VERSION ""

NS_ :

BS_:

BU_: Receiver ChassisBus VehicleBus PartyBus apb ui app aps bms gtwu odin cc cmp cp das dif dir di epas3p epas3s epbl epbr esp fc gtw hvp ibst ocs1p park pcs pmf pmr pm ptc radc rcm2 rcm sccm scm scs tas tpms umc vcfront vcleft vcright vcsec

BO_ 12 ID00CUI_status: 8 VehicleBus
 SG_ UI_audioActive : 1|1@1+ (1,0) [0|1] ""  Receiver
 SG_ UI_autopilotTrial : 12|2@1+ (1,0) [0|3] ""  Receiver
 SG_ UI_bluetoothActive : 2|1@1+ (1,0) [0|1] ""  Receiver
 SG_ UI_cameraActive : 41|1@1+ (1,0) [0|1] ""  Receiver
 SG_ UI_cellActive : 3|1@1+ (1,0) [0|1] ""  Receiver
 SG_ UI_cellConnected : 10|1@1+ (1,0) [0|1] ""  Receiver
 SG_ UI_cellNetworkTechnology : 19|4@1+ (1,0) [0|15] ""  Receiver
 SG_ UI_cellReceiverPower : 24|8@1+ (1,-128) [-128|127] "dB"  Receiver
 SG_ UI_cellSignalBars : 42|3@1+ (1,0) [0|7] ""  Receiver
 SG_ UI_cpuTemperature : 56|8@1- (1,40) [-20|100] "C"  Receiver
 SG_ UI_developmentCar : 40|1@1+ (1,0) [0|1] ""  Receiver
 SG_ UI_displayOn : 5|1@1+ (1,0) [0|1] ""  Receiver
 SG_ UI_displayReady : 4|1@1+ (1,0) [0|1] ""  Receiver
 SG_ UI_factoryReset : 14|2@1+ (1,0) [0|3] ""  Receiver
 SG_ UI_falseTouchCounter : 32|8@1+ (1,0) [0|255] "1"  Receiver
 SG_ UI_gpsActive : 16|1@1+ (1,0) [0|1] ""  Receiver
 SG_ UI_pcbTemperature : 48|8@1- (1,40) [-20|100] "C"  Receiver
 SG_ UI_radioActive : 18|1@1+ (1,0) [0|1] ""  Receiver
 SG_ UI_readyForDrive : 9|1@1+ (1,0) [0|1] ""  Receiver
 SG_ UI_screenshotActive : 17|1@1+ (1,0) [0|1] ""  Receiver
 SG_ UI_systemActive : 8|1@1+ (1,0) [0|1] ""  Receiver
 SG_ UI_touchActive : 0|1@1+ (1,0) [0|1] ""  Receiver
 SG_ UI_vpnActive : 11|1@1+ (1,0) [0|1] ""  Receiver
 SG_ UI_wifiActive : 6|1@1+ (1,0) [0|1] ""  Receiver
 SG_ UI_wifiConnected : 7|1@1+ (1,0) [0|1] ""  Receiver

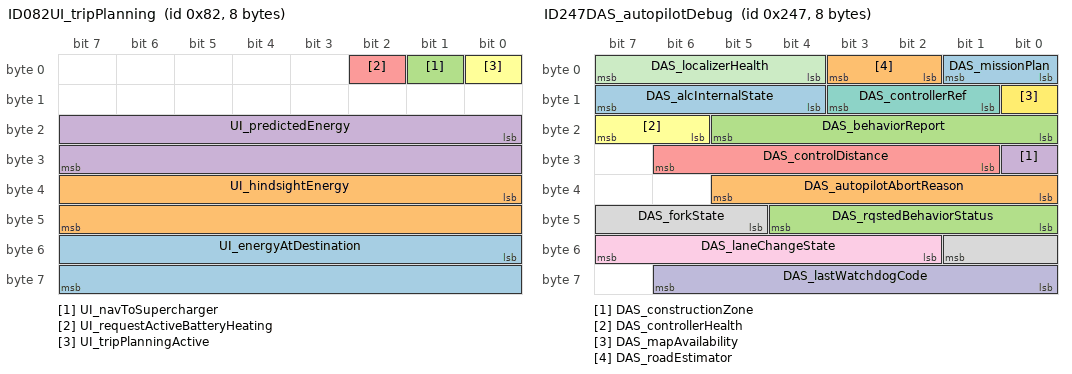
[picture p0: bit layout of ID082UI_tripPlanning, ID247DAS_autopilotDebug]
BO_ 130 ID082UI_tripPlanning: 8 VehicleBus
 SG_ UI_energyAtDestination : 48|16@1- (0.01,0) [-327.67|327.67] "kWh"  Receiver
 SG_ UI_hindsightEnergy : 32|16@1- (0.01,0) [-327.67|327.67] "kWh"  Receiver
 SG_ UI_navToSupercharger : 1|1@1+ (1,0) [0|1] ""  Receiver
 SG_ UI_predictedEnergy : 16|16@1- (0.01,0) [-327.67|327.67] "kWh"  Receiver
 SG_ UI_requestActiveBatteryHeating : 2|1@1+ (1,0) [0|1] ""  Receiver
 SG_ UI_tripPlanningActive : 0|1@1+ (1,0) [0|1] ""  Receiver

BO_ 258 ID102VCLEFT_doorStatus: 8 VehicleBus
 SG_ VCLEFT_frontHandlePWM : 16|7@1+ (1,0) [0|100] "%"  Receiver
 SG_ VCLEFT_frontHandlePulled : 10|1@1+ (1,0) [0|1] ""  Receiver
 SG_ VCLEFT_frontHandlePulledPersist : 62|1@1+ (1,0) [0|1] ""  Receiver
 SG_ VCLEFT_frontIntSwitchPressed : 31|1@1+ (1,0) [0|1] ""  Receiver
 SG_ VCLEFT_frontLatchStatus : 0|4@1+ (1,0) [0|8] ""  Receiver
 SG_ VCLEFT_frontLatchSwitch : 8|1@1+ (1,0) [0|1] ""  Receiver
 SG_ VCLEFT_frontRelActuatorSwitch : 12|1@1+ (1,0) [0|1] ""  Receiver
 SG_ VCLEFT_mirrorDipped : 61|1@1+ (1,0) [0|1] ""  Receiver
 SG_ VCLEFT_mirrorFoldState : 52|3@1+ (1,0) [0|4] ""  Receiver
 SG_ VCLEFT_mirrorHeatState : 58|3@1+ (1,0) [0|4] ""  Receiver
 SG_ VCLEFT_mirrorRecallState : 55|3@1+ (1,0) [0|5] ""  Receiver
 SG_ VCLEFT_mirrorState : 49|3@1+ (1,0) [0|4] ""  Receiver
 SG_ VCLEFT_mirrorTiltXPosition : 33|8@1+ (0.02,0) [0|5] "V"  Receiver
 SG_ VCLEFT_mirrorTiltYPosition : 41|8@1+ (0.02,0) [0|5] "V"  Receiver
 SG_ VCLEFT_rearHandlePWM : 24|7@1+ (1,0) [0|100] "%"  Receiver
 SG_ VCLEFT_rearHandlePulled : 11|1@1+ (1,0) [0|1] ""  Receiver
 SG_ VCLEFT_rearIntSwitchPressed : 32|1@1+ (1,0) [0|1] ""  Receiver
 SG_ VCLEFT_rearLatchStatus : 4|4@1+ (1,0) [0|8] ""  Receiver
 SG_ VCLEFT_rearLatchSwitch : 9|1@1+ (1,0) [0|1] ""  Receiver
 SG_ VCLEFT_rearRelActuatorSwitch : 13|1@1+ (1,0) [0|1] ""  Receiver

BO_ 259 ID103VCRIGHT_doorStatus: 8 VehicleBus
 SG_ VCRIGHT_frontHandlePWM : 14|7@1+ (1,0) [0|100] "%"  Receiver
 SG_ VCRIGHT_frontHandlePulled : 10|1@1+ (1,0) [0|1] ""  Receiver
 SG_ VCRIGHT_frontHandlePulledPersist : 30|1@1+ (1,0) [0|1] ""  Receiver
 SG_ VCRIGHT_frontIntSwitchPressed : 31|1@1+ (1,0) [0|1] ""  Receiver
 SG_ VCRIGHT_frontLatchStatus : 0|4@1+ (1,0) [0|8] ""  Receiver
 SG_ VCRIGHT_frontLatchSwitch : 8|1@1+ (1,0) [0|1] ""  Receiver
 SG_ VCRIGHT_frontRelActuatorSwitch : 12|1@1+ (1,0) [0|1] ""  Receiver
 SG_ VCRIGHT_mirrorDipped : 63|1@1+ (1,0) [0|1] ""  Receiver
 SG_ VCRIGHT_mirrorFoldState : 52|3@1+ (1,0) [0|4] ""  Receiver
 SG_ VCRIGHT_mirrorRecallState : 60|3@1+ (1,0) [0|5] ""  Receiver
 SG_ VCRIGHT_mirrorState : 49|3@1+ (1,0) [0|4] ""  Receiver
 SG_ VCRIGHT_mirrorTiltXPosition : 33|8@1+ (0.02,0) [0|5] "V"  Receiver
 SG_ VCRIGHT_mirrorTiltYPosition : 41|8@1+ (0.02,0) [0|5] "V"  Receiver
 SG_ VCRIGHT_rearHandlePWM : 21|7@1+ (1,0) [0|100] "%"  Receiver
 SG_ VCRIGHT_rearHandlePulled : 11|1@1+ (1,0) [0|1] ""  Receiver
 SG_ VCRIGHT_rearIntSwitchPressed : 32|1@1+ (1,0) [0|1] ""  Receiver
 SG_ VCRIGHT_rearLatchStatus : 4|4@1+ (1,0) [0|8] ""  Receiver
 SG_ VCRIGHT_rearLatchSwitch : 9|1@1+ (1,0) [0|1] ""  Receiver
 SG_ VCRIGHT_rearRelActuatorSwitch : 13|1@1+ (1,0) [0|1] ""  Receiver
 SG_ VCRIGHT_reservedForBackCompat : 28|2@1+ (1,0) [0|3] ""  Receiver
 SG_ VCRIGHT_trunkLatchStatus : 56|4@1+ (1,0) [0|8] ""  Receiver

BO_ 291 ID123UI_alertMatrix1: 8 VehicleBus
 SG_ UI_a001_DriverDoorOpen : 0|1@1+ (1,0) [0|1] ""  Receiver
 SG_ UI_a002_DoorOpen : 1|1@1+ (1,0) [0|1] ""  Receiver
 SG_ UI_a003_TrunkOpen : 2|1@1+ (1,0) [0|1] ""  Receiver
 SG_ UI_a004_FrunkOpen : 3|1@1+ (1,0) [0|1] ""  Receiver
 SG_ UI_a005_HeadlightsOnDoorOpen : 4|1@1+ (1,0) [0|1] ""  Receiver
 SG_ UI_a006_RemoteServiceAlert : 5|1@1+ (1,0) [0|1] ""  Receiver
 SG_ UI_a007_SoftPackConfigMismatch : 6|1@1+ (1,0) [0|1] ""  Receiver
 SG_ UI_a008_TouchScreenError : 7|1@1+ (1,0) [0|1] ""  Receiver
 SG_ UI_a009_SquashfsError : 8|1@1+ (1,0) [0|1] ""  Receiver
 SG_ UI_a010_MapsMissing : 9|1@1+ (1,0) [0|1] ""  Receiver
 SG_ UI_a011_IncorrectMap : 10|1@1+ (1,0) [0|1] ""  Receiver
 SG_ UI_a012_NotOnPrivateProperty : 11|1@1+ (1,0) [0|1] ""  Receiver
 SG_ UI_a013_TPMSHardWarning : 12|1@1+ (1,0) [0|1] ""  Receiver
 SG_ UI_a014_TPMSSoftWarning : 13|1@1+ (1,0) [0|1] ""  Receiver
 SG_ UI_a015_TPMSOverPressureWarning : 14|1@1+ (1,0) [0|1] ""  Receiver
 SG_ UI_a016_TPMSTemperatureWarning : 15|1@1+ (1,0) [0|1] ""  Receiver
 SG_ UI_a017_TPMSSystemFault : 16|1@1+ (1,0) [0|1] ""  Receiver
 SG_ UI_a018_SlipStartOn : 17|1@1+ (1,0) [0|1] ""  Receiver
 SG_ UI_a019_ParkBrakeFault : 18|1@1+ (1,0) [0|1] ""  Receiver
 SG_ UI_a020_SteeringReduced : 19|1@1+ (1,0) [0|1] ""  Receiver
 SG_ UI_a021_RearSeatbeltUnbuckled : 20|1@1+ (1,0) [0|1] ""  Receiver
 SG_ UI_a022_ApeFusesEtc : 21|1@1+ (1,0) [0|1] ""  Receiver
 SG_ UI_a023_CellInternetCheckFailed : 22|1@1+ (1,0) [0|1] ""  Receiver
 SG_ UI_a024_WifiInternetCheckFailed : 23|1@1+ (1,0) [0|1] ""  Receiver
 SG_ UI_a025_WifiOnlineCheckFailed : 24|1@1+ (1,0) [0|1] ""  Receiver
 SG_ UI_a026_ModemResetLoopDetected : 25|1@1+ (1,0) [0|1] ""  Receiver
 SG_ UI_a027_AutoSteerMIA : 26|1@1+ (1,0) [0|1] ""  Receiver
 SG_ UI_a028_FrontTrunkPopupClosed : 27|1@1+ (1,0) [0|1] ""  Receiver
 SG_ UI_a029_ModemMIA : 28|1@1+ (1,0) [0|1] ""  Receiver
 SG_ UI_a030_ModemVMCrash : 29|1@1+ (1,0) [0|1] ""  Receiver
 SG_ UI_a031_BrakeFluidLow : 30|1@1+ (1,0) [0|1] ""  Receiver
 SG_ UI_a032_CellModemRecoveryResets : 31|1@1+ (1,0) [0|1] ""  Receiver
 SG_ UI_a033_ApTrialExpired : 32|1@1+ (1,0) [0|1] ""  Receiver
 SG_ UI_a034_WakeupProblem : 33|1@1+ (1,0) [0|1] ""  Receiver
 SG_ UI_a035_AudioWatchdogKernelError : 34|1@1+ (1,0) [0|1] ""  Receiver
 SG_ UI_a036_AudioWatchdogHfpError : 35|1@1+ (1,0) [0|1] ""  Receiver
 SG_ UI_a037_AudioWatchdogXrunStormEr : 36|1@1+ (1,0) [0|1] ""  Receiver
 SG_ UI_a038_AudioWatchdogA2bI2cLocku : 37|1@1+ (1,0) [0|1] ""  Receiver
 SG_ UI_a039_AudioA2bNeedRediscovery : 38|1@1+ (1,0) [0|1] ""  Receiver
 SG_ UI_a040_HomelinkTransmit : 39|1@1+ (1,0) [0|1] ""  Receiver
 SG_ UI_a041_AudioDmesgXrun : 40|1@1+ (1,0) [0|1] ""  Receiver
 SG_ UI_a042_AudioDmesgRtThrottling : 41|1@1+ (1,0) [0|1] ""  Receiver
 SG_ UI_a043_InvalidMapDataOverride : 42|1@1+ (1,0) [0|1] ""  Receiver
 SG_ UI_a044_AudioDmesgDspException : 43|1@1+ (1,0) [0|1] ""  Receiver
 SG_ UI_a045_ECallNeedsService : 44|1@1+ (1,0) [0|1] ""  Receiver
 SG_ UI_a046_BackupCameraStreamError : 45|1@1+ (1,0) [0|1] ""  Receiver
 SG_ UI_a047_CellRoamingDisallowed : 46|1@1+ (1,0) [0|1] ""  Receiver
 SG_ UI_a048_AudioPremiumAmpCheckFail : 47|1@1+ (1,0) [0|1] ""  Receiver
 SG_ UI_a049_BrakeShiftRequired : 48|1@1+ (1,0) [0|1] ""  Receiver
 SG_ UI_a050_BackupCameraIPUTimeout : 49|1@1+ (1,0) [0|1] ""  Receiver
 SG_ UI_a051_BackupCameraFrameTimeout : 50|1@1+ (1,0) [0|1] ""  Receiver
 SG_ UI_a052_KernelPanicReported : 51|1@1+ (1,0) [0|1] ""  Receiver
 SG_ UI_a053_QtCarExitError : 52|1@1+ (1,0) [0|1] ""  Receiver
 SG_ UI_a054_AudioBoostPowerBad : 53|1@1+ (1,0) [0|1] ""  Receiver
 SG_ UI_a055_ManualECallDisabled : 54|1@1+ (1,0) [0|1] ""  Receiver
 SG_ UI_a056_ManualECallButtonDisconn : 55|1@1+ (1,0) [0|1] ""  Receiver
 SG_ UI_a057_CellAntennaDisconnected : 56|1@1+ (1,0) [0|1] ""  Receiver
 SG_ UI_a058_GPSAntennaDisconnected : 57|1@1+ (1,0) [0|1] ""  Receiver
 SG_ UI_a059_ECallSpeakerDisconnected : 58|1@1+ (1,0) [0|1] ""  Receiver
 SG_ UI_a060_ECallMicDisconnected : 59|1@1+ (1,0) [0|1] ""  Receiver
 SG_ UI_a061_SIMTestFailed : 60|1@1+ (1,0) [0|1] ""  Receiver
 SG_ UI_a062_ENSTestFailed : 61|1@1+ (1,0) [0|1] ""  Receiver
 SG_ UI_a063_CellularTestFailed : 62|1@1+ (1,0) [0|1] ""  Receiver
 SG_ UI_a064_ModemFirmwareTestFailed : 63|1@1+ (1,0) [0|1] ""  Receiver

BO_ 522 ID20AHVP_contactorState: 6 VehicleBus
 SG_ HVP_dcLinkAllowedToEnergize : 36|1@1+ (1,0) [0|1] ""  Receiver
 SG_ HVP_fcContNegativeAuxOpen : 7|1@1+ (1,0) [0|1] ""  Receiver
 SG_ HVP_fcContNegativeState : 12|3@1+ (1,0) [0|7] ""  Receiver
 SG_ HVP_fcContPositiveAuxOpen : 6|1@1+ (1,0) [0|1] ""  Receiver
 SG_ HVP_fcContPositiveState : 16|3@1+ (1,0) [0|7] ""  Receiver
 SG_ HVP_fcContactorSetState : 19|4@1+ (1,0) [0|9] ""  Receiver
 SG_ HVP_fcCtrsClosingAllowed : 29|1@1+ (1,0) [0|1] ""  Receiver
 SG_ HVP_fcCtrsOpenNowRequested : 27|1@1+ (1,0) [0|1] ""  Receiver
 SG_ HVP_fcCtrsOpenRequested : 28|1@1+ (1,0) [0|1] ""  Receiver
 SG_ HVP_fcCtrsRequestStatus : 24|2@1+ (1,0) [0|2] ""  Receiver
 SG_ HVP_fcCtrsResetRequestRequired : 26|1@1+ (1,0) [0|1] ""  Receiver
 SG_ HVP_fcLinkAllowedToEnergize : 44|2@1+ (1,0) [0|2] ""  Receiver
 SG_ HVP_hvilStatus : 40|4@1+ (1,0) [0|9] ""  Receiver
 SG_ HVP_packContNegativeState : 0|3@1+ (1,0) [0|7] ""  Receiver
 SG_ HVP_packContPositiveState : 3|3@1+ (1,0) [0|7] ""  Receiver
 SG_ HVP_packContactorSetState : 8|4@1+ (1,0) [0|9] ""  Receiver
 SG_ HVP_packCtrsClosingAllowed : 35|1@1+ (1,0) [0|1] ""  Receiver
 SG_ HVP_packCtrsOpenNowRequested : 33|1@1+ (1,0) [0|1] ""  Receiver
 SG_ HVP_packCtrsOpenRequested : 34|1@1+ (1,0) [0|1] ""  Receiver
 SG_ HVP_packCtrsRequestStatus : 30|2@1+ (1,0) [0|2] ""  Receiver
 SG_ HVP_packCtrsResetRequestRequired : 32|1@1+ (1,0) [0|1] ""  Receiver
 SG_ HVP_pyroTestInProgress : 37|1@1+ (1,0) [0|1] ""  Receiver

BO_ 583 ID247DAS_autopilotDebug: 8 VehicleBus
 SG_ DAS_alcInternalState : 12|4@1+ (1,0) [0|12] ""  Receiver
 SG_ DAS_autopilotAbortReason : 32|6@1+ (1,0) [0|63] ""  Receiver
 SG_ DAS_behaviorReport : 16|6@1+ (1,0) [1|38] ""  Receiver
 SG_ DAS_constructionZone : 24|1@1+ (1,0) [0|1] ""  Receiver
 SG_ DAS_controlDistance : 25|6@1+ (2,0) [0|126] "m"  Receiver
 SG_ DAS_controllerHealth : 22|2@1+ (1,0) [0|3] ""  Receiver
 SG_ DAS_controllerRef : 9|3@1+ (1,0) [0|6] ""  Receiver
 SG_ DAS_forkState : 45|5@1+ (1,0) [0|27] ""  Receiver
 SG_ DAS_laneChangeState : 50|6@1+ (1,0) [0|63] ""  Receiver
 SG_ DAS_lastWatchdogCode : 56|7@1+ (1,0) [0|79] ""  Receiver
 SG_ DAS_localizerHealth : 4|4@1+ (1,0) [0|8] ""  Receiver
 SG_ DAS_mapAvailability : 8|1@1+ (1,0) [0|1] ""  Receiver
 SG_ DAS_missionPlan : 0|2@1+ (1,0) [0|3] ""  Receiver
 SG_ DAS_roadEstimator : 2|2@1+ (1,0) [0|3] ""  Receiver
 SG_ DAS_rqstedBehaviorStatus : 40|5@1+ (1,0) [0|22] ""  Receiver

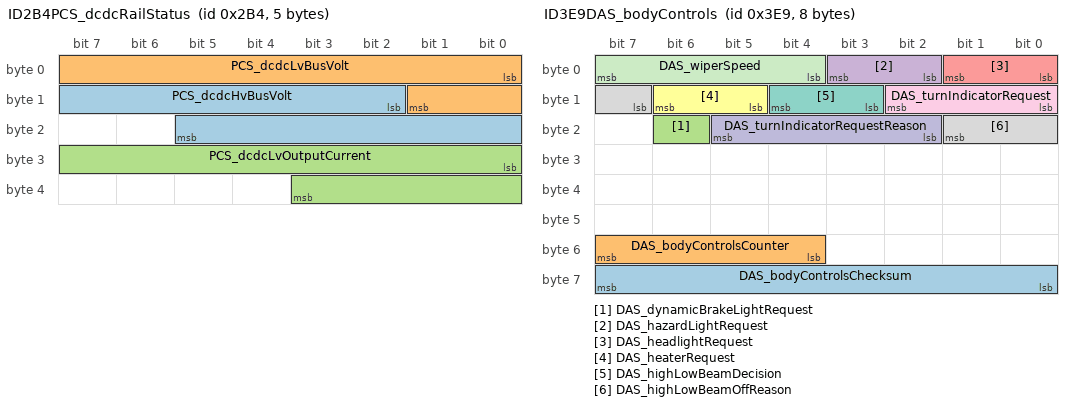
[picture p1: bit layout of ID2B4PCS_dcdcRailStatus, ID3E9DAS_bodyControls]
BO_ 692 ID2B4PCS_dcdcRailStatus: 5 VehicleBus
 SG_ PCS_dcdcHvBusVolt : 10|12@1+ (0.146484375,0) [0|599.853515625] "V"  Receiver
 SG_ PCS_dcdcLvBusVolt : 0|10@1+ (0.0390625,0) [0|39.9609375] "V"  Receiver
 SG_ PCS_dcdcLvOutputCurrent : 24|12@1+ (0.1,0) [0|400] "A"  Receiver

BO_ 1013 ID3F5VCFRONT_lighting: 8 VehicleBus
 SG_ VCFRONT_DRLLeftStatus : 36|2@1+ (1,0) [0|3] ""  Receiver
 SG_ VCFRONT_DRLRightStatus : 38|2@1+ (1,0) [0|3] ""  Receiver
 SG_ VCFRONT_ambientLightingBrightnes : 8|8@1+ (0.5,0) [0|127] "%"  Receiver
 SG_ VCFRONT_approachLightingRequest : 25|1@1+ (1,0) [0|1] ""  Receiver
 SG_ VCFRONT_courtesyLightingRequest : 24|1@1+ (1,0) [0|1] ""  Receiver
 SG_ VCFRONT_fogLeftStatus : 40|2@1+ (1,0) [0|3] ""  Receiver
 SG_ VCFRONT_fogRightStatus : 42|2@1+ (1,0) [0|3] ""  Receiver
 SG_ VCFRONT_hazardLightRequest : 4|4@1+ (1,0) [0|8] ""  Receiver
 SG_ VCFRONT_hazardSwitchBacklight : 27|1@1+ (1,0) [0|1] ""  Receiver
 SG_ VCFRONT_highBeamLeftStatus : 32|2@1+ (1,0) [0|3] ""  Receiver
 SG_ VCFRONT_highBeamRightStatus : 34|2@1+ (1,0) [0|3] ""  Receiver
 SG_ VCFRONT_highBeamSwitchActive : 58|1@1+ (1,0) [0|1] ""  Receiver
 SG_ VCFRONT_indicatorLeftRequest : 0|2@1+ (1,0) [0|2] ""  Receiver
 SG_ VCFRONT_indicatorRightRequest : 2|2@1+ (1,0) [0|2] ""  Receiver
 SG_ VCFRONT_lowBeamLeftStatus : 28|2@1+ (1,0) [0|3] ""  Receiver
 SG_ VCFRONT_lowBeamRightStatus : 30|2@1+ (1,0) [0|3] ""  Receiver
 SG_ VCFRONT_lowBeamsCalibrated : 62|1@1+ (1,0) [0|1] ""  Receiver
 SG_ VCFRONT_lowBeamsOnForDRL : 61|1@1+ (1,0) [0|1] ""  Receiver
 SG_ VCFRONT_parkLeftStatus : 54|2@1+ (1,0) [0|3] ""  Receiver
 SG_ VCFRONT_parkRightStatus : 56|2@1+ (1,0) [0|3] ""  Receiver
 SG_ VCFRONT_seeYouHomeLightingReq : 26|1@1+ (1,0) [0|1] ""  Receiver
 SG_ VCFRONT_sideMarkersStatus : 44|2@1+ (1,0) [0|3] ""  Receiver
 SG_ VCFRONT_sideRepeaterLeftStatus : 46|2@1+ (1,0) [0|3] ""  Receiver
 SG_ VCFRONT_sideRepeaterRightStatus : 48|2@1+ (1,0) [0|3] ""  Receiver
 SG_ VCFRONT_simLatchingStalk : 59|2@1+ (1,0) [0|3] ""  Receiver
 SG_ VCFRONT_switchLightingBrightness : 16|8@1+ (0.5,0) [0|127] "%"  Receiver
 SG_ VCFRONT_turnSignalLeftStatus : 50|2@1+ (1,0) [0|3] ""  Receiver
 SG_ VCFRONT_turnSignalRightStatus : 52|2@1+ (1,0) [0|3] ""  Receiver

BO_ 1001 ID3E9DAS_bodyControls: 8 VehicleBus
 SG_ DAS_bodyControlsChecksum : 56|8@1+ (1,0) [0|255] ""  Receiver
 SG_ DAS_bodyControlsCounter : 52|4@1+ (1,0) [0|15] ""  Receiver
 SG_ DAS_dynamicBrakeLightRequest : 22|1@1+ (1,0) [0|1] ""  Receiver
 SG_ DAS_hazardLightRequest : 2|2@1+ (1,0) [0|3] ""  Receiver
 SG_ DAS_headlightRequest : 0|2@1+ (1,0) [0|3] ""  Receiver
 SG_ DAS_heaterRequest : 13|2@1+ (1,0) [0|2] ""  Receiver
 SG_ DAS_highLowBeamDecision : 11|2@1+ (1,0) [0|3] ""  Receiver
 SG_ DAS_highLowBeamOffReason : 15|3@1+ (1,0) [0|5] ""  Receiver
 SG_ DAS_turnIndicatorRequest : 8|3@1+ (1,0) [0|4] ""  Receiver
 SG_ DAS_turnIndicatorRequestReason : 18|4@1+ (1,0) [0|12] ""  Receiver
 SG_ DAS_wiperSpeed : 4|4@1+ (1,0) [0|15] ""  Receiver

BO_ 611 ID263VCRIGHT_logging10Hz: 8 VehicleBus
 SG_ VCRIGHT_logging10HzIndex M : 0|2@1+ (1,0) [0|3] ""  Receiver
 SG_ VCRIGHT_hvacCabinHumidityLevel m2 : 55|8@1+ (1,0) [0|100] "%"  Receiver
 SG_ VCRIGHT_hvacEstimateWindshieldRH m2 : 39|8@1+ (1,0) [0|150] "%"  Receiver
 SG_ VCRIGHT_hvacFilterLifeDetectActi m2 : 2|1@1+ (1,0) [0|1] ""  Receiver
 SG_ VCRIGHT_hvacFlashFoggingDetected m2 : 63|1@1+ (1,0) [0|1] ""  Receiver
 SG_ VCRIGHT_hvacFoggingRiskLevel m2 : 47|8@1+ (1,0) [0|100] "%"  Receiver
 SG_ VCRIGHT_hvacIntakeActuatorState m2 : 22|2@1+ (1,0) [0|2] ""  Receiver
 SG_ VCRIGHT_hvacIntakeOperationMode m2 : 9|1@1+ (1,0) [0|1] ""  Receiver
 SG_ VCRIGHT_hvacIntakePosition m1 : 56|8@1+ (0.4,0) [0|100] "%"  Receiver
 SG_ VCRIGHT_hvacIntakeTarget m0 : 56|8@1+ (0.4,0) [0|100] "%"  Receiver
 SG_ VCRIGHT_hvacLHBleedActuatorState m2 : 10|2@1+ (1,0) [0|2] ""  Receiver
 SG_ VCRIGHT_hvacLHBleedOperationMode m2 : 3|1@1+ (1,0) [0|1] ""  Receiver
 SG_ VCRIGHT_hvacLHBleedPosition m1 : 8|8@1+ (0.4,0) [0|100] "%"  Receiver
 SG_ VCRIGHT_hvacLHBleedTarget m0 : 8|8@1+ (0.4,0) [0|100] "%"  Receiver
 SG_ VCRIGHT_hvacLHVaneActuatorState m2 : 14|2@1+ (1,0) [0|2] ""  Receiver
 SG_ VCRIGHT_hvacLHVaneOperationMode m2 : 5|1@1+ (1,0) [0|1] ""  Receiver
 SG_ VCRIGHT_hvacLHVanePosition m1 : 24|8@1+ (0.4,0) [0|100] "%"  Receiver
 SG_ VCRIGHT_hvacLHVaneTarget m0 : 24|8@1+ (0.4,0) [0|100] "%"  Receiver
 SG_ VCRIGHT_hvacLowerModeActState m2 : 20|2@1+ (1,0) [0|2] ""  Receiver
 SG_ VCRIGHT_hvacLowerModeOpMode m2 : 8|1@1+ (1,0) [0|1] ""  Receiver
 SG_ VCRIGHT_hvacLowerModePosition m1 : 48|8@1+ (0.4,0) [0|100] "%"  Receiver
 SG_ VCRIGHT_hvacLowerModeTarget m0 : 48|8@1+ (0.4,0) [0|100] "%"  Receiver
 SG_ VCRIGHT_hvacModelInitStatus m2 : 24|3@1+ (1,0) [0|5] ""  Receiver
 SG_ VCRIGHT_hvacRHBleedActuatorState m2 : 12|2@1+ (1,0) [0|2] ""  Receiver
 SG_ VCRIGHT_hvacRHBleedOperationMode m2 : 4|1@1+ (1,0) [0|1] ""  Receiver
 SG_ VCRIGHT_hvacRHBleedPosition m1 : 16|8@1+ (0.4,0) [0|100] "%"  Receiver
 SG_ VCRIGHT_hvacRHBleedTarget m0 : 16|8@1+ (0.4,0) [0|100] "%"  Receiver
 SG_ VCRIGHT_hvacRHVaneActuatorState m2 : 16|2@1+ (1,0) [0|2] ""  Receiver
 SG_ VCRIGHT_hvacRHVaneOperationMode m2 : 6|1@1+ (1,0) [0|1] ""  Receiver
 SG_ VCRIGHT_hvacRHVanePosition m1 : 32|8@1+ (0.4,0) [0|100] "%"  Receiver
 SG_ VCRIGHT_hvacRHVaneTarget m0 : 32|8@1+ (0.4,0) [0|100] "%"  Receiver
 SG_ VCRIGHT_hvacUpperModeActState m2 : 18|2@1+ (1,0) [0|2] ""  Receiver
 SG_ VCRIGHT_hvacUpperModeOpMode m2 : 7|1@1+ (1,0) [0|1] ""  Receiver
 SG_ VCRIGHT_hvacUpperModePosition m1 : 40|8@1+ (0.4,0) [0|100] "%"  Receiver
 SG_ VCRIGHT_hvacUpperModeTarget m0 : 40|8@1+ (0.4,0) [0|100] "%"  Receiver
 SG_ VCRIGHT_timeLeftToCabinModelInit m2 : 32|7@1+ (1,0) [0|127] ""  Receiver

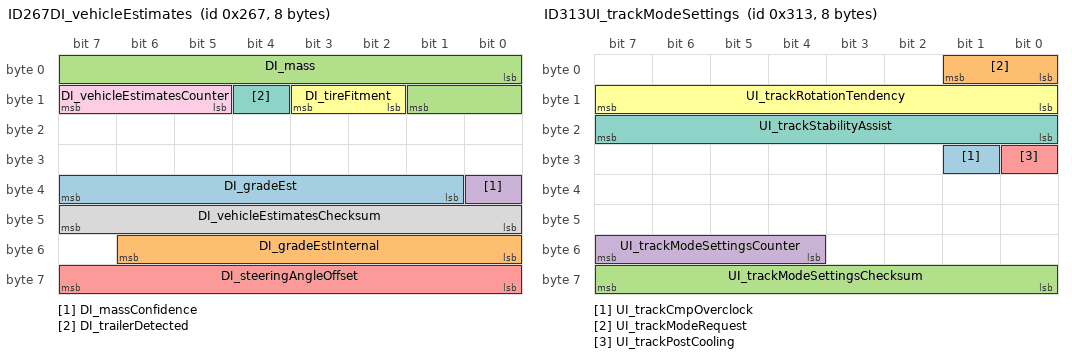
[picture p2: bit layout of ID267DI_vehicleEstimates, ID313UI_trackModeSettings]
BO_ 615 ID267DI_vehicleEstimates: 8 VehicleBus
 SG_ DI_gradeEst : 33|7@1- (1,0) [-40|40] "%"  Receiver
 SG_ DI_gradeEstInternal : 48|7@1- (1,0) [-40|40] "%"  Receiver
 SG_ DI_mass : 0|10@1+ (5,1900) [1900|7010] "kg"  Receiver
 SG_ DI_massConfidence : 32|1@1+ (1,0) [0|1] ""  Receiver
 SG_ DI_steeringAngleOffset : 56|8@1- (0.2,0) [-25.6|25.4] "Deg"  Receiver
 SG_ DI_tireFitment : 10|2@1+ (1,0) [0|3] ""  Receiver
 SG_ DI_trailerDetected : 12|1@1+ (1,0) [0|1] ""  Receiver
 SG_ DI_vehicleEstimatesChecksum : 40|8@1+ (1,0) [0|255] ""  Receiver
 SG_ DI_vehicleEstimatesCounter : 13|3@1+ (1,0) [0|7] ""  Receiver

BO_ 642 ID282VCLEFT_hvacBlowerFeedback: 8 VehicleBus
 SG_ VCLEFT_blowerIndex M : 0|2@1+ (1,0) [0|1] ""  Receiver
 SG_ VCLEFT_hvacBlowerCBCCtrlState m1 : 58|3@1+ (1,0) [0|4] ""  Receiver
 SG_ VCLEFT_hvacBlowerCBCEstState m1 : 54|4@1+ (1,0) [0|14] ""  Receiver
 SG_ VCLEFT_hvacBlowerEnabled m0 : 2|1@1+ (1,0) [0|1] ""  Receiver
 SG_ VCLEFT_hvacBlowerFETTemp m0 : 44|7@1+ (1.5,-40) [-40|149] "C"  Receiver
 SG_ VCLEFT_hvacBlowerFault m0 : 59|1@1+ (1,0) [0|1] ""  Receiver
 SG_ VCLEFT_hvacBlowerIPhase0 m1 : 10|8@1+ (0.2,0) [0|50] "A"  Receiver
 SG_ VCLEFT_hvacBlowerIPhase1 m1 : 18|8@1+ (0.2,0) [0|50] "A"  Receiver
 SG_ VCLEFT_hvacBlowerIPhase2 m1 : 26|8@1+ (0.2,0) [0|50] "A"  Receiver
 SG_ VCLEFT_hvacBlowerITerm m0 : 51|7@1+ (0.05,-1.5) [-1.5|4.5] "Nm"  Receiver
 SG_ VCLEFT_hvacBlowerInitd m0 : 58|1@1+ (1,0) [0|1] ""  Receiver
 SG_ VCLEFT_hvacBlowerLimitFETTemps m0 : 60|1@1+ (1,0) [0|1] ""  Receiver
 SG_ VCLEFT_hvacBlowerOutputDuty m0 : 3|7@1+ (1,0) [0|100] "%"  Receiver
 SG_ VCLEFT_hvacBlowerPowerOn m0 : 61|1@1+ (1,0) [0|1] ""  Receiver
 SG_ VCLEFT_hvacBlowerRPMActual m0 : 20|10@1+ (10,0) [0|10000] "rpm"  Receiver
 SG_ VCLEFT_hvacBlowerRPMTarget m0 : 10|10@1+ (10,0) [0|10000] "rpm"  Receiver
 SG_ VCLEFT_hvacBlowerRs m1 : 2|8@1+ (0.25,0) [0|60] "mOhm"  Receiver
 SG_ VCLEFT_hvacBlowerRsOnlineActive m1 : 61|1@1+ (1,0) [0|1] ""  Receiver
 SG_ VCLEFT_hvacBlowerSpiError m0 : 62|1@1+ (1,0) [0|1] ""  Receiver
 SG_ VCLEFT_hvacBlowerTorque m0 : 34|10@1+ (0.006,-1.5) [-1.5|4.5] "Nm"  Receiver
 SG_ VCLEFT_hvacBlower_IO_CBC_HEAD m1 : 34|4@1+ (1,0) [0|15] ""  Receiver
 SG_ VCLEFT_hvacBlower_IO_CBC_Status m1 : 43|1@1+ (1,0) [0|1] ""  Receiver
 SG_ VCLEFT_hvacBlower_IO_CBC_TAIL m1 : 38|4@1+ (1,0) [0|15] ""  Receiver
 SG_ VCLEFT_hvacBlower_IO_CBC_TAIL_va m1 : 42|1@1+ (1,0) [0|1] ""  Receiver
 SG_ VCLEFT_hvacBlower_IO_CBC_numUart m1 : 46|8@1+ (1,0) [0|255] ""  Receiver

BO_ 787 ID313UI_trackModeSettings: 8 VehicleBus
 SG_ UI_trackCmpOverclock : 25|1@1+ (1,0) [0|1] ""  Receiver
 SG_ UI_trackModeRequest : 0|2@1+ (1,0) [0|2] ""  Receiver
 SG_ UI_trackModeSettingsChecksum : 56|8@1+ (1,0) [0|255] ""  Receiver
 SG_ UI_trackModeSettingsCounter : 52|4@1+ (1,0) [0|15] ""  Receiver
 SG_ UI_trackPostCooling : 24|1@1+ (1,0) [0|1] ""  Receiver
 SG_ UI_trackRotationTendency : 8|8@1+ (0.5,0) [0|100] "%"  Receiver
 SG_ UI_trackStabilityAssist : 16|8@1+ (0.5,0) [0|100] "%"  Receiver

BO_ 821 ID335RearDIinfo: 8 VehicleBus
 SG_ DIR_infoIndex M : 0|8@1+ (1,0) [0|255] ""  Receiver
 SG_ DIR_FPGA_version m16 : 48|8@1+ (1,0) [0|255] ""  Receiver
 SG_ DIR_appGitHash m17 : 8|56@1+ (1,0) [0|7.20575940379279E+016] ""  Receiver
 SG_ DIR_applicationCrc m13 : 32|32@1+ (1,0) [0|4294967295] ""  Receiver
 SG_ DIR_assemblyId m11 : 24|8@1+ (1,0) [0|255] ""  Receiver
 SG_ DIR_bootGitHash m18 : 8|56@1+ (1,0) [0|7.20575940379279E+016] ""  Receiver
 SG_ DIR_bootloaderCrc m20 : 32|32@1+ (1,0) [0|4294967295] ""  Receiver
 SG_ DIR_buildConfigurationId m10 : 16|16@1+ (1,0) [0|65535] ""  Receiver
 SG_ DIR_buildType m10 : 8|3@1+ (1,0) [0|4] ""  Receiver
 SG_ DIR_componentId m10 : 48|16@1+ (1,0) [0|65535] ""  Receiver
 SG_ DIR_hardwareId m10 : 32|8@1+ (1,0) [0|252] ""  Receiver
 SG_ DIR_infoBootLdUdsProtocolVersion m20 : 8|8@1+ (1,0) [0|255] ""  Receiver
 SG_ DIR_oilPumpAppCrc m16 : 16|32@1+ (1,0) [0|4294967295] ""  Receiver
 SG_ DIR_oilPumpBuildType m16 : 8|3@1+ (1,0) [0|4] ""  Receiver
 SG_ DIR_pcbaId m11 : 16|8@1+ (1,0) [0|255] ""  Receiver
 SG_ DIR_platformTyp m19 : 8|8@1+ (1,0) [0|255] ""  Receiver
 SG_ DIR_subUsageId m11 : 48|16@1+ (1,0) [0|65535] ""  Receiver
 SG_ DIR_subcomponentGitHash m31 : 8|56@1+ (1,0) [0|7.20575940379279E+016] ""  Receiver
 SG_ DIR_usageId m11 : 32|16@1+ (1,0) [0|65535] ""  Receiver

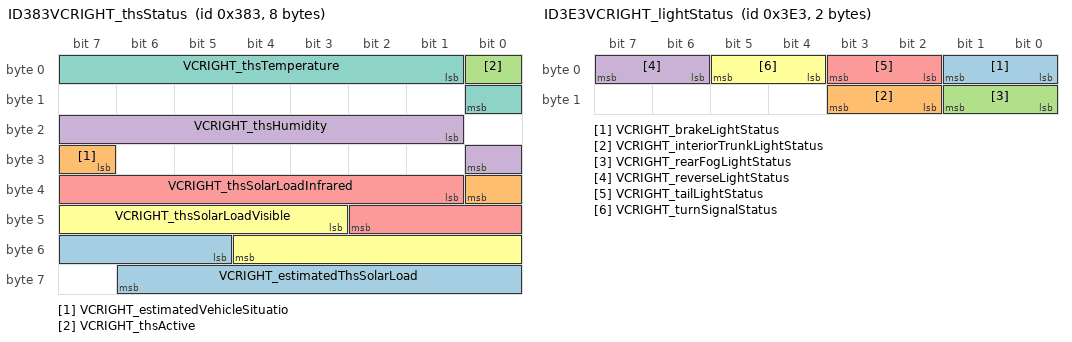
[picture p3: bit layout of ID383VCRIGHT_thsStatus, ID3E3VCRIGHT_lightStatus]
BO_ 899 ID383VCRIGHT_thsStatus: 8 VehicleBus
 SG_ VCRIGHT_estimatedThsSolarLoad : 53|10@1+ (1,0) [0|1022] "W/m2"  Receiver
 SG_ VCRIGHT_estimatedVehicleSituatio : 31|2@1+ (1,0) [0|2] ""  Receiver
 SG_ VCRIGHT_thsActive : 0|1@1+ (1,0) [0|1] ""  Receiver
 SG_ VCRIGHT_thsHumidity : 17|8@1+ (1,0) [0|100] "%"  Receiver
 SG_ VCRIGHT_thsSolarLoadInfrared : 33|10@1+ (1,0) [0|1022] "W/m2"  Receiver
 SG_ VCRIGHT_thsSolarLoadVisible : 43|10@1+ (1,0) [0|1022] "W/m2"  Receiver
 SG_ VCRIGHT_thsTemperature : 1|8@1- (1,-40) [-40|150] "C"  Receiver

BO_ 915 ID393VCRIGHT_epbmDebug: 8 VehicleBus
 SG_ VCRIGHT_epbmDebugIndex M : 0|2@1+ (1,0) [0|2] ""  Receiver
 SG_ VCRIGHT_cdpEnumDummy m1 : 24|2@1+ (1,0) [0|2] ""  Receiver
 SG_ VCRIGHT_epbFaultStatus m0 : 57|2@1+ (1,0) [0|3] ""  Receiver
 SG_ VCRIGHT_epbMotorCurrent m0 : 6|11@1+ (0.01,0) [0|20.47] "A"  Receiver
 SG_ VCRIGHT_epbSummonState m0 : 44|3@1+ (1,0) [0|6] ""  Receiver
 SG_ VCRIGHT_epbUnitStatus m0 : 50|5@1+ (1,0) [0|22] ""  Receiver
 SG_ VCRIGHT_epbmApplyVoltage m0 : 17|11@1+ (0.01,0) [0|20.47] "A"  Receiver
 SG_ VCRIGHT_epbmCaliperState m0 : 2|3@1+ (1,0) [0|6] ""  Receiver
 SG_ VCRIGHT_epbmDynApplyingAllowed m1 : 10|1@1+ (1,0) [0|1] ""  Receiver
 SG_ VCRIGHT_epbmDynamicAllowed m1 : 3|1@1+ (1,0) [0|1] ""  Receiver
 SG_ VCRIGHT_epbmFaultAllowed m1 : 12|1@1+ (1,0) [0|1] ""  Receiver
 SG_ VCRIGHT_epbmFaultStatus m0 : 55|2@1+ (1,0) [0|3] ""  Receiver
 SG_ VCRIGHT_epbmMotorEnabled m0 : 5|1@1+ (1,0) [0|1] ""  Receiver
 SG_ VCRIGHT_epbmOpenAllowed m1 : 2|1@1+ (1,0) [0|1] ""  Receiver
 SG_ VCRIGHT_epbmParkAllowed m1 : 4|1@1+ (1,0) [0|1] ""  Receiver
 SG_ VCRIGHT_epbmParkingAllowed m1 : 9|1@1+ (1,0) [0|1] ""  Receiver
 SG_ VCRIGHT_epbmReleaseVoltage m0 : 28|11@1+ (0.01,0) [0|20.47] "A"  Receiver
 SG_ VCRIGHT_epbmReleasingAllowed m1 : 11|1@1+ (1,0) [0|1] ""  Receiver
 SG_ VCRIGHT_epbmServiceAllowed m1 : 6|1@1+ (1,0) [0|1] ""  Receiver
 SG_ VCRIGHT_epbmStartAllowed m1 : 5|1@1+ (1,0) [0|1] ""  Receiver
 SG_ VCRIGHT_epbmSummonAllowed m1 : 13|1@1+ (1,0) [0|1] ""  Receiver
 SG_ VCRIGHT_epbmSummonParkAllowed m1 : 14|1@1+ (1,0) [0|1] ""  Receiver
 SG_ VCRIGHT_epbmSummonReleaseAllowed m1 : 15|1@1+ (1,0) [0|1] ""  Receiver
 SG_ VCRIGHT_epbmSummonState m0 : 47|3@1+ (1,0) [0|6] ""  Receiver
 SG_ VCRIGHT_epbmSystemStatus m0 : 59|4@1+ (1,0) [0|8] ""  Receiver
 SG_ VCRIGHT_epbmUnknownAllowed m1 : 17|1@1+ (1,0) [0|1] ""  Receiver
 SG_ VCRIGHT_epbmWinchAllowed m1 : 7|1@1+ (1,0) [0|1] ""  Receiver
 SG_ VCRIGHT_epbmWinchReleaseAllowed m1 : 8|1@1+ (1,0) [0|1] ""  Receiver
 SG_ VCRIGHT_summonActiveAllowed m1 : 20|1@1+ (1,0) [0|1] ""  Receiver
 SG_ VCRIGHT_summonArmedAllowed m1 : 19|1@1+ (1,0) [0|1] ""  Receiver
 SG_ VCRIGHT_summonCompleteAllowed m1 : 21|1@1+ (1,0) [0|1] ""  Receiver
 SG_ VCRIGHT_summonFaultAllowed m1 : 22|1@1+ (1,0) [0|1] ""  Receiver
 SG_ VCRIGHT_summonFaultReason m0 : 39|5@1+ (1,0) [0|28] ""  Receiver
 SG_ VCRIGHT_summonIdleAllowed m1 : 18|1@1+ (1,0) [0|1] ""  Receiver
 SG_ VCRIGHT_summonInitAllowed m1 : 16|1@1+ (1,0) [0|1] ""  Receiver
 SG_ VCRIGHT_summonUnavailableAllowed m1 : 23|1@1+ (1,0) [0|1] ""  Receiver

BO_ 963 ID3C3VCRIGHT_switchStatus: 7 VehicleBus
 SG_ VCRIGHT_2RowSeatReclineSwitch : 54|1@1+ (1,0) [0|1] ""  Receiver
 SG_ VCRIGHT_btnWindowAutoDownRF : 27|1@1+ (1,0) [0|1] ""  Receiver
 SG_ VCRIGHT_btnWindowAutoDownRR : 31|1@1+ (1,0) [0|1] ""  Receiver
 SG_ VCRIGHT_btnWindowAutoUpRF : 25|1@1+ (1,0) [0|1] ""  Receiver
 SG_ VCRIGHT_btnWindowAutoUpRR : 29|1@1+ (1,0) [0|1] ""  Receiver
 SG_ VCRIGHT_btnWindowDownRF : 26|1@1+ (1,0) [0|1] ""  Receiver
 SG_ VCRIGHT_btnWindowDownRR : 30|1@1+ (1,0) [0|1] ""  Receiver
 SG_ VCRIGHT_btnWindowSwPackAutoDwnLF : 35|1@1+ (1,0) [0|1] ""  Receiver
 SG_ VCRIGHT_btnWindowSwPackAutoDwnLR : 39|1@1+ (1,0) [0|1] ""  Receiver
 SG_ VCRIGHT_btnWindowSwPackAutoDwnRR : 52|1@1+ (1,0) [0|1] ""  Receiver
 SG_ VCRIGHT_btnWindowSwPackAutoUpLF : 33|1@1+ (1,0) [0|1] ""  Receiver
 SG_ VCRIGHT_btnWindowSwPackAutoUpLR : 37|1@1+ (1,0) [0|1] ""  Receiver
 SG_ VCRIGHT_btnWindowSwPackAutoUpRR : 50|1@1+ (1,0) [0|1] ""  Receiver
 SG_ VCRIGHT_btnWindowSwPackDownLF : 34|1@1+ (1,0) [0|1] ""  Receiver
 SG_ VCRIGHT_btnWindowSwPackDownLR : 38|1@1+ (1,0) [0|1] ""  Receiver
 SG_ VCRIGHT_btnWindowSwPackDownRR : 51|1@1+ (1,0) [0|1] ""  Receiver
 SG_ VCRIGHT_btnWindowSwPackUpLF : 32|1@1+ (1,0) [0|1] ""  Receiver
 SG_ VCRIGHT_btnWindowSwPackUpLR : 36|1@1+ (1,0) [0|1] ""  Receiver
 SG_ VCRIGHT_btnWindowSwPackUpRR : 49|1@1+ (1,0) [0|1] ""  Receiver
 SG_ VCRIGHT_btnWindowUpRF : 24|1@1+ (1,0) [0|1] ""  Receiver
 SG_ VCRIGHT_btnWindowUpRR : 28|1@1+ (1,0) [0|1] ""  Receiver
 SG_ VCRIGHT_frontBuckleSwitch : 40|2@1+ (1,0) [0|3] ""  Receiver
 SG_ VCRIGHT_frontOccupancySwitch : 42|2@1+ (1,0) [0|3] ""  Receiver
 SG_ VCRIGHT_frontSeatBackrestBack : 12|2@1+ (1,0) [0|3] ""  Receiver
 SG_ VCRIGHT_frontSeatBackrestForward : 14|2@1+ (1,0) [0|3] ""  Receiver
 SG_ VCRIGHT_frontSeatLiftDown : 8|2@1+ (1,0) [0|3] ""  Receiver
 SG_ VCRIGHT_frontSeatLiftUp : 10|2@1+ (1,0) [0|3] ""  Receiver
 SG_ VCRIGHT_frontSeatLumbarDown : 16|2@1+ (1,0) [0|3] ""  Receiver
 SG_ VCRIGHT_frontSeatLumbarIn : 20|2@1+ (1,0) [0|3] ""  Receiver
 SG_ VCRIGHT_frontSeatLumbarOut : 22|2@1+ (1,0) [0|3] ""  Receiver
 SG_ VCRIGHT_frontSeatLumbarUp : 18|2@1+ (1,0) [0|3] ""  Receiver
 SG_ VCRIGHT_frontSeatTiltDown : 4|2@1+ (1,0) [0|3] ""  Receiver
 SG_ VCRIGHT_frontSeatTiltUp : 6|2@1+ (1,0) [0|3] ""  Receiver
 SG_ VCRIGHT_frontSeatTrackBack : 0|2@1+ (1,0) [0|3] ""  Receiver
 SG_ VCRIGHT_frontSeatTrackForward : 2|2@1+ (1,0) [0|3] ""  Receiver
 SG_ VCRIGHT_liftgateShutfaceSwitchPr : 53|1@1+ (1,0) [0|1] ""  Receiver
 SG_ VCRIGHT_rearCenterBuckleSwitch : 44|2@1+ (1,0) [0|3] ""  Receiver
 SG_ VCRIGHT_rearRightBuckleSwitch : 46|2@1+ (1,0) [0|3] ""  Receiver
 SG_ VCRIGHT_trunkExtReleasePressed : 48|1@1+ (1,0) [0|1] ""  Receiver

BO_ 995 ID3E3VCRIGHT_lightStatus: 2 VehicleBus
 SG_ VCRIGHT_brakeLightStatus : 0|2@1+ (1,0) [0|3] ""  Receiver
 SG_ VCRIGHT_interiorTrunkLightStatus : 10|2@1+ (1,0) [0|3] ""  Receiver
 SG_ VCRIGHT_rearFogLightStatus : 8|2@1+ (1,0) [0|3] ""  Receiver
 SG_ VCRIGHT_reverseLightStatus : 6|2@1+ (1,0) [0|3] ""  Receiver
 SG_ VCRIGHT_tailLightStatus : 2|2@1+ (1,0) [0|3] ""  Receiver
 SG_ VCRIGHT_turnSignalStatus : 4|2@1+ (1,0) [0|3] ""  Receiver

BO_ 1622 ID656FrontDIinfo: 8 VehicleBus
 SG_ DIF_infoIndex M : 0|8@1+ (1,0) [0|255] ""  Receiver
 SG_ DIF_FPGA_version m16 : 48|8@1+ (1,0) [0|255] ""  Receiver
 SG_ DIF_appGitHash m17 : 8|56@1+ (1,0) [0|7.20575940379279E+016] ""  Receiver
 SG_ DIF_applicationCrc m13 : 32|32@1+ (1,0) [0|4294967295] ""  Receiver
 SG_ DIF_assemblyId m11 : 24|8@1+ (1,0) [0|255] ""  Receiver
 SG_ DIF_bootGitHash m18 : 8|56@1+ (1,0) [0|7.20575940379279E+016] ""  Receiver
 SG_ DIF_bootloaderCrc m20 : 32|32@1+ (1,0) [0|4294967295] ""  Receiver
 SG_ DIF_buildConfigurationId m10 : 16|16@1+ (1,0) [0|65535] ""  Receiver
 SG_ DIF_buildType m10 : 8|3@1+ (1,0) [0|4] ""  Receiver
 SG_ DIF_componentId m10 : 48|16@1+ (1,0) [0|65535] ""  Receiver
 SG_ DIF_hardwareId m10 : 32|8@1+ (1,0) [0|252] ""  Receiver
 SG_ DIF_infoBootLdUdsProtocolVersion m20 : 8|8@1+ (1,0) [0|255] ""  Receiver
 SG_ DIF_oilPumpAppCrc m16 : 16|32@1+ (1,0) [0|4294967295] ""  Receiver
 SG_ DIF_oilPumpBuildType m16 : 8|3@1+ (1,0) [0|4] ""  Receiver
 SG_ DIF_pcbaId m11 : 16|8@1+ (1,0) [0|255] ""  Receiver
 SG_ DIF_platformTyp m19 : 8|8@1+ (1,0) [0|255] ""  Receiver
 SG_ DIF_subUsageId m11 : 48|16@1+ (1,0) [0|65535] ""  Receiver
 SG_ DIF_subcomponentGitHash m31 : 8|56@1+ (1,0) [0|7.20575940379279E+016] ""  Receiver
 SG_ DIF_usageId m11 : 32|16@1+ (1,0) [0|65535] ""  Receiver

BO_ 768 ID300BMS_info: 8 VehicleBus
 SG_ BMS_infoIndex M : 0|8@1+ (1,0) [0|255] ""  Receiver
 SG_ BMS_appCrc m13 : 32|32@1+ (1,0) [0|4294967295] ""  Receiver
 SG_ BMS_appGitHash m17 : 8|56@1+ (1,0) [0|7.20575940379279E+016] ""  Receiver
 SG_ BMS_assemblyId m11 : 24|8@1+ (1,0) [0|255] ""  Receiver
 SG_ BMS_bootCrc m20 : 32|32@1+ (1,0) [0|4294967295] ""  Receiver
 SG_ BMS_bootGitHash m18 : 8|56@1+ (1,0) [0|7.20575940379279E+016] ""  Receiver
 SG_ BMS_bootUdsProtoVersion m20 : 8|8@1+ (1,0) [0|255] ""  Receiver
 SG_ BMS_buildConfigId m10 : 16|16@1+ (1,0) [0|65535] ""  Receiver
 SG_ BMS_buildType m10 : 8|3@1+ (1,0) [0|4] ""  Receiver
 SG_ BMS_componentId m10 : 48|16@1+ (1,0) [0|65535] ""  Receiver
 SG_ BMS_hardwareId m10 : 32|16@1+ (1,0) [0|65535] ""  Receiver
 SG_ BMS_pcbaId m11 : 16|8@1+ (1,0) [0|255] ""  Receiver
 SG_ BMS_platformType m13 : 8|8@1+ (1,0) [0|255] ""  Receiver
 SG_ BMS_subUsageId m11 : 48|16@1+ (1,0) [0|65535] ""  Receiver
 SG_ BMS_usageId m11 : 32|16@1+ (1,0) [0|65535] ""  Receiver

BO_ 530 ID212BMS_status: 8 VehicleBus
 SG_ BMS_activeHeatingWorthwhile : 5|1@1+ (1,0) [0|1] ""  Receiver
 SG_ BMS_chargeRequest : 29|1@1+ (1,0) [0|1] ""  Receiver
 SG_ BMS_chargeRetryCount : 51|3@1+ (1,0) [0|7] ""  Receiver
 SG_ BMS_chgPowerAvailable : 40|11@1+ (0.125,0) [0|255.75] "kW"  Receiver
 SG_ BMS_contactorState : 8|3@1+ (1,0) [0|6] ""  Receiver
 SG_ BMS_cpMiaOnHvs : 6|1@1+ (1,0) [0|1] ""  Receiver
 SG_ BMS_diLimpRequest : 36|1@1+ (1,0) [0|1] ""  Receiver
 SG_ BMS_ecuLogUploadRequest : 14|2@1+ (1,0) [0|3] ""  Receiver
 SG_ BMS_hvState : 16|3@1+ (1,0) [0|6] ""  Receiver
 SG_ BMS_hvacPowerRequest : 0|1@1+ (1,0) [0|1] ""  Receiver
 SG_ BMS_isolationResistance : 19|10@1+ (10,0) [0|10000] "kOhm"  Receiver
 SG_ BMS_keepWarmRequest : 30|1@1+ (1,0) [0|1] ""  Receiver
 SG_ BMS_notEnoughPowerForDrive : 1|1@1+ (1,0) [0|1] ""  Receiver
 SG_ BMS_notEnoughPowerForSupport : 2|1@1+ (1,0) [0|1] ""  Receiver
 SG_ BMS_okToShipByAir : 37|1@1+ (1,0) [0|1] ""  Receiver
 SG_ BMS_okToShipByLand : 38|1@1+ (1,0) [0|1] ""  Receiver
 SG_ BMS_pcsPwmEnabled : 7|1@1+ (1,0) [0|1] ""  Receiver
 SG_ BMS_preconditionAllowed : 3|1@1+ (1,0) [0|1] ""  Receiver
 SG_ BMS_smStateRequest : 56|4@1+ (1,0) [0|9] ""  Receiver
 SG_ BMS_state : 32|4@1+ (1,0) [0|10] ""  Receiver
 SG_ BMS_uiChargeStatus : 11|3@1+ (1,0) [0|5] ""  Receiver
 SG_ BMS_updateAllowed : 4|1@1+ (1,0) [0|1] ""  Receiver

BO_ 946 ID3B2BMS_log2: 8 VehicleBus
 SG_ BMS_log2MuxId M : 0|5@1+ (1,0) [0|25] ""  Receiver
 SG_ BMS_100HzTask_avgExecTime m9 : 6|14@1+ (1,0) [0|16383] "us"  Receiver
 SG_ BMS_100HzTask_maxExecTime m9 : 32|14@1+ (1,0) [0|16383] "us"  Receiver
 SG_ BMS_10HzTask_avgExecTime m8 : 6|17@1+ (1,0) [0|131071] "us"  Receiver
 SG_ BMS_10HzTask_maxExecTime m8 : 32|17@1+ (1,0) [0|131071] "us"  Receiver
 SG_ BMS_1HzTask_avgExecTime m7 : 6|20@1+ (1,0) [0|1048575] "us"  Receiver
 SG_ BMS_1HzTask_maxExecTime m7 : 32|20@1+ (1,0) [0|1048575] "us"  Receiver
 SG_ BMS_1kHzTask_avgExecTime m9 : 20|11@1+ (1,0) [0|2047] "us"  Receiver
 SG_ BMS_1kHzTask_maxExecTime m9 : 48|11@1+ (1,0) [0|2047] "us"  Receiver
 SG_ BMS_ahChargeTotal m6 : 8|24@1+ (0.1,0) [0|1677721.5] "Ah"  Receiver
 SG_ BMS_ahDischargeTotal m6 : 32|24@1+ (0.1,0) [0|1677721.5] "Ah"  Receiver
 SG_ BMS_cacAvg m0 : 6|13@1+ (0.1,0) [0|819.1] "Ah"  Receiver
 SG_ BMS_cacMax m0 : 40|13@1+ (0.1,0) [0|819.1] "Ah"  Receiver
 SG_ BMS_cacMaxBrickId m0 : 56|7@1+ (1,1) [1|128] ""  Receiver
 SG_ BMS_cacMaxKalmanError m1 : 44|10@1+ (0.01,0) [0|10] "Ah"  Receiver
 SG_ BMS_cacMin m0 : 19|13@1+ (0.1,0) [0|819.1] "Ah"  Receiver
 SG_ BMS_cacMinBrickId m0 : 32|7@1+ (1,1) [1|128] ""  Receiver
 SG_ BMS_cacMinDeltaAh m23 : 26|11@1- (0.5,0) [-512|511.5] "Ah"  Receiver
 SG_ BMS_cacMinLowerBoundEst m1 : 5|13@1+ (0.1,0) [0|819.1] "Ah"  Receiver
 SG_ BMS_cacMinRawEstimate m1 : 18|13@1+ (0.1,0) [0|819.1] "Ah"  Receiver
 SG_ BMS_cacMinSocByOcvEnd m23 : 16|10@1+ (0.1,0) [0|100] "%"  Receiver
 SG_ BMS_cacMinSocByOcvStart m23 : 6|10@1+ (0.1,0) [0|100] "%"  Receiver
 SG_ BMS_cacMinUpdateAhError m23 : 37|9@1- (0.05,0) [-12.8|12.75] "Ah"  Receiver
 SG_ BMS_cacMinUpperBoundEst m1 : 31|13@1+ (0.1,0) [0|819.1] "Ah"  Receiver
 SG_ BMS_capacityImbalancePct m1 : 54|10@1+ (0.1,0) [0|102.3] "%"  Receiver
 SG_ BMS_chargeCurrentLimitMode m5 : 32|3@1+ (1,0) [0|6] ""  Receiver
 SG_ BMS_chargeNeededReason m5 : 35|3@1+ (1,0) [0|6] ""  Receiver
 SG_ BMS_chgEndBatteryChargeRequest m3 : 28|1@1+ (1,0) [0|1] ""  Receiver
 SG_ BMS_chgEndBmsHvChargeStatus m3 : 16|3@1+ (1,0) [0|7] ""  Receiver
 SG_ BMS_chgEndChargeState m3 : 12|3@1+ (1,0) [0|7] ""  Receiver
 SG_ BMS_chgEndCpHvChargeStatus m3 : 19|3@1+ (1,0) [0|6] ""  Receiver
 SG_ BMS_chgEndCpShutdownRequest m3 : 24|2@1+ (1,0) [0|2] ""  Receiver
 SG_ BMS_chgEndDcEvseCompatible m3 : 29|1@1+ (1,0) [0|1] ""  Receiver
 SG_ BMS_chgEndDisableUnderFailure m3 : 30|1@1+ (1,0) [0|1] ""  Receiver
 SG_ BMS_chgEndEvseChargeType m3 : 6|2@1+ (1,0) [0|2] ""  Receiver
 SG_ BMS_chgEndPcsHvChargeStatus m3 : 22|2@1+ (1,0) [0|3] ""  Receiver
 SG_ BMS_chgEndPcsShutdownRequest m3 : 26|2@1+ (1,0) [0|2] ""  Receiver
 SG_ BMS_chgRequestTerminatedCount m3 : 8|4@1+ (1,0) [0|15] ""  Receiver
 SG_ BMS_cpChargeStatus m5 : 60|3@1+ (1,0) [0|5] ""  Receiver
 SG_ BMS_currentReg_targetI m5 : 49|11@1+ (0.5,0) [0|1023.5] "A"  Receiver
 SG_ BMS_dynamicEnergyBuffer m22 : 30|10@1+ (0.1,0) [0|102.2] "KWh"  Receiver
 SG_ BMS_energyReserveAvg m20 : 48|16@1+ (0.001,0) [0|65.535] "V"  Receiver
 SG_ BMS_energyReserveMax m20 : 32|16@1+ (0.001,0) [0|65.535] "V"  Receiver
 SG_ BMS_energyReserveMin m20 : 16|16@1+ (0.001,0) [0|65.535] "V"  Receiver
 SG_ BMS_fcLinkTestDecayTime m21 : 8|10@1+ (2,0) [0|2044] "mS"  Receiver
 SG_ BMS_fcLinkTestTimeSinceLastRun m21 : 18|12@1+ (0.01758241758,0) [0|71.99] "Hours"  Receiver
 SG_ BMS_floodPortState1 m2 : 10|3@1+ (1,0) [0|4] ""  Receiver
 SG_ BMS_floodPortState2 m2 : 13|3@1+ (1,0) [0|4] ""  Receiver
 SG_ BMS_floodPortV1 m2 : 16|16@1+ (0.001,0) [0|65.535] "V"  Receiver
 SG_ BMS_floodPortV2 m2 : 32|16@1+ (0.001,0) [0|65.535] "V"  Receiver
 SG_ BMS_hvChain_iLimit m19 : 9|14@1+ (0.128,0) [0|2096.896] "A"  Receiver
 SG_ BMS_hvChain_limitingState m19 : 24|5@1+ (1,0) [0|31] ""  Receiver
 SG_ BMS_hvChain_limitingStateTempera m19 : 32|16@1- (0.01,0) [-327.68|327.67] "C"  Receiver
 SG_ BMS_hvChain_useLeakyBucket m19 : 8|1@1+ (1,0) [0|1] ""  Receiver
 SG_ BMS_idealEnergyFloor m22 : 20|10@1+ (0.1,0) [0|102.2] "KWh"  Receiver
 SG_ BMS_loadReg_output m5 : 6|11@1- (0.1,0) [-102.4|102.3] "A"  Receiver
 SG_ BMS_maxDcCurrentAvailable m5 : 38|11@1+ (0.5,0) [0|1023.5] "A"  Receiver
 SG_ BMS_negCtrCommonModeRejError m18 : 6|13@1- (2.442592959E-005,0) [-0.1|0.1] "-"  Receiver
 SG_ BMS_negCtrCommonModeRejErrorConf m18 : 19|13@1+ (1.22100107191684,0) [0|10000] "-"  Receiver
 SG_ BMS_negCtrDeviationConfidenceMax m15 : 45|13@1+ (0.000122100107192,0) [0|1] "-"  Receiver
 SG_ BMS_negCtrDeviationConfidenceMin m15 : 32|13@1+ (0.000122100107192,0) [0|1] "-"  Receiver
 SG_ BMS_negCtrDeviationFiltConfMax m16 : 45|13@1+ (0.000122100107192,0) [0|1] "-"  Receiver
 SG_ BMS_negCtrDeviationFiltConfMin m16 : 32|13@1+ (0.000122100107192,0) [0|1] "-"  Receiver
 SG_ BMS_negCtrDeviationFiltMax m16 : 19|13@1- (0.001221299164314,0) [-5|5] "V"  Receiver
 SG_ BMS_negCtrDeviationFiltMin m16 : 6|13@1- (0.001221299164314,0) [-5|5] "V"  Receiver
 SG_ BMS_negCtrDeviationMax m15 : 19|13@1- (0.001221299164314,0) [-5|5] "V"  Receiver
 SG_ BMS_negCtrDeviationMin m15 : 6|13@1- (0.001221299164314,0) [-5|5] "V"  Receiver
 SG_ BMS_negCtrDropCorrectedFiltMax m17 : 45|13@1- (0.001221299164314,0) [-5|5] "V"  Receiver
 SG_ BMS_negCtrDropCorrectedFiltMin m17 : 32|13@1- (0.001221299164314,0) [-5|5] "V"  Receiver
 SG_ BMS_negCtrDropCorrectedMax m17 : 19|13@1- (0.001221299164314,0) [-5|5] "V"  Receiver
 SG_ BMS_negCtrDropCorrectedMin m17 : 6|13@1- (0.001221299164314,0) [-5|5] "V"  Receiver
 SG_ BMS_negCtrOffsetError m18 : 32|13@1- (0.001221299164314,0) [-5|5] "V"  Receiver
 SG_ BMS_negCtrOffsetErrorConf m18 : 45|13@1+ (0.000122100107192,0) [0|1] "-"  Receiver
 SG_ BMS_negCtrResistance m10 : 32|13@1- (2.442598329E-006,0) [-0.01|0.01] "Ohm"  Receiver
 SG_ BMS_negCtrResistanceConfidence m10 : 45|13@1+ (12.2100107191684,0) [0|100000] "-"  Receiver
 SG_ BMS_offsetReg_output m5 : 17|14@1- (0.1,0) [-819.2|819.1] "A"  Receiver
 SG_ BMS_packRestTime m22 : 8|12@1+ (0.01758241758,0) [0|71.99] "Hours"  Receiver
 SG_ BMS_pcsPrechargeRequestActive m21 : 30|1@1+ (1,0) [0|1] ""  Receiver
 SG_ BMS_pcsPrechargeTargetVoltage m21 : 32|16@1- (0.1,0) [-3276.8|3276.7] "V"  Receiver
 SG_ BMS_posCtrCommonModeRejError m14 : 6|13@1- (2.4425983286E-005,0) [-0.1|0.1] "-"  Receiver
 SG_ BMS_posCtrCommonModeRejErrorConf m14 : 19|13@1+ (1.22100107191684,0) [0|10000] "-"  Receiver
 SG_ BMS_posCtrDeviationConfidenceMax m11 : 45|13@1+ (0.000122100107192,0) [0|1] "-"  Receiver
 SG_ BMS_posCtrDeviationConfidenceMin m11 : 32|13@1+ (0.000122100107192,0) [0|1] "-"  Receiver
 SG_ BMS_posCtrDeviationFiltConfMax m12 : 45|13@1+ (0.000122100107192,0) [0|1] "-"  Receiver
 SG_ BMS_posCtrDeviationFiltConfMin m12 : 32|13@1+ (0.000122100107192,0) [0|1] "-"  Receiver
 SG_ BMS_posCtrDeviationFiltMax m12 : 19|13@1- (0.001221299164314,0) [-5|5] "V"  Receiver
 SG_ BMS_posCtrDeviationFiltMin m12 : 6|13@1- (0.001221299164314,0) [-5|5] "V"  Receiver
 SG_ BMS_posCtrDeviationMax m11 : 19|13@1- (0.001221299164314,0) [-5|5] "V"  Receiver
 SG_ BMS_posCtrDeviationMin m11 : 6|13@1- (0.001221299164314,0) [-5|5] "V"  Receiver
 SG_ BMS_posCtrDropCorrectedFiltMax m13 : 45|13@1- (0.001221299164314,0) [-5|5] "V"  Receiver
 SG_ BMS_posCtrDropCorrectedFiltMin m13 : 32|13@1- (0.001221299164314,0) [-5|5] "V"  Receiver
 SG_ BMS_posCtrDropCorrectedMax m13 : 19|13@1- (0.001221299164314,0) [-5|5] "V"  Receiver
 SG_ BMS_posCtrDropCorrectedMin m13 : 6|13@1- (0.001221299164314,0) [-5|5] "V"  Receiver
 SG_ BMS_posCtrOffsetError m14 : 32|13@1- (0.001221299164314,0) [-5|5] "V"  Receiver
 SG_ BMS_posCtrOffsetErrorConf m14 : 45|13@1+ (0.000122100107192,0) [0|1] "-"  Receiver
 SG_ BMS_posCtrResistance m10 : 6|13@1- (2.442598329E-006,0) [-0.01|0.01] "Ohm"  Receiver
 SG_ BMS_posCtrResistanceConfidence m10 : 19|13@1+ (12.2100107191684,0) [0|100000] "-"  Receiver
 SG_ BMS_vChangeWindowChangeInitV m24 : 38|12@1+ (0.002,0) [0|5] "V"  Receiver
 SG_ BMS_vChangeWindowChangeIsOutlier m24 : 50|1@1+ (1,0) [0|1] ""  Receiver
 SG_ BMS_vChangeWindowMaxVChange m24 : 25|6@1+ (0.0025,0) [0|0.15] "V"  Receiver
 SG_ BMS_vChangeWindowMaxVChangeId m24 : 31|7@1+ (1,1) [1|128] ""  Receiver
 SG_ BMS_vChangeWindowMinBrickV m24 : 6|12@1+ (0.002,0) [0|5] "V"  Receiver
 SG_ BMS_vChangeWindowMinBrickVId m24 : 18|7@1+ (1,1) [1|128] ""  Receiver
 SG_ BMS_vChangeWindowNumOutlierChang m24 : 58|6@1+ (1,0) [0|63] ""  Receiver
 SG_ BMS_vChangeWindowTimeAfterWake m24 : 51|7@1+ (0.1,0) [0|12] "sec"  Receiver
 SG_ BMS_vshTestMaxDeltaV m4 : 16|8@1+ (0.002,0) [0|0.5] "V"  Receiver
 SG_ BMS_vshTestMaxDeltaVBrickID m4 : 24|7@1+ (1,1) [1|128] ""  Receiver
 SG_ BMS_vshTestMinDeltaV m4 : 32|8@1+ (0.002,0) [0|0.5] "V"  Receiver
 SG_ BMS_vshTestMinDeltaVBrickID m4 : 40|7@1+ (1,1) [1|128] ""  Receiver
 SG_ BMS_maxSocChange m25 : 5|11@1- (0.1,0) [-100|100] "%"  Receiver
 SG_ BMS_maxSocChangeBrickId m25 : 16|7@1+ (1,1) [1|108] ""  Receiver
 SG_ BMS_socChangeSocByOcvMax m25 : 34|10@1+ (0.1,0) [0|100] "%"  Receiver
 SG_ BMS_socChangeSocByOcvMin m25 : 24|10@1+ (0.1,0) [0|100] "%"  Receiver

BO_ 800 ID320BMS_alertMatrix: 8 VehicleBus
 SG_ BMS_matrixIndex M : 0|4@1+ (1,0) [0|15] ""  Receiver
 SG_ BMS_a001_Pack_Config_Mismatch m0 : 4|1@1+ (1,0) [0|1] ""  Receiver
 SG_ BMS_a007_SW_Slowed_Chg_Batt_Cold m0 : 10|1@1+ (1,0) [0|1] ""  Receiver
 SG_ BMS_a016_Pack_Module_Id_Mismatch m0 : 19|1@1+ (1,0) [0|1] ""  Receiver
 SG_ BMS_a017_SW_Brick_OV m0 : 20|1@1+ (1,0) [0|1] ""  Receiver
 SG_ BMS_a018_SW_Brick_UV m0 : 21|1@1+ (1,0) [0|1] ""  Receiver
 SG_ BMS_a019_SW_Module_OT m0 : 22|1@1+ (1,0) [0|1] ""  Receiver
 SG_ BMS_a021_SW_Dr_Limits_Regulation m0 : 24|1@1+ (1,0) [0|1] ""  Receiver
 SG_ BMS_a022_SW_Over_Current m0 : 25|1@1+ (1,0) [0|1] ""  Receiver
 SG_ BMS_a023_SW_Stack_OV m0 : 26|1@1+ (1,0) [0|1] ""  Receiver
 SG_ BMS_a024_SW_Islanded_Brick m0 : 27|1@1+ (1,0) [0|1] ""  Receiver
 SG_ BMS_a025_SW_PwrBalance_Anomaly m0 : 28|1@1+ (1,0) [0|1] ""  Receiver
 SG_ BMS_a026_SW_HFCurrent_Anomaly m0 : 29|1@1+ (1,0) [0|1] ""  Receiver
 SG_ BMS_a034_SW_Passive_Isolation m0 : 37|1@1+ (1,0) [0|1] ""  Receiver
 SG_ BMS_a035_SW_Isolation m0 : 38|1@1+ (1,0) [0|1] ""  Receiver
 SG_ BMS_a036_SW_HvpHvilFault m0 : 39|1@1+ (1,0) [0|1] ""  Receiver
 SG_ BMS_a037_SW_Flood_Port_Open m0 : 40|1@1+ (1,0) [0|1] ""  Receiver
 SG_ BMS_a039_SW_DC_Link_Over_Voltage m0 : 42|1@1+ (1,0) [0|1] ""  Receiver
 SG_ BMS_a040_SW_Watch_Dog_HW_Trigger m0 : 43|1@1+ (1,0) [0|1] ""  Receiver
 SG_ BMS_a041_SW_Destructive_Reset_So m0 : 44|1@1+ (1,0) [0|1] ""  Receiver
 SG_ BMS_a042_SW_MPU_Error m0 : 45|1@1+ (1,0) [0|1] ""  Receiver
 SG_ BMS_a043_SW_Watch_Dog_Reset m0 : 46|1@1+ (1,0) [0|1] ""  Receiver
 SG_ BMS_a044_SW_Assertion m0 : 47|1@1+ (1,0) [0|1] ""  Receiver
 SG_ BMS_a045_SW_Exception m0 : 48|1@1+ (1,0) [0|1] ""  Receiver
 SG_ BMS_a046_SW_Task_Stack_Usage m0 : 49|1@1+ (1,0) [0|1] ""  Receiver
 SG_ BMS_a047_SW_Task_Stack_Overflow m0 : 50|1@1+ (1,0) [0|1] ""  Receiver
 SG_ BMS_a048_SW_Log_Upload_Request m0 : 51|1@1+ (1,0) [0|1] ""  Receiver
 SG_ BMS_a050_SW_Brick_Voltage_MIA m0 : 53|1@1+ (1,0) [0|1] ""  Receiver
 SG_ BMS_a051_SW_HVC_Vref_Bad m0 : 54|1@1+ (1,0) [0|1] ""  Receiver
 SG_ BMS_a052_SW_PCS_MIA m0 : 55|1@1+ (1,0) [0|1] ""  Receiver
 SG_ BMS_a054_SW_Ver_Supply_Fault m0 : 57|1@1+ (1,0) [0|1] ""  Receiver
 SG_ BMS_a055_SW_HvChain_Model_Fault m0 : 58|1@1+ (1,0) [0|1] ""  Receiver
 SG_ BMS_a056_SW_Standby_Supply_Fault m0 : 59|1@1+ (1,0) [0|1] ""  Receiver
 SG_ BMS_a057_SW_Bandolier_Model_Warn m0 : 60|1@1+ (1,0) [0|1] ""  Receiver
 SG_ BMS_a058_SW_Bandolier_Model_Rese m0 : 61|1@1+ (1,0) [0|1] ""  Receiver
 SG_ BMS_a059_SW_Pack_Voltage_Sensing m0 : 62|1@1+ (1,0) [0|1] ""  Receiver
 SG_ BMS_a060_SW_Leakage_Test_Failure m0 : 63|1@1+ (1,0) [0|1] ""  Receiver
 SG_ BMS_a061_SW_BrickV_Change m1 : 4|1@1+ (1,0) [0|1] ""  Receiver
 SG_ BMS_a062_SW_BrickV_Imbalance m1 : 5|1@1+ (1,0) [0|1] ""  Receiver
 SG_ BMS_a063_SW_ChargePort_Fault m1 : 6|1@1+ (1,0) [0|1] ""  Receiver
 SG_ BMS_a064_SW_SOC_Imbalance m1 : 7|1@1+ (1,0) [0|1] ""  Receiver
 SG_ BMS_a065_SW_CAC_Imbalance m1 : 8|1@1+ (1,0) [0|1] ""  Receiver
 SG_ BMS_a069_SW_Low_Power m1 : 12|1@1+ (1,0) [0|1] ""  Receiver
 SG_ BMS_a071_SW_SM_TransCon_Not_Met m1 : 14|1@1+ (1,0) [0|1] ""  Receiver
 SG_ BMS_a075_SW_Chg_Disable_Failure m1 : 18|1@1+ (1,0) [0|1] ""  Receiver
 SG_ BMS_a076_SW_Dch_While_Charging m1 : 19|1@1+ (1,0) [0|1] ""  Receiver
 SG_ BMS_a077_SW_Charger_Regulation m1 : 20|1@1+ (1,0) [0|1] ""  Receiver
 SG_ BMS_a080_SW_Pack_Ctr_Impedance m1 : 23|1@1+ (1,0) [0|1] ""  Receiver
 SG_ BMS_a081_SW_Ctr_Close_Blocked m1 : 24|1@1+ (1,0) [0|1] ""  Receiver
 SG_ BMS_a082_SW_Ctr_Force_Open m1 : 25|1@1+ (1,0) [0|1] ""  Receiver
 SG_ BMS_a083_SW_Ctr_Close_Failure m1 : 26|1@1+ (1,0) [0|1] ""  Receiver
 SG_ BMS_a084_SW_Sleep_Wake_Aborted m1 : 27|1@1+ (1,0) [0|1] ""  Receiver
 SG_ BMS_a087_SW_Feim_Test_Blocked m1 : 30|1@1+ (1,0) [0|1] ""  Receiver
 SG_ BMS_a088_SW_VcFront_MIA_InDrive m1 : 31|1@1+ (1,0) [0|1] ""  Receiver
 SG_ BMS_a089_SW_VcFront_MIA m1 : 32|1@1+ (1,0) [0|1] ""  Receiver
 SG_ BMS_a090_SW_Gateway_MIA m1 : 33|1@1+ (1,0) [0|1] ""  Receiver
 SG_ BMS_a091_SW_ChargePort_MIA m1 : 34|1@1+ (1,0) [0|1] ""  Receiver
 SG_ BMS_a092_SW_ChargePort_Mia_On_Hv m1 : 35|1@1+ (1,0) [0|1] ""  Receiver
 SG_ BMS_a094_SW_Drive_Inverter_MIA m1 : 37|1@1+ (1,0) [0|1] ""  Receiver
 SG_ BMS_a098_SW_BMB_Data_Integrity_L m1 : 41|1@1+ (1,0) [0|1] ""  Receiver
 SG_ BMS_a099_SW_BMB_Communication m1 : 42|1@1+ (1,0) [0|1] ""  Receiver
 SG_ BMS_a105_SW_One_Module_Tsense m1 : 48|1@1+ (1,0) [0|1] ""  Receiver
 SG_ BMS_a106_SW_All_Module_Tsense m1 : 49|1@1+ (1,0) [0|1] ""  Receiver
 SG_ BMS_a107_SW_Stack_Voltage_MIA m1 : 50|1@1+ (1,0) [0|1] ""  Receiver
 SG_ BMS_a121_SW_NVRAM_Config_Error m2 : 4|1@1+ (1,0) [0|1] ""  Receiver
 SG_ BMS_a122_SW_BMS_Therm_Irrational m2 : 5|1@1+ (1,0) [0|1] ""  Receiver
 SG_ BMS_a123_SW_Internal_Isolation m2 : 6|1@1+ (1,0) [0|1] ""  Receiver
 SG_ BMS_a126_SW_Thermistor_Failure m2 : 9|1@1+ (1,0) [0|1] ""  Receiver
 SG_ BMS_a127_SW_shunt_SNA m2 : 10|1@1+ (1,0) [0|1] ""  Receiver
 SG_ BMS_a128_SW_shunt_MIA m2 : 11|1@1+ (1,0) [0|1] ""  Receiver
 SG_ BMS_a129_SW_VSH_Failure m2 : 12|1@1+ (1,0) [0|1] ""  Receiver
 SG_ BMS_a130_IO_CAN_Error m2 : 13|1@1+ (1,0) [0|1] ""  Receiver
 SG_ BMS_a131_Bleed_FET_Failure m2 : 14|1@1+ (1,0) [0|1] ""  Receiver
 SG_ BMS_a132_HW_BMB_OTP_Uncorrctbl m2 : 15|1@1+ (1,0) [0|1] ""  Receiver
 SG_ BMS_a134_SW_Delayed_Ctr_Off m2 : 17|1@1+ (1,0) [0|1] ""  Receiver
 SG_ BMS_a135_HW_BMB_Diagnostics_Fail m2 : 18|1@1+ (1,0) [0|1] ""  Receiver
 SG_ BMS_a136_SW_Module_OT_Warning m2 : 19|1@1+ (1,0) [0|1] ""  Receiver
 SG_ BMS_a137_SW_Brick_UV_Warning m2 : 20|1@1+ (1,0) [0|1] ""  Receiver
 SG_ BMS_a138_SW_Brick_OV_Warning m2 : 21|1@1+ (1,0) [0|1] ""  Receiver
 SG_ BMS_a139_SW_DC_Link_V_Irrational m2 : 22|1@1+ (1,0) [0|1] ""  Receiver
 SG_ BMS_a141_SW_BMB_Status_Warning m2 : 24|1@1+ (1,0) [0|1] ""  Receiver
 SG_ BMS_a143_SW_CAC_Change m2 : 26|1@1+ (1,0) [0|1] ""  Receiver
 SG_ BMS_a144_Hvp_Config_Mismatch m2 : 27|1@1+ (1,0) [0|1] ""  Receiver
 SG_ BMS_a145_SW_SOC_Change m2 : 28|1@1+ (1,0) [0|1] ""  Receiver
 SG_ BMS_a146_SW_Brick_Overdischarged m2 : 29|1@1+ (1,0) [0|1] ""  Receiver
 SG_ BMS_a149_SW_Missing_Config_Block m2 : 32|1@1+ (1,0) [0|1] ""  Receiver
 SG_ BMS_a151_SW_external_isolation m2 : 34|1@1+ (1,0) [0|1] ""  Receiver
 SG_ BMS_a155_SW_Weak_short_impedence m2 : 38|1@1+ (1,0) [0|1] ""  Receiver
 SG_ BMS_a156_SW_BMB_Vref_bad m2 : 39|1@1+ (1,0) [0|1] ""  Receiver
 SG_ BMS_a158_SW_HVP_HVI_Comms m2 : 41|1@1+ (1,0) [0|1] ""  Receiver
 SG_ BMS_a159_SW_HVP_ECU_Error m2 : 42|1@1+ (1,0) [0|1] ""  Receiver
 SG_ BMS_a160_SW_FC_Ctr_Clean_Failed m2 : 43|1@1+ (1,0) [0|1] ""  Receiver
 SG_ BMS_a161_SW_DI_Open_Request m2 : 44|1@1+ (1,0) [0|1] ""  Receiver
 SG_ BMS_a162_SW_No_Power_For_Support m2 : 45|1@1+ (1,0) [0|1] ""  Receiver
 SG_ BMS_a163_SW_Contactor_Mismatch m2 : 46|1@1+ (1,0) [0|1] ""  Receiver
 SG_ BMS_a164_SW_Uncontrolled_Regen m2 : 47|1@1+ (1,0) [0|1] ""  Receiver
 SG_ BMS_a165_SW_Pack_Partial_Weld m2 : 48|1@1+ (1,0) [0|1] ""  Receiver
 SG_ BMS_a166_SW_Pack_Full_Weld m2 : 49|1@1+ (1,0) [0|1] ""  Receiver
 SG_ BMS_a167_SW_FC_Partial_Weld m2 : 50|1@1+ (1,0) [0|1] ""  Receiver
 SG_ BMS_a168_SW_FC_Full_Weld m2 : 51|1@1+ (1,0) [0|1] ""  Receiver
 SG_ BMS_a169_SW_FC_Pack_Weld m2 : 52|1@1+ (1,0) [0|1] ""  Receiver
 SG_ BMS_a170_SW_Limp_Mode m2 : 53|1@1+ (1,0) [0|1] ""  Receiver
 SG_ BMS_a171_SW_Stack_Voltage_Sense m2 : 54|1@1+ (1,0) [0|1] ""  Receiver
 SG_ BMS_a174_SW_Charge_Failure m2 : 57|1@1+ (1,0) [0|1] ""  Receiver
 SG_ BMS_a176_SW_GracefulPowerOff m2 : 59|1@1+ (1,0) [0|1] ""  Receiver
 SG_ BMS_a178_SW_Uncontrolled_Regen_P m2 : 61|1@1+ (1,0) [0|1] ""  Receiver
 SG_ BMS_a179_SW_Hvp_12V_Fault m2 : 62|1@1+ (1,0) [0|1] ""  Receiver
 SG_ BMS_a180_SW_ECU_reset_blocked m2 : 63|1@1+ (1,0) [0|1] ""  Receiver

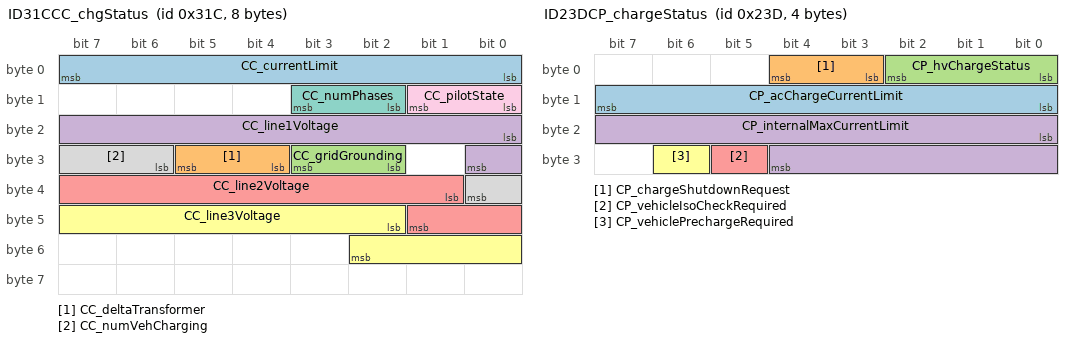
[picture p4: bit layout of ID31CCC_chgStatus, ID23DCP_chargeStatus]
BO_ 796 ID31CCC_chgStatus: 8 VehicleBus
 SG_ CC_currentLimit : 0|8@1+ (0.5,0) [0|127.5] "A"  Receiver
 SG_ CC_deltaTransformer : 28|2@1+ (1,0) [0|3] ""  Receiver
 SG_ CC_gridGrounding : 26|2@1+ (1,0) [0|2] ""  Receiver
 SG_ CC_line1Voltage : 16|9@1+ (1,0) [0|511] "V"  Receiver
 SG_ CC_line2Voltage : 33|9@1+ (1,0) [0|511] "V"  Receiver
 SG_ CC_line3Voltage : 42|9@1+ (1,0) [0|511] "V"  Receiver
 SG_ CC_numPhases : 10|2@1+ (1,0) [0|3] ""  Receiver
 SG_ CC_numVehCharging : 30|3@1+ (1,0) [0|7] ""  Receiver
 SG_ CC_pilotState : 8|2@1+ (1,0) [0|3] ""  Receiver

BO_ 797 ID31DCC_chgStatus2: 8 VehicleBus
 SG_ CC_chgStatus2Index M : 0|8@1+ (1,0) [0|0] ""  Receiver
 SG_ CC_buttonState m0 : 8|1@1+ (1,0) [0|1] ""  Receiver

BO_ 812 ID32CCC_logData: 8 VehicleBus
 SG_ CC_logIndex M : 0|8@1+ (1,0) [0|13] ""  Receiver
 SG_ CC_activeConnectorID m0 : 8|8@1+ (1,0) [0|255] ""  Receiver
 SG_ CC_conn1Current m1 : 8|8@1+ (0.5,0) [0|127.5] "A"  Receiver
 SG_ CC_conn2Current m2 : 8|8@1+ (0.5,0) [0|127.5] "A"  Receiver
 SG_ CC_conn3Current m3 : 8|8@1+ (0.5,0) [0|127.5] "A"  Receiver
 SG_ CC_conn4Current m4 : 8|8@1+ (0.5,0) [0|127.5] "A"  Receiver
 SG_ CC_contactor1Closed m0 : 40|2@1+ (1,0) [0|3] ""  Receiver
 SG_ CC_contactor2Closed m0 : 42|2@1+ (1,0) [0|3] ""  Receiver
 SG_ CC_lifetimeAlertCount m12 : 8|28@1+ (1,0) [0|268435455] ""  Receiver
 SG_ CC_lifetimeAvgStartupTemp m13 : 36|28@1- (0.1,0) [-13421772.8|13421772.7] "C"  Receiver
 SG_ CC_lifetimeCtrCycles m11 : 8|28@1+ (1,0) [0|268435455] ""  Receiver
 SG_ CC_lifetimeCtrCyclesLoaded m11 : 36|28@1+ (1,0) [0|268435455] ""  Receiver
 SG_ CC_lifetimeThermalFoldbacks m12 : 36|28@1+ (1,0) [0|268435455] ""  Receiver
 SG_ CC_lifetimei2t m10 : 32|32@1+ (0.1,0) [0|429496729.5] "A2h"  Receiver
 SG_ CC_temperature1 m0 : 16|8@1- (1,88) [-40|215] "C"  Receiver
 SG_ CC_temperature2 m0 : 24|8@1- (1,88) [-40|215] "C"  Receiver
 SG_ CC_temperature3 m0 : 32|8@1- (1,88) [-40|215] "C"  Receiver
 SG_ CC_temperature4 m0 : 44|8@1- (1,88) [-40|215] "C"  Receiver

BO_ 573 ID23DCP_chargeStatus: 4 VehicleBus
 SG_ CP_acChargeCurrentLimit : 8|8@1+ (0.5,0) [0|127.5] "A"  Receiver
 SG_ CP_chargeShutdownRequest : 3|2@1+ (1,0) [0|2] ""  Receiver
 SG_ CP_hvChargeStatus : 0|3@1+ (1,0) [0|6] ""  Receiver
 SG_ CP_internalMaxCurrentLimit : 16|13@1+ (0.14650226,0) [0|1200] "A"  Receiver
 SG_ CP_vehicleIsoCheckRequired : 29|1@1+ (1,0) [0|1] ""  Receiver
 SG_ CP_vehiclePrechargeRequired : 30|1@1+ (1,0) [0|1] ""  Receiver

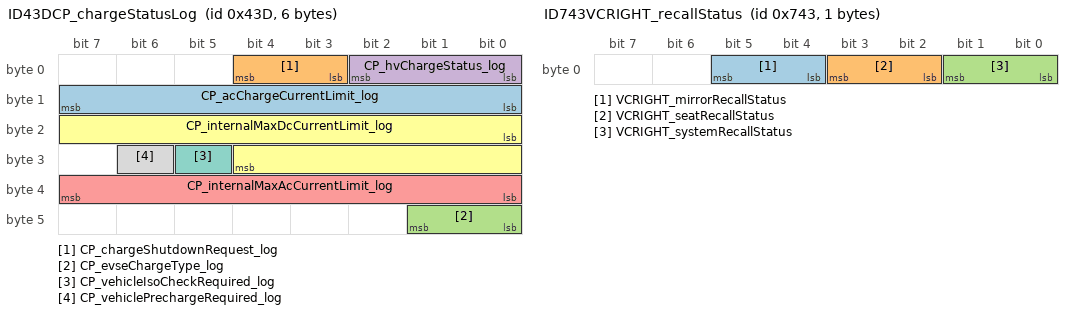
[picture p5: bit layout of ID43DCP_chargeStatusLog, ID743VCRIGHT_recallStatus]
BO_ 1085 ID43DCP_chargeStatusLog: 6 VehicleBus
 SG_ CP_acChargeCurrentLimit_log : 8|8@1+ (0.5,0) [0|127.5] "A"  Receiver
 SG_ CP_chargeShutdownRequest_log : 3|2@1+ (1,0) [0|2] ""  Receiver
 SG_ CP_evseChargeType_log : 40|2@1+ (1,0) [0|2] ""  Receiver
 SG_ CP_hvChargeStatus_log : 0|3@1+ (1,0) [0|6] ""  Receiver
 SG_ CP_internalMaxAcCurrentLimit_log : 32|8@1+ (0.5,0) [0|127.5] "A"  Receiver
 SG_ CP_internalMaxDcCurrentLimit_log : 16|13@1+ (0.14650226,0) [0|1200] "A"  Receiver
 SG_ CP_vehicleIsoCheckRequired_log : 29|1@1+ (1,0) [0|1] ""  Receiver
 SG_ CP_vehiclePrechargeRequired_log : 30|1@1+ (1,0) [0|1] ""  Receiver

BO_ 541 ID21DCP_evseStatus: 8 VehicleBus
 SG_ CP_acChargeState : 53|3@1+ (1,0) [0|6] ""  Receiver
 SG_ CP_acNumRetries : 40|2@1+ (1,0) [0|3] ""  Receiver
 SG_ CP_cableCurrentLimit : 24|7@1+ (1,0) [0|127] "A"  Receiver
 SG_ CP_cableType : 16|3@1+ (1,0) [0|4] ""  Receiver
 SG_ CP_digitalCommsAttempts : 32|2@1+ (1,0) [0|3] ""  Receiver
 SG_ CP_digitalCommsEstablished : 37|1@1+ (1,0) [0|1] ""  Receiver
 SG_ CP_evseAccept : 0|1@1+ (1,0) [0|1] ""  Receiver
 SG_ CP_evseChargeType_UI : 38|2@1+ (1,0) [0|2] ""  Receiver
 SG_ CP_evseRequest : 1|1@1+ (1,0) [0|1] ""  Receiver
 SG_ CP_gbState : 42|4@1+ (1,0) [0|15] ""  Receiver
 SG_ CP_gbdcChargeAttempts : 51|2@1+ (1,0) [0|3] ""  Receiver
 SG_ CP_gbdcFailureReason : 49|2@1+ (1,0) [0|3] ""  Receiver
 SG_ CP_gbdcStopChargeReason : 46|3@1+ (1,0) [0|7] ""  Receiver
 SG_ CP_iecComboState : 60|4@1+ (1,0) [0|12] ""  Receiver
 SG_ CP_pilot : 4|3@1+ (1,0) [0|7] ""  Receiver
 SG_ CP_pilotCurrent : 8|8@1+ (0.5,0) [0|127.5] "A"  Receiver
 SG_ CP_proximity : 2|2@1+ (1,0) [0|3] ""  Receiver
 SG_ CP_teslaDcState : 56|4@1+ (1,0) [0|10] ""  Receiver
 SG_ CP_teslaSwcanState : 34|3@1+ (1,0) [0|6] ""  Receiver

BO_ 1859 ID743VCRIGHT_recallStatus: 1 VehicleBus
 SG_ VCRIGHT_mirrorRecallStatus : 4|2@1+ (1,0) [0|3] ""  Receiver
 SG_ VCRIGHT_seatRecallStatus : 2|2@1+ (1,0) [0|3] ""  Receiver
 SG_ VCRIGHT_systemRecallStatus : 0|2@1+ (1,0) [0|3] ""  Receiver

BO_ 1885 ID75DCP_sensorData: 8 VehicleBus
 SG_ CP_sensorDataSelect M : 0|4@1+ (1,0) [0|11] ""  Receiver
 SG_ CP_UHF_chipState m6 : 4|3@1+ (1,0) [0|7] ""  Receiver
 SG_ CP_UHF_fifoData m6 : 32|8@1+ (1,0) [0|255] ""  Receiver
 SG_ CP_UHF_rssi m6 : 8|8@1+ (1,0) [0|255] ""  Receiver
 SG_ CP_UHF_rxNumBytes m6 : 24|8@1+ (1,0) [0|255] ""  Receiver
 SG_ CP_UHF_rxOverflow m6 : 16|1@1+ (1,0) [0|1] ""  Receiver
 SG_ CP_UHF_selfTestRssi m6 : 40|8@1+ (1,0) [0|255] ""  Receiver
 SG_ CP_backCoverCounts m2 : 40|16@1+ (0.00152590219,0) [0|100.00000002165] "%"  Receiver
 SG_ CP_boardTemperature m1 : 32|8@1+ (1.29411764706,-50) [-50|280.0000000003] "C"  Receiver
 SG_ CP_doorCountsDebounced m0 : 24|16@1+ (0.00152590219,0) [0|100.00000002165] "%"  Receiver
 SG_ CP_doorCountsFiltered m0 : 8|16@1+ (0.00152590219,0) [0|100.00000002165] "%"  Receiver
 SG_ CP_doorI m2 : 16|12@1+ (0.0025,0) [0|10.2375] "A"  Receiver
 SG_ CP_doorLastRequestMaxI m2 : 28|12@1+ (0.0025,0) [0|10.2375] "A"  Receiver
 SG_ CP_doorPot m2 : 4|12@1+ (0.025,0) [0|100] "%"  Receiver
 SG_ CP_faultLineV m5 : 4|12@1+ (0.00114,0) [0|4.65524] "V"  Receiver
 SG_ CP_inductiveSensor_raw m4 : 4|28@1+ (1,0) [0|268435455] ""  Receiver
 SG_ CP_latch2I m3 : 16|12@1+ (0.0025,0) [0|10.2375] "A"  Receiver
 SG_ CP_latchI m3 : 4|12@1+ (0.0025,0) [0|10.2375] "A"  Receiver
 SG_ CP_pilotHighValue m9 : 40|12@1- (0.01,0) [-20.48|20.47] "V"  Receiver
 SG_ CP_pilotHighValue_intervalMax10s m10 : 28|12@1- (0.01,0) [-20.48|20.47] "V"  Receiver
 SG_ CP_pilotHighValue_intervalMin10s m10 : 40|12@1- (0.01,0) [-20.48|20.47] "V"  Receiver
 SG_ CP_pilotLowValue m9 : 28|12@1- (0.01,0) [-20.48|20.47] "V"  Receiver
 SG_ CP_pilotLowValue_intervalMax10s m10 : 4|12@1- (0.01,0) [-20.48|20.47] "V"  Receiver
 SG_ CP_pilotLowValue_intervalMin10s m10 : 16|12@1- (0.01,0) [-20.48|20.47] "V"  Receiver
 SG_ CP_pilotPeriod m9 : 16|12@1+ (1,0) [0|4095] ""  Receiver
 SG_ CP_pilotPulseWidth m9 : 4|12@1+ (1,0) [0|4095] ""  Receiver
 SG_ CP_pinTemperature1 m1 : 8|8@1+ (0.8039215686,-55) [-55|149.99] "C"  Receiver
 SG_ CP_pinTemperature2 m1 : 16|8@1+ (0.8039215686,-55) [-55|149.99] "C"  Receiver
 SG_ CP_pinTemperature3 m1 : 24|8@1+ (0.8039215686,-55) [-55|149.99] "C"  Receiver
 SG_ CP_proxConn1Sense m8 : 56|1@1+ (1,0) [0|1] ""  Receiver
 SG_ CP_proxEn m8 : 57|1@1+ (1,0) [0|1] ""  Receiver
 SG_ CP_proximityV m8 : 8|16@1+ (0.0001,0) [0|6.5535] "V"  Receiver
 SG_ CP_proximityV_GBCC1 m11 : 8|14@1+ (0.001,0) [0|13.3] "V"  Receiver
 SG_ CP_proximityV_GBCC2 m11 : 24|14@1+ (0.001,0) [0|13.3] "V"  Receiver
 SG_ CP_proximityV_intervalMax10s m8 : 40|16@1+ (0.0001,0) [0|6.5535] "V"  Receiver
 SG_ CP_proximityV_intervalMin10s m8 : 24|16@1+ (0.0001,0) [0|6.5535] "V"  Receiver
 SG_ CP_refVoltage m7 : 8|8@1+ (0.0070588235,0) [0|1.7999999925] "V"  Receiver

BO_ 1962 ID7AAHVP_debugMessage: 8 VehicleBus
 SG_ HVP_debugMessageMultiplexer M : 0|4@1+ (1,0) [0|6] ""  Receiver
 SG_ HVP_auxCurrentMia m0 : 57|1@1+ (1,0) [0|1] ""  Receiver
 SG_ HVP_battery12V m5 : 36|12@1+ (0.1,0) [0|30] "V"  Receiver
 SG_ HVP_currentSenseMia m0 : 58|1@1+ (1,0) [0|1] ""  Receiver
 SG_ HVP_dcLinkNegativeV m3 : 8|16@1- (0.1,0) [-550|550] "V"  Receiver
 SG_ HVP_dcLinkPositiveV m3 : 24|16@1- (0.1,0) [-550|550] "V"  Receiver
 SG_ HVP_dcLinkVoltage m1 : 8|16@1- (0.1,0) [-3276.8|3276.7] "V"  Receiver
 SG_ HVP_fcContCoilCurrent m4 : 4|12@1+ (0.1,0) [0|7.5] "A"  Receiver
 SG_ HVP_fcContVoltage m4 : 16|12@1+ (0.1,0) [0|30] "V"  Receiver
 SG_ HVP_fcLinkNegativeV m3 : 40|16@1- (0.1,0) [-550|550] "V"  Receiver
 SG_ HVP_fcLinkPositiveV m5 : 8|16@1- (0.1,0) [-550|550] "V"  Receiver
 SG_ HVP_fcLinkVoltage m1 : 40|16@1- (0.1,0) [-3276.8|3276.7] "V"  Receiver
 SG_ HVP_gpioBmsEout m0 : 15|1@1+ (1,0) [0|1] ""  Receiver
 SG_ HVP_gpioCpFaultIn m0 : 6|1@1+ (1,0) [0|1] ""  Receiver
 SG_ HVP_gpioCpFaultOut m0 : 16|1@1+ (1,0) [0|1] ""  Receiver
 SG_ HVP_gpioCpLatchEnable m0 : 21|1@1+ (1,0) [0|1] ""  Receiver
 SG_ HVP_gpioCrashSignal m0 : 11|1@1+ (1,0) [0|1] ""  Receiver
 SG_ HVP_gpioFcContNegAux m0 : 14|1@1+ (1,0) [0|1] ""  Receiver
 SG_ HVP_gpioFcContPosAux m0 : 13|1@1+ (1,0) [0|1] ""  Receiver
 SG_ HVP_gpioFcContPowerEnable m0 : 25|1@1+ (1,0) [0|1] ""  Receiver
 SG_ HVP_gpioHvCablesOk m0 : 8|1@1+ (1,0) [0|1] ""  Receiver
 SG_ HVP_gpioHvilEnable m0 : 26|1@1+ (1,0) [0|1] ""  Receiver
 SG_ HVP_gpioHvpSelfEnable m0 : 9|1@1+ (1,0) [0|1] ""  Receiver
 SG_ HVP_gpioHvpVerEn m0 : 19|1@1+ (1,0) [0|1] ""  Receiver
 SG_ HVP_gpioLed m0 : 10|1@1+ (1,0) [0|1] ""  Receiver
 SG_ HVP_gpioPackContPowerEn m0 : 7|1@1+ (1,0) [0|1] ""  Receiver
 SG_ HVP_gpioPackCoontPosFlywheel m0 : 20|1@1+ (1,0) [0|1] ""  Receiver
 SG_ HVP_gpioPassivePyroDepl m0 : 4|1@1+ (1,0) [0|1] ""  Receiver
 SG_ HVP_gpioPcsChargePwmEnable m0 : 24|1@1+ (1,0) [0|1] ""  Receiver
 SG_ HVP_gpioPcsDcdcPwmEnable m0 : 23|1@1+ (1,0) [0|1] ""  Receiver
 SG_ HVP_gpioPcsEnable m0 : 22|1@1+ (1,0) [0|1] ""  Receiver
 SG_ HVP_gpioPyroIsoEn m0 : 5|1@1+ (1,0) [0|1] ""  Receiver
 SG_ HVP_gpioPyroPor m0 : 17|1@1+ (1,0) [0|1] ""  Receiver
 SG_ HVP_gpioSecDrdy m0 : 27|1@1+ (1,0) [0|1] ""  Receiver
 SG_ HVP_gpioShuntDataReady m0 : 12|1@1+ (1,0) [0|1] ""  Receiver
 SG_ HVP_gpioShuntEn m0 : 18|1@1+ (1,0) [0|1] ""  Receiver
 SG_ HVP_hvilInVoltage m4 : 28|12@1+ (0.1,0) [0|30] "V"  Receiver
 SG_ HVP_hvilOutVoltage m4 : 40|12@1+ (0.1,0) [0|30] "V"  Receiver
 SG_ HVP_hvp1v5Ref m0 : 28|12@1+ (0.1,0) [0|3] "V"  Receiver
 SG_ HVP_packContCoilCurrent m5 : 24|12@1+ (0.1,0) [0|7.5] "A"  Receiver
 SG_ HVP_packContVoltage m2 : 4|12@1+ (0.1,0) [0|30] "V"  Receiver
 SG_ HVP_packCurrentMia m0 : 56|1@1+ (1,0) [0|1] ""  Receiver
 SG_ HVP_packNegativeV m2 : 16|16@1- (0.1,0) [-550|550] "V"  Receiver
 SG_ HVP_packPositiveV m2 : 32|16@1- (0.1,0) [-550|550] "V"  Receiver
 SG_ HVP_packVoltage m1 : 24|16@1- (0.1,0) [-3276.8|3276.7] "V"  Receiver
 SG_ HVP_pyroAnalog m2 : 48|12@1+ (0.1,0) [0|3] "V"  Receiver
 SG_ HVP_shuntAsicTempDbg m6 : 40|16@1- (0.1,0) [-3276.7|3276.7] "C"  Receiver
 SG_ HVP_shuntAuxCurrentDbg m6 : 8|16@1- (0.1,0) [-3276.8|3276.7] "A"  Receiver
 SG_ HVP_shuntBarTempDbg m6 : 24|16@1- (0.01,0) [-327.67|327.67] "C"  Receiver
 SG_ HVP_shuntCurrentDebug m0 : 40|16@1- (0.1,0) [-3276.8|3276.7] "A"  Receiver
 SG_ HVP_shuntHwMia m0 : 61|1@1+ (1,0) [0|1] ""  Receiver
 SG_ HVP_shuntRefVoltageDbg m5 : 48|16@1- (0.001,0) [-32.768|32.767] "V"  Receiver
 SG_ HVP_shuntRefVoltageMismatch m0 : 59|1@1+ (1,0) [0|1] ""  Receiver
 SG_ HVP_shuntThermistorMia m0 : 60|1@1+ (1,0) [0|1] ""  Receiver

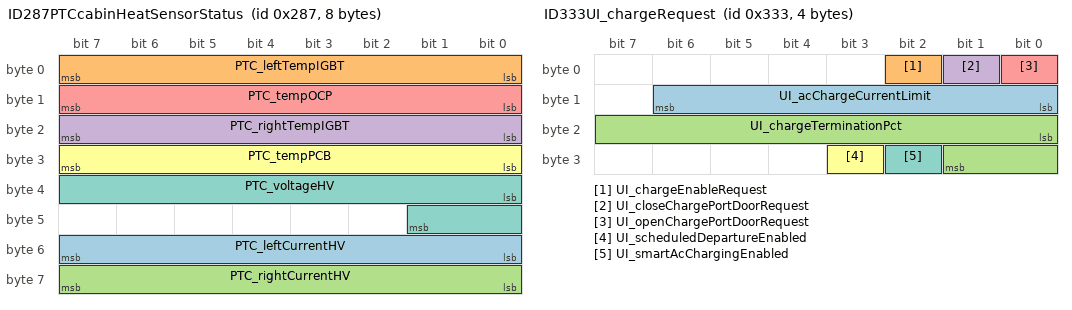
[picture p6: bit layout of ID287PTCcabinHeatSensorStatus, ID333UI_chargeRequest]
BO_ 647 ID287PTCcabinHeatSensorStatus: 8 VehicleBus
 SG_ PTC_leftCurrentHV : 48|8@1+ (0.2,0) [0|50] "A"  Receiver
 SG_ PTC_leftTempIGBT : 0|8@1+ (1,-40) [-40|200] "C"  Receiver
 SG_ PTC_rightCurrentHV : 56|8@1+ (0.2,0) [0|50] "A"  Receiver
 SG_ PTC_rightTempIGBT : 16|8@1+ (1,-40) [-40|200] "C"  Receiver
 SG_ PTC_tempOCP : 8|8@1+ (1,-40) [-40|200] "C"  Receiver
 SG_ PTC_tempPCB : 24|8@1+ (1,-40) [-40|200] "C"  Receiver
 SG_ PTC_voltageHV : 32|10@1+ (0.5,0) [0|511.5] "V"  Receiver

BO_ 819 ID333UI_chargeRequest: 4 VehicleBus
 SG_ UI_acChargeCurrentLimit : 8|7@1+ (1,0) [0|127] "A"  Receiver
 SG_ UI_chargeEnableRequest : 2|1@1+ (1,0) [0|1] ""  Receiver
 SG_ UI_chargeTerminationPct : 16|10@1+ (0.1,0) [25|100] "%"  Receiver
 SG_ UI_closeChargePortDoorRequest : 1|1@1+ (1,0) [0|1] ""  Receiver
 SG_ UI_openChargePortDoorRequest : 0|1@1+ (1,0) [0|1] ""  Receiver
 SG_ UI_scheduledDepartureEnabled : 27|1@1+ (1,0) [0|1] ""  Receiver
 SG_ UI_smartAcChargingEnabled : 26|1@1+ (1,0) [0|1] ""  Receiver

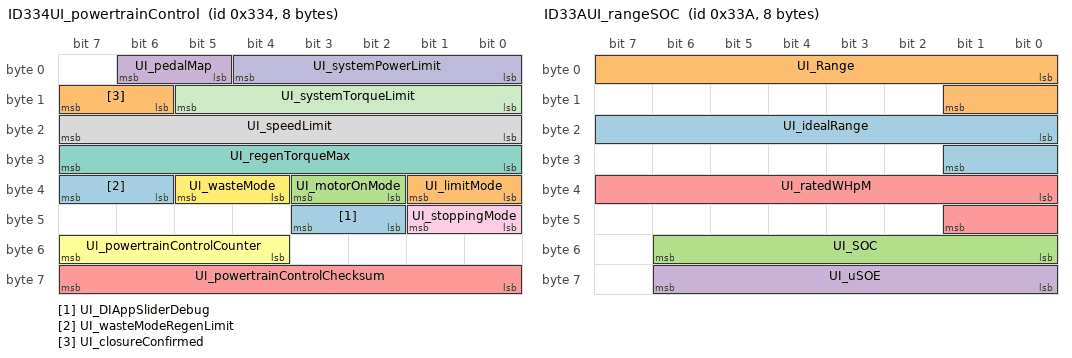
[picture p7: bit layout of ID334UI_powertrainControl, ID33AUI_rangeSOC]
BO_ 820 ID334UI_powertrainControl: 8 VehicleBus
 SG_ UI_DIAppSliderDebug : 42|2@1+ (1,0) [0|3] ""  Receiver
 SG_ UI_limitMode : 32|2@1+ (1,0) [0|3] ""  Receiver
 SG_ UI_motorOnMode : 34|2@1+ (1,0) [0|2] ""  Receiver
 SG_ UI_pedalMap : 5|2@1+ (1,0) [0|2] ""  Receiver
 SG_ UI_powertrainControlChecksum : 56|8@1+ (1,0) [0|255] ""  Receiver
 SG_ UI_powertrainControlCounter : 52|4@1+ (1,0) [0|15] ""  Receiver
 SG_ UI_regenTorqueMax : 24|8@1+ (0.5,0) [0|100] "%"  Receiver
 SG_ UI_speedLimit : 16|8@1+ (1,50) [50|285] "kph"  Receiver
 SG_ UI_stoppingMode : 40|2@1+ (1,0) [0|2] ""  Receiver
 SG_ UI_systemPowerLimit : 0|5@1+ (20,20) [20|640] "kW"  Receiver
 SG_ UI_systemTorqueLimit : 8|6@1+ (100,4000) [4000|10300] "Nm"  Receiver
 SG_ UI_wasteMode : 36|2@1+ (1,0) [0|2] ""  Receiver
 SG_ UI_wasteModeRegenLimit : 38|2@1+ (1,0) [0|3] ""  Receiver
 SG_ UI_closureConfirmed : 14|2@1+ (1,0) [0|2] ""  Receiver

BO_ 826 ID33AUI_rangeSOC: 8 VehicleBus
 SG_ UI_idealRange : 16|10@1+ (1,0) [0|1023] "mi"  Receiver
 SG_ UI_Range : 0|10@1+ (1,0) [0|1023] "mi"  Receiver
 SG_ UI_SOC : 48|7@1+ (1,0) [0|127] "%"  Receiver
 SG_ UI_uSOE : 56|7@1+ (1,0) [0|127] "%"  Receiver
 SG_ UI_ratedWHpM : 32|10@1+ (1,0) [0|1023] "WHpM"  Receiver

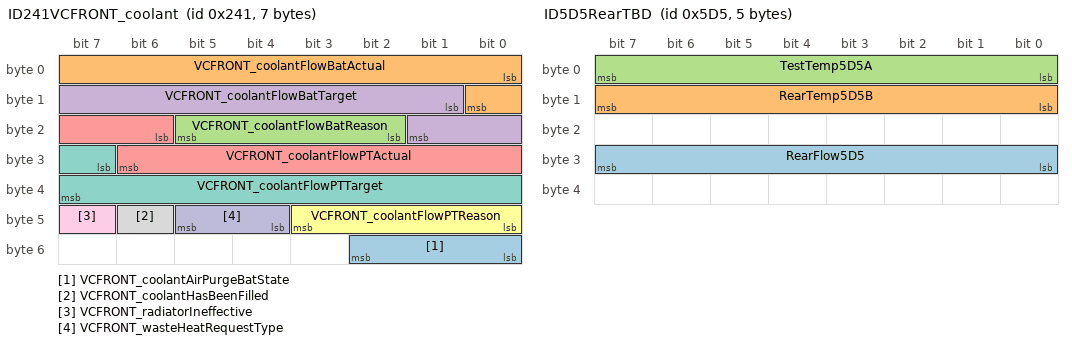
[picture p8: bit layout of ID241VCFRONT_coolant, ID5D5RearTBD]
BO_ 577 ID241VCFRONT_coolant: 7 VehicleBus
 SG_ VCFRONT_coolantAirPurgeBatState : 48|3@1+ (1,0) [0|4] ""  Receiver
 SG_ VCFRONT_coolantFlowBatActual : 0|9@1+ (0.1,0) [0|40] "LPM"  Receiver
 SG_ VCFRONT_coolantFlowBatReason : 18|4@1+ (1,0) [0|14] ""  Receiver
 SG_ VCFRONT_coolantFlowBatTarget : 9|9@1+ (0.1,0) [0|40] "LPM"  Receiver
 SG_ VCFRONT_coolantFlowPTActual : 22|9@1+ (0.1,0) [0|40] "LPM"  Receiver
 SG_ VCFRONT_coolantFlowPTReason : 40|4@1+ (1,0) [0|14] ""  Receiver
 SG_ VCFRONT_coolantFlowPTTarget : 31|9@1+ (0.1,0) [0|40] "LPM"  Receiver
 SG_ VCFRONT_coolantHasBeenFilled : 46|1@1+ (1,0) [0|1] ""  Receiver
 SG_ VCFRONT_radiatorIneffective : 47|1@1+ (1,0) [0|1] ""  Receiver
 SG_ VCFRONT_wasteHeatRequestType : 44|2@1+ (1,0) [0|2] ""  Receiver

BO_ 708 ID2C4PCS_logging: 8 VehicleBus
 SG_ PCS_logMessageSelect M : 0|5@1+ (1,0) [0|26] ""  Receiver
 SG_ PCS_1V2Max10s m9 : 43|11@1+ (0.001,0) [0|2.047] "V"  Receiver
 SG_ PCS_1V2Min10s m9 : 32|11@1+ (0.001,0) [0|2.047] "V"  Receiver
 SG_ PCS_1V5Max10s m9 : 19|11@1+ (0.001,0) [0|2.047] "V"  Receiver
 SG_ PCS_1V5Min10s m9 : 8|11@1+ (0.001,0) [0|2.047] "V"  Receiver
 SG_ PCS_5VNMax10s m9 : 54|10@1+ (0.01,0) [0|10.23] "V"  Receiver
 SG_ PCS_acChargeSelfTestState m9 : 7|1@1+ (1,0) [0|1] ""  Receiver
 SG_ PCS_chg5VL1Enable m5 : 61|1@1+ (1,0) [0|1] ""  Receiver
 SG_ PCS_chgAcpwHeartbeatState m23 : 62|2@1+ (1,0) [0|3] ""  Receiver
 SG_ PCS_chgCurrentSensorOutOfBandUs m20 : 32|10@1+ (0.01,0) [0|10.23] "us"  Receiver
 SG_ PCS_chgInputFrequencyL1N m4 : 5|12@1+ (0.01,40) [40|80.95] "Hz"  Receiver
 SG_ PCS_chgInputFrequencyL2N m4 : 17|12@1+ (0.01,40) [40|80.95] "Hz"  Receiver
 SG_ PCS_chgInputFrequencyL3N m4 : 29|12@1+ (0.01,40) [40|80.95] "Hz"  Receiver
 SG_ PCS_chgInputL1L2Vdc m21 : 36|10@1- (1,0) [-512|511] "V"  Receiver
 SG_ PCS_chgInputL1L2Vrms m3 : 41|12@1+ (0.2,0) [0|819] "V"  Receiver
 SG_ PCS_chgInputL1NVdc m21 : 5|10@1- (1,0) [-512|511] "V"  Receiver
 SG_ PCS_chgInputL1NVrms m3 : 5|12@1+ (0.2,0) [0|819] "V"  Receiver
 SG_ PCS_chgInputL2NVdc m21 : 16|10@1- (1,0) [-512|511] "V"  Receiver
 SG_ PCS_chgInputL2NVrms m3 : 17|12@1+ (0.2,0) [0|819] "V"  Receiver
 SG_ PCS_chgInputL3NVdc m21 : 26|10@1- (1,0) [-512|511] "V"  Receiver
 SG_ PCS_chgInputL3NVrms m3 : 29|12@1+ (0.2,0) [0|819] "V"  Receiver
 SG_ PCS_chgInputNGVdc m21 : 46|10@1- (1,0) [-512|511] "V"  Receiver
 SG_ PCS_chgInputNGVrms m3 : 53|9@1+ (1,0) [0|511] "V"  Receiver
 SG_ PCS_chgInternalPhaseConfig m4 : 41|4@1+ (1,0) [0|9] ""  Receiver
 SG_ PCS_chgKwhLostByFreqDroop m20 : 48|8@1+ (0.1,0) [0|25.5] "kWh"  Receiver
 SG_ PCS_chgL1L2PllLocked m5 : 57|1@1+ (1,0) [0|1] ""  Receiver
 SG_ PCS_chgL1NPllLocked m5 : 54|1@1+ (1,0) [0|1] ""  Receiver
 SG_ PCS_chgL2NPllLocked m5 : 55|1@1+ (1,0) [0|1] ""  Receiver
 SG_ PCS_chgL3NPllLocked m5 : 56|1@1+ (1,0) [0|1] ""  Receiver
 SG_ PCS_chgNgPllLocked m5 : 58|1@1+ (1,0) [0|1] ""  Receiver
 SG_ PCS_chgOutputV m4 : 51|12@1+ (0.146484375,0) [0|599.853515625] "V"  Receiver
 SG_ PCS_chgPHAInputVPeak10s m13 : 5|9@1+ (1,0) [0|511] "V"  Receiver
 SG_ PCS_chgPHBInputVPeak10s m13 : 14|9@1+ (1,0) [0|511] "V"  Receiver
 SG_ PCS_chgPHCInputVPeak10s m13 : 23|9@1+ (1,0) [0|511] "V"  Receiver
 SG_ PCS_chgPhAInputFreqWobbleCnt m13 : 32|8@1+ (0.1,0) [0|25.5] "s"  Receiver
 SG_ PCS_chgPhAInputIrms m0 : 5|9@1+ (0.1,0) [0|51.1] "A"  Receiver
 SG_ PCS_chgPhAIntBusV m0 : 14|9@1+ (1,0) [0|511] "V"  Receiver
 SG_ PCS_chgPhAIntBusVMax10s m10 : 14|9@1+ (1,0) [0|511] "V"  Receiver
 SG_ PCS_chgPhAIntBusVMin10s m10 : 5|9@1+ (1,0) [0|511] "V"  Receiver
 SG_ PCS_chgPhAIntBusVTarget m0 : 23|9@1+ (1,0) [0|511] "V"  Receiver
 SG_ PCS_chgPhALastShutdownReason m5 : 17|5@1+ (1,0) [0|17] ""  Receiver
 SG_ PCS_chgPhALifetimekWh m10 : 31|24@1+ (0.01,0) [0|167772.15] "kWh"  Receiver
 SG_ PCS_chgPhAMachineEnabled m23 : 5|1@1+ (1,0) [0|1] ""  Receiver
 SG_ PCS_chgPhAMachineRotorFreqDroop m23 : 6|10@1- (0.01,0) [-5.12|5.11] "Hz"  Receiver
 SG_ PCS_chgPhAMachineStatorCurrent m23 : 16|8@1- (0.2,0) [-25.6|25.4] "A"  Receiver
 SG_ PCS_chgPhANoFlowBucket m20 : 5|9@1+ (0.01,0) [0|5.11] "-"  Receiver
 SG_ PCS_chgPhAOutputI m0 : 32|8@1+ (0.1,0) [0|25.5] "A"  Receiver
 SG_ PCS_chgPhAPchgVoltDeltaMax10s m10 : 23|8@1+ (0.5,0) [0|127.5] "V"  Receiver
 SG_ PCS_chgPhARetryCount m5 : 32|3@1+ (1,0) [0|7] ""  Receiver
 SG_ PCS_chgPhAState m5 : 5|4@1+ (1,0) [0|6] ""  Receiver
 SG_ PCS_chgPhATransientRetryCount m10 : 55|9@1+ (0.1,0) [0|51.1] "-"  Receiver
 SG_ PCS_chgPhBInputFreqWobbleCnt m13 : 40|8@1+ (0.1,0) [0|25.5] "s"  Receiver
 SG_ PCS_chgPhBInputIrms m1 : 5|9@1+ (0.1,0) [0|51.1] "A"  Receiver
 SG_ PCS_chgPhBIntBusV m1 : 14|9@1+ (1,0) [0|511] "V"  Receiver
 SG_ PCS_chgPhBIntBusVMax10s m11 : 14|9@1+ (1,0) [0|511] "V"  Receiver
 SG_ PCS_chgPhBIntBusVMin10s m11 : 5|9@1+ (1,0) [0|511] "V"  Receiver
 SG_ PCS_chgPhBIntBusVTarget m1 : 23|9@1+ (1,0) [0|511] "V"  Receiver
 SG_ PCS_chgPhBLastShutdownReason m5 : 22|5@1+ (1,0) [0|17] ""  Receiver
 SG_ PCS_chgPhBLifetimekWh m11 : 31|24@1+ (0.01,0) [0|167772.15] "kWh"  Receiver
 SG_ PCS_chgPhBMachineEnabled m23 : 24|1@1+ (1,0) [0|1] ""  Receiver
 SG_ PCS_chgPhBMachineRotorFreqDroop m23 : 25|10@1- (0.01,0) [-5.12|5.11] "Hz"  Receiver
 SG_ PCS_chgPhBMachineStatorCurrent m23 : 35|8@1- (0.2,0) [-25.6|25.4] "A"  Receiver
 SG_ PCS_chgPhBNoFlowBucket m20 : 14|9@1+ (0.01,0) [0|5.11] "-"  Receiver
 SG_ PCS_chgPhBOutputI m1 : 32|8@1+ (0.1,0) [0|25.5] "A"  Receiver
 SG_ PCS_chgPhBPchgVoltDeltaMax10s m11 : 23|8@1+ (0.5,0) [0|127.5] "V"  Receiver
 SG_ PCS_chgPhBRetryCount m5 : 35|3@1+ (1,0) [0|7] ""  Receiver
 SG_ PCS_chgPhBState m5 : 9|4@1+ (1,0) [0|6] ""  Receiver
 SG_ PCS_chgPhBTransientRetryCount m11 : 55|9@1+ (0.1,0) [0|51.1] "-"  Receiver
 SG_ PCS_chgPhCInputFreqWobbleCnt m13 : 48|8@1+ (0.1,0) [0|25.5] "s"  Receiver
 SG_ PCS_chgPhCInputIrms m2 : 5|9@1+ (0.1,0) [0|51.1] "A"  Receiver
 SG_ PCS_chgPhCIntBusV m2 : 14|9@1+ (1,0) [0|511] "V"  Receiver
 SG_ PCS_chgPhCIntBusVMax10s m12 : 14|9@1+ (1,0) [0|511] "V"  Receiver
 SG_ PCS_chgPhCIntBusVMin10s m12 : 5|9@1+ (1,0) [0|511] "V"  Receiver
 SG_ PCS_chgPhCIntBusVTarget m2 : 23|9@1+ (1,0) [0|511] "V"  Receiver
 SG_ PCS_chgPhCLastShutdownReason m5 : 27|5@1+ (1,0) [0|17] ""  Receiver
 SG_ PCS_chgPhCLifetimekWh m12 : 31|24@1+ (0.01,0) [0|167772.15] "kWh"  Receiver
 SG_ PCS_chgPhCMachineEnabled m23 : 43|1@1+ (1,0) [0|1] ""  Receiver
 SG_ PCS_chgPhCMachineRotorFreqDroop m23 : 44|10@1- (0.01,0) [-5.12|5.11] "Hz"  Receiver
 SG_ PCS_chgPhCMachineStatorCurrent m23 : 54|8@1- (0.2,0) [-25.6|25.4] "A"  Receiver
 SG_ PCS_chgPhCNoFlowBucket m20 : 23|9@1+ (0.01,0) [0|5.11] "-"  Receiver
 SG_ PCS_chgPhCOutputI m2 : 32|8@1+ (0.1,0) [0|25.5] "A"  Receiver
 SG_ PCS_chgPhCPchgVoltDeltaMax10s m12 : 23|8@1+ (0.5,0) [0|127.5] "V"  Receiver
 SG_ PCS_chgPhCRetryCount m5 : 38|3@1+ (1,0) [0|7] ""  Receiver
 SG_ PCS_chgPhCState m5 : 13|4@1+ (1,0) [0|6] ""  Receiver
 SG_ PCS_chgPhCTransientRetryCount m12 : 55|9@1+ (0.1,0) [0|51.1] "-"  Receiver
 SG_ PCS_chgPhManCurrentToDist m5 : 44|10@1+ (0.1,0) [0|100] "A"  Receiver
 SG_ PCS_chgPhManOptimalPhsToUse m5 : 59|2@1+ (1,0) [0|3] ""  Receiver
 SG_ PCS_chgPhasesPriority m4 : 45|6@1+ (1,0) [0|36] ""  Receiver
 SG_ PCS_chgPwmEnableLineErrorCount m22 : 32|10@1+ (1,0) [0|1023] ""  Receiver
 SG_ PCS_chgReqKwhLostByFreqDroop m20 : 56|8@1+ (0.1,0) [0|25.5] "kWh"  Receiver
 SG_ PCS_chgRetryCount m5 : 41|3@1+ (1,0) [0|7] ""  Receiver
 SG_ PCS_cpu2BootState m9 : 5|2@1+ (1,0) [0|3] ""  Receiver
 SG_ PCS_dLogPhAChannel1Content m14 : 5|2@1+ (1,0) [0|3] ""  Receiver
 SG_ PCS_dLogPhAChannel1Data m14 : 16|16@1- (0.02,0) [-655.36|655.34] "-"  Receiver
 SG_ PCS_dLogPhAChannel2Content m15 : 5|2@1+ (1,0) [0|3] ""  Receiver
 SG_ PCS_dLogPhAChannel2Data m15 : 16|16@1- (0.02,0) [-655.36|655.34] "-"  Receiver
 SG_ PCS_dLogPhAChannel3Content m16 : 5|2@1+ (1,0) [0|3] ""  Receiver
 SG_ PCS_dLogPhAChannel3Data m16 : 16|16@1- (0.02,0) [-655.36|655.34] "-"  Receiver
 SG_ PCS_dLogPhAChannel4Content m17 : 5|2@1+ (1,0) [0|3] ""  Receiver
 SG_ PCS_dLogPhAChannel4Data m17 : 16|16@1- (0.02,0) [-655.36|655.34] "-"  Receiver
 SG_ PCS_dLogPhBChannel1Content m14 : 8|2@1+ (1,0) [0|3] ""  Receiver
 SG_ PCS_dLogPhBChannel1Data m14 : 32|16@1- (0.02,0) [-655.36|655.34] "-"  Receiver
 SG_ PCS_dLogPhBChannel2Content m15 : 8|2@1+ (1,0) [0|3] ""  Receiver
 SG_ PCS_dLogPhBChannel2Data m15 : 32|16@1- (0.02,0) [-655.36|655.34] "-"  Receiver
 SG_ PCS_dLogPhBChannel3Content m16 : 8|2@1+ (1,0) [0|3] ""  Receiver
 SG_ PCS_dLogPhBChannel3Data m16 : 32|16@1- (0.02,0) [-655.36|655.34] "-"  Receiver
 SG_ PCS_dLogPhBChannel4Content m17 : 8|2@1+ (1,0) [0|3] ""  Receiver
 SG_ PCS_dLogPhBChannel4Data m17 : 32|16@1- (0.02,0) [-655.36|655.34] "-"  Receiver
 SG_ PCS_dLogPhCChannel1Content m14 : 10|2@1+ (1,0) [0|3] ""  Receiver
 SG_ PCS_dLogPhCChannel1Data m14 : 48|16@1- (0.02,0) [-655.36|655.34] "-"  Receiver
 SG_ PCS_dLogPhCChannel2Content m15 : 10|2@1+ (1,0) [0|3] ""  Receiver
 SG_ PCS_dLogPhCChannel2Data m15 : 48|16@1- (0.02,0) [-655.36|655.34] "-"  Receiver
 SG_ PCS_dLogPhCChannel3Content m16 : 10|2@1+ (1,0) [0|3] ""  Receiver
 SG_ PCS_dLogPhCChannel3Data m16 : 48|16@1- (0.02,0) [-655.36|655.34] "-"  Receiver
 SG_ PCS_dLogPhCChannel4Content m17 : 10|2@1+ (1,0) [0|3] ""  Receiver
 SG_ PCS_dLogPhCChannel4Data m17 : 48|16@1- (0.02,0) [-655.36|655.34] "-"  Receiver
 SG_ PCS_dcdc12vSupportLifetimekWh m22 : 8|24@1+ (0.01,0) [0|167772.15] "kWh"  Receiver
 SG_ PCS_dcdcCLAControllerOutput m7 : 16|10@1+ (0.001,0) [0|1] "1"  Receiver
 SG_ PCS_dcdcClaCurrentFreq m7 : 48|12@1+ (0.09765625,0) [0|399.9] "kHz"  Receiver
 SG_ PCS_dcdcCurrentLimit m6 : 20|12@1+ (0.1,0) [0|400] "A"  Receiver
 SG_ PCS_dcdcHalfPeriodUs m8 : 40|16@1+ (0.00048828125,0) [0|31.9995] "us"  Receiver
 SG_ PCS_dcdcHvBusEstimated_C_uF m25 : 5|10@1+ (7.82013685239492,0) [0|8000] "uF"  Receiver
 SG_ PCS_dcdcHvBusEstimated_R_kOhm m25 : 16|10@1+ (0.0488758553274682,0) [0|50] "kOhm"  Receiver
 SG_ PCS_dcdcIntervalMaxFrequency m18 : 8|12@1+ (1,0) [0|400] "kHz"  Receiver
 SG_ PCS_dcdcIntervalMaxHvBusVolt m18 : 24|13@1+ (0.1,0) [0|600] "V"  Receiver
 SG_ PCS_dcdcIntervalMaxLvBusVolt m18 : 37|9@1+ (0.1,0) [0|40] "V"  Receiver
 SG_ PCS_dcdcIntervalMaxLvOutputCurr m18 : 48|12@1+ (1,0) [0|400] "A"  Receiver
 SG_ PCS_dcdcIntervalMinFrequency m19 : 8|12@1+ (1,0) [0|400] "kHz"  Receiver
 SG_ PCS_dcdcIntervalMinHvBusVolt m19 : 24|13@1+ (0.1,0) [0|600] "V"  Receiver
 SG_ PCS_dcdcIntervalMinLvBusVolt m19 : 37|9@1+ (0.1,0) [0|40] "V"  Receiver
 SG_ PCS_dcdcIntervalMinLvOutputCurr m19 : 48|12@1+ (1,0) [0|400] "A"  Receiver
 SG_ PCS_dcdcLvOutputCurrentTempLimit m6 : 32|12@1+ (0.1,0) [0|400] "A"  Receiver
 SG_ PCS_dcdcMaxLvOutputCurrent m6 : 8|12@1+ (0.1,0) [0|400] "A"  Receiver
 SG_ PCS_dcdcPchgStartHvBusVolt m24 : 16|12@1+ (0.146484375,0) [0|599.853515625] "V"  Receiver
 SG_ PCS_dcdcPchgStartLvBusVolt m24 : 5|10@1+ (0.0390625,0) [0|39.9609375] "V"  Receiver
 SG_ PCS_dcdcPwmEnableLineErrorCount m22 : 42|10@1+ (1,0) [0|1023] ""  Receiver
 SG_ PCS_dcdcShortTimeUs m8 : 24|16@1+ (0.00048828125,0) [0|31.9995] "us"  Receiver
 SG_ PCS_dcdcTCommMeasured m8 : 8|16@1- (0.001953125,0) [-64|63.998] "us"  Receiver
 SG_ PCS_dcdcTankVoltage m7 : 26|11@1- (1,0) [-1024|1023] "V"  Receiver
 SG_ PCS_dcdcTankVoltageTarget m7 : 37|10@1+ (1,0) [0|1023] "V"  Receiver
 SG_ PCS_dcdcUnifiedCommand m7 : 5|10@1+ (0.001,0) [0|1] "1"  Receiver
 SG_ PCS_numAlertsSet m22 : 56|7@1+ (1,0) [0|127] ""  Receiver

BO_ 955 ID3BBUI_power: 2 VehicleBus
 SG_ UI_powerExpected : 0|8@1+ (1,0) [0|100] "kW"  Receiver
 SG_ UI_powerIdeal : 8|8@1+ (1,0) [0|100] "kW"  Receiver

BO_ 1493 ID5D5RearTBD: 5 VehicleBus
 SG_ RearFlow5D5 : 24|8@1+ (0.2,0) [0|0] "LPM"  Receiver
 SG_ RearTemp5D5B : 8|8@1+ (1,-40) [-40|215] "C"  Receiver
 SG_ TestTemp5D5A : 0|8@1+ (1,-40) [-40|215] "C"  Receiver

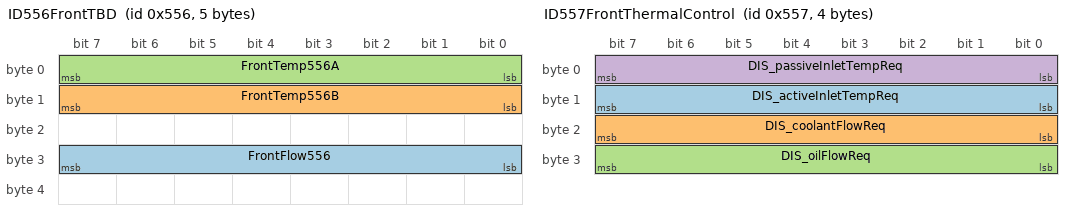
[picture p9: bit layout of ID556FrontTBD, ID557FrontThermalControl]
BO_ 1366 ID556FrontTBD: 5 VehicleBus
 SG_ FrontFlow556 : 24|8@1+ (0.2,0) [0|0] "LPM"  Receiver
 SG_ FrontTemp556B : 8|8@1+ (1,-40) [-40|215] "C"  Receiver
 SG_ FrontTemp556A : 0|8@1+ (1,-40) [-40|215] "C"  Receiver

BO_ 1367 ID557FrontThermalControl: 4 VehicleBus
 SG_ DIS_activeInletTempReq : 8|8@1+ (1,-40) [-40|120] "C"  Receiver
 SG_ DIS_coolantFlowReq : 16|8@1+ (0.2,0) [0|50] "LPM"  Receiver
 SG_ DIS_oilFlowReq : 24|8@1+ (0.06,0) [0|15] "LPM"  Receiver
 SG_ DIS_passiveInletTempReq : 0|8@1+ (1,-40) [-40|120] "C"  Receiver

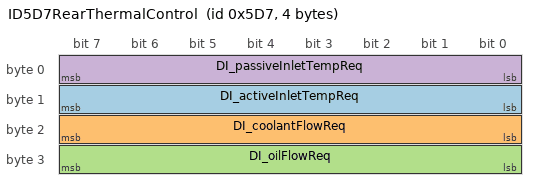
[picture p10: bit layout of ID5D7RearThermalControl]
BO_ 1495 ID5D7RearThermalControl: 4 VehicleBus
 SG_ DI_activeInletTempReq : 8|8@1+ (1,-40) [-40|120] "C"  Receiver
 SG_ DI_coolantFlowReq : 16|8@1+ (0.2,0) [0|50] "LPM"  Receiver
 SG_ DI_oilFlowReq : 24|8@1+ (0.06,0) [0|15] "LPM"  Receiver
 SG_ DI_passiveInletTempReq : 0|8@1+ (1,-40) [-40|120] "C"  Receiver

BO_ 2005 ID7D5DIR_debug: 8 VehicleBus
 SG_ DIR_debugSelector M : 0|8@1+ (1,0) [0|255] ""  Receiver
 SG_ DIR_aebCancelReason m45 : 32|8@1+ (1,0) [0|255] ""  Receiver
 SG_ DIR_aebFaultReason m45 : 16|4@1+ (1,0) [0|15] ""  Receiver
 SG_ DIR_aebUnavailableReason m45 : 24|4@1+ (1,0) [0|10] ""  Receiver
 SG_ DIR_brakeCpScale m2 : 16|9@1- (0.01,0.5) [-1|2] "N/N"  Receiver
 SG_ DIR_brakeSwitchNC m42 : 63|1@1+ (1,0) [0|1] ""  Receiver
 SG_ DIR_brakeSwitchNO m42 : 62|1@1+ (1,0) [0|1] ""  Receiver
 SG_ DIR_brkStState m50 : 24|3@1+ (1,0) [0|6] ""  Receiver
 SG_ DIR_busbarTemp m64 : 16|8@1+ (1,-40) [-40|215] "C"  Receiver
 SG_ DIR_controlStack m67 : 56|8@1+ (0.4,0) [0|100] "%"  Receiver
 SG_ DIR_cpu100HzAvg m66 : 48|8@1+ (0.4,0) [0|102] "%"  Receiver
 SG_ DIR_cpu100HzMax m66 : 40|8@1+ (0.4,0) [0|102] "%"  Receiver
 SG_ DIR_cpu100HzMin m66 : 32|8@1+ (0.4,0) [0|102] "%"  Receiver
 SG_ DIR_cpu10HzAvg m66 : 24|8@1+ (0.4,0) [0|102] "%"  Receiver
 SG_ DIR_cpu10HzMax m66 : 16|8@1+ (0.4,0) [0|102] "%"  Receiver
 SG_ DIR_cpu10HzMin m66 : 8|8@1+ (0.4,0) [0|102] "%"  Receiver
 SG_ DIR_cpu1HzAvg m128 : 32|8@1+ (0.4,0) [0|102] "%"  Receiver
 SG_ DIR_cpu1HzMax m128 : 24|8@1+ (0.4,0) [0|102] "%"  Receiver
 SG_ DIR_cpu1HzMin m128 : 16|8@1+ (0.4,0) [0|102] "%"  Receiver
 SG_ DIR_cpu1kHzAvg m67 : 24|8@1+ (0.4,0) [0|102] "%"  Receiver
 SG_ DIR_cpu1kHzMax m67 : 16|8@1+ (0.4,0) [0|102] "%"  Receiver
 SG_ DIR_cpu1kHzMin m67 : 8|8@1+ (0.4,0) [0|102] "%"  Receiver
 SG_ DIR_cpu20kHzAvg m67 : 48|8@1+ (0.4,0) [0|102] "%"  Receiver
 SG_ DIR_cpu20kHzMax m67 : 40|8@1+ (0.4,0) [0|102] "%"  Receiver
 SG_ DIR_cpu20kHzMin m67 : 32|8@1+ (0.4,0) [0|102] "%"  Receiver
 SG_ DIR_cpuIDWord0 m131 : 16|16@1+ (1,0) [0|65535] ""  Receiver
 SG_ DIR_cpuIDWord1 m132 : 16|16@1+ (1,0) [0|65535] ""  Receiver
 SG_ DIR_cpuIDWord2 m132 : 32|16@1+ (1,0) [0|65535] ""  Receiver
 SG_ DIR_cpuIDWord3 m132 : 48|16@1+ (1,0) [0|65535] ""  Receiver
 SG_ DIR_crc m131 : 32|32@1+ (1,0) [0|4294967295] ""  Receiver
 SG_ DIR_currentLimit m41 : 32|16@1+ (0.1,0) [0|6553.5] "A"  Receiver
 SG_ DIR_dcCableCurrentEst m37 : 16|16@1- (0.1,0) [-3276.8|3276.7] "A"  Receiver
 SG_ DIR_dcCableHeat m47 : 32|16@1+ (0.001,0) [0|65.535] "kA2s"  Receiver
 SG_ DIR_dcCapTemp m64 : 8|8@1+ (1,-40) [-40|215] "C"  Receiver
 SG_ DIR_dcLinkCapTemp m70 : 32|8@1+ (1,-40) [-40|215] "C"  Receiver
 SG_ DIR_decodeHardwareStack m68 : 24|8@1+ (0.4,0) [0|100] "%"  Receiver
 SG_ DIR_driveUnitOdometer m69 : 32|32@1+ (10,0) [0|42949672950] "rev"  Receiver
 SG_ DIR_eepromStack m68 : 32|8@1+ (0.4,0) [0|100] "%"  Receiver
 SG_ DIR_fluxState m42 : 16|4@1+ (1,0) [0|10] ""  Receiver
 SG_ DIR_gainScale m37 : 8|8@1+ (0.01,0) [0|2.55] "scale"  Receiver
 SG_ DIR_gateDriveState m50 : 10|3@1+ (1,0) [0|4] ""  Receiver
 SG_ DIR_gateDriveSupplyState m50 : 8|2@1+ (1,0) [0|3] ""  Receiver
 SG_ DIR_hvDcCableTemp m70 : 40|8@1+ (1,-40) [-40|215] "C"  Receiver
 SG_ DIR_hwFaultCount m69 : 8|4@1+ (1,0) [0|15] ""  Receiver
 SG_ DIR_idleStack m68 : 16|8@1+ (0.4,0) [0|100] "%"  Receiver
 SG_ DIR_immobilizerCondition m64 : 63|1@1+ (1,0) [0|1] ""  Receiver
 SG_ DIR_immobilizerStack m68 : 56|8@1+ (0.4,0) [0|100] "%"  Receiver
 SG_ DIR_internalAngleFilt m37 : 48|16@1+ (0.0003,0) [0|8] "rad"  Receiver
 SG_ DIR_llrScale m42 : 32|8@1+ (0.015,0) [0|3.825] "scale"  Receiver
 SG_ DIR_llsScale m42 : 24|8@1+ (0.004,0) [0|1.02] "scale"  Receiver
 SG_ DIR_lmScale m36 : 8|8@1+ (0.004,0) [0|1.02] "scale"  Receiver
 SG_ DIR_loadAngle m42 : 40|16@1- (0.0003,0) [-4|4] "rad"  Receiver
 SG_ DIR_loadAngleMargin m37 : 32|16@1- (0.0003,0) [-4|4] "rad"  Receiver
 SG_ DIR_locCheckSpeedRef m75 : 54|8@1+ (1,0) [0|250] "kph"  Receiver
 SG_ DIR_locFeedFwTrq m75 : 44|10@1- (10,0) [-5000|5000] "Nm"  Receiver
 SG_ DIR_locTargetAccel m75 : 8|8@1- (0.08,-4.72) [-15|5.4] "m/s^2"  Receiver
 SG_ DIR_locTargetSpeed m75 : 16|8@1+ (1,0) [0|250] "kph"  Receiver
 SG_ DIR_locUi m75 : 34|10@1- (10,0) [-5000|5000] "Nm"  Receiver
 SG_ DIR_locUp m75 : 24|10@1- (10,0) [-5000|5000] "Nm"  Receiver
 SG_ DIR_magnetTempEst m47 : 48|8@1+ (1,-40) [-40|180] "C"  Receiver
 SG_ DIR_module10HzStack m66 : 56|8@1+ (0.4,0) [0|100] "%"  Receiver
 SG_ DIR_motorIA m32 : 16|16@1+ (0.1,0) [0|6553.5] "A"  Receiver
 SG_ DIR_motorIAavg m38 : 32|16@1- (0.1,0) [-3276.8|3276.7] "A"  Receiver
 SG_ DIR_motorIB m32 : 32|16@1+ (0.1,0) [0|6553.5] "A"  Receiver
 SG_ DIR_motorIBavg m38 : 48|16@1- (0.1,0) [-3276.8|3276.7] "A"  Receiver
 SG_ DIR_motorIC m32 : 48|16@1+ (0.1,0) [0|6553.5] "A"  Receiver
 SG_ DIR_motorType m128 : 8|5@1+ (1,0) [0|27] ""  Receiver
 SG_ DIR_motorV m34 : 48|16@1+ (2E-005,0) [0|1.3107] "mindex"  Receiver
 SG_ DIR_muSurfHigh m2 : 8|8@1+ (0.005,0) [0|1.2] "N/N"  Receiver
 SG_ DIR_negDcBusbarTemp m70 : 48|8@1+ (1,-40) [-40|215] "C"  Receiver
 SG_ DIR_offsetA m32 : 8|8@1- (0.1,0) [-12.8|12.7] "A"  Receiver
 SG_ DIR_offsetB m33 : 8|8@1- (0.1,0) [-12.8|12.7] "A"  Receiver
 SG_ DIR_oilPumpMotorSpeed m46 : 8|8@1+ (40,0) [0|10200] "RPM"  Receiver
 SG_ DIR_oilPumpPhaseVoltage m46 : 16|8@1+ (0.1,0) [0|25.4] "V"  Receiver
 SG_ DIR_oilPumpPressureEstimateMax m46 : 24|8@1+ (2,0) [0|500] "kPa"  Receiver
 SG_ DIR_oilPumpPressureExpectedMin m46 : 32|8@1+ (2,0) [0|500] "kPa"  Receiver
 SG_ DIR_opdUnavailableReason m45 : 40|4@1+ (1,0) [0|15] ""  Receiver
 SG_ DIR_pcsTemp m64 : 24|8@1+ (1,-40) [-40|215] "C"  Receiver
 SG_ DIR_peakFlux m36 : 48|16@1+ (0.0001,0) [0|6.5535] "Wb"  Receiver
 SG_ DIR_peakIQref m38 : 16|16@1+ (0.1,0) [0|6553.5] "A"  Receiver
 SG_ DIR_pedalPosFilt m2 : 32|8@1+ (0.4,0) [0|100] "%"  Receiver
 SG_ DIR_phaseOutBusbarTemp m70 : 8|8@1+ (1,-40) [-40|215] "C"  Receiver
 SG_ DIR_phaseOutBusbarWeldTemp m70 : 16|8@1+ (1,-40) [-40|215] "C"  Receiver
 SG_ DIR_phaseOutLugTemp m70 : 24|8@1+ (1,-40) [-40|215] "C"  Receiver
 SG_ DIR_posDcBusbarTemp m70 : 56|8@1+ (1,-40) [-40|215] "C"  Receiver
 SG_ DIR_powerStageSafeState m50 : 13|2@1+ (1,0) [0|3] ""  Receiver
 SG_ DIR_pwrSatChargeCurrent m42 : 8|8@1+ (0.4,0) [0|102] "%"  Receiver
 SG_ DIR_pwrSatDischargeCurrent m40 : 8|8@1+ (0.4,0) [0|102] "%"  Receiver
 SG_ DIR_pwrSatMaxBusVoltage m39 : 48|8@1+ (0.4,0) [0|102] "%"  Receiver
 SG_ DIR_pwrSatMaxDischargePower m39 : 16|8@1+ (0.4,0) [0|102] "%"  Receiver
 SG_ DIR_pwrSatMaxRegenPower m39 : 24|8@1+ (0.4,0) [0|102] "%"  Receiver
 SG_ DIR_pwrSatMinBusVoltage m39 : 56|8@1+ (0.4,0) [0|102] "%"  Receiver
 SG_ DIR_resolverClaMIA m48 : 43|1@1+ (1,0) [0|1] ""  Receiver
 SG_ DIR_resolverCommonGain m48 : 32|8@1+ (0.025,0) [0|5] "1"  Receiver
 SG_ DIR_resolverCosFiltered m52 : 32|8@1- (0.01,0) [-1|1] "1"  Receiver
 SG_ DIR_resolverCosRmsSquared m52 : 16|8@1+ (0.005,0) [0|1] "1"  Receiver
 SG_ DIR_resolverErrorRmsSquared m52 : 48|8@1+ (0.005,0) [0|1] "1"  Receiver
 SG_ DIR_resolverNoCarrier m48 : 41|1@1+ (1,0) [0|1] ""  Receiver
 SG_ DIR_resolverNoPhaseLock m48 : 42|1@1+ (1,0) [0|1] ""  Receiver
 SG_ DIR_resolverOffsetCos m48 : 8|8@1+ (0.015,0) [0|3.3] "V"  Receiver
 SG_ DIR_resolverOffsetSin m48 : 16|8@1+ (0.015,0) [0|3.3] "V"  Receiver
 SG_ DIR_resolverPhaseOffset m48 : 24|8@1+ (0.1,7.5) [7.5|32.5] "us"  Receiver
 SG_ DIR_resolverReady m48 : 40|1@1+ (1,0) [0|1] ""  Receiver
 SG_ DIR_resolverSinFiltered m52 : 40|8@1- (0.01,0) [-1|1] "1"  Receiver
 SG_ DIR_resolverSinRmsSquared m52 : 24|8@1+ (0.005,0) [0|1] "1"  Receiver
 SG_ DIR_rotorFlux m47 : 16|16@1+ (0.0001,0) [0|6.5535] "Wb"  Receiver
 SG_ DIR_rotorMaxMagnetTemp m72 : 16|8@1+ (1,-40) [-40|215] "C"  Receiver
 SG_ DIR_rotorOffsetEst m43 : 8|12@1- (0.01,0) [-20|20] "deg"  Receiver
 SG_ DIR_rotorOffsetLearningState m63 : 8|4@1+ (1,0) [0|9] ""  Receiver
 SG_ DIR_rotorOffsetMean m43 : 20|12@1- (0.01,0) [-20|20] "deg"  Receiver
 SG_ DIR_rsScale m34 : 8|8@1+ (0.01,0) [0|2.55] "scale"  Receiver
 SG_ DIR_soptMaxCurrentMagSqrd m49 : 40|16@1+ (100,0) [0|6553500] "A2"  Receiver
 SG_ DIR_soptTimeToOff m49 : 24|11@1+ (0.05,0) [0|100] "ms"  Receiver
 SG_ DIR_soptTimeToTrip m49 : 8|8@1+ (0.05,0) [0|10] "ms"  Receiver
 SG_ DIR_soptTripDelay m49 : 16|8@1+ (0.05,0) [0|10] "ms"  Receiver
 SG_ DIR_ssmState m38 : 8|4@1+ (1,0) [0|8] ""  Receiver
 SG_ DIR_statorEndWindingTemp m72 : 8|8@1+ (1,-40) [-40|215] "C"  Receiver
 SG_ DIR_statorFluxFdb m35 : 32|16@1+ (0.0001,0) [0|6.5535] "Wb"  Receiver
 SG_ DIR_statorFluxRef m35 : 16|16@1+ (0.0001,0) [0|6.5535] "Wb"  Receiver
 SG_ DIR_statorIDfdb m33 : 32|16@1- (0.1,0) [-3276.8|3276.7] "A"  Receiver
 SG_ DIR_statorIDref m33 : 16|16@1- (0.1,0) [-3276.8|3276.7] "A"  Receiver
 SG_ DIR_statorIQfdb m34 : 32|16@1- (0.1,0) [-3276.8|3276.7] "A"  Receiver
 SG_ DIR_statorIQref m34 : 16|16@1- (0.1,0) [-3276.8|3276.7] "A"  Receiver
 SG_ DIR_statorTemp1 m64 : 32|8@1+ (1,-40) [-40|215] "C"  Receiver
 SG_ DIR_statorTemp2 m64 : 40|8@1+ (1,-40) [-40|215] "C"  Receiver
 SG_ DIR_statorVD m36 : 32|16@1- (4E-005,0) [-1.31072|1.31068] "mindex"  Receiver
 SG_ DIR_statorVDFiltered m63 : 16|16@1- (4E-005,0) [-1.31072|1.31068] "mindex"  Receiver
 SG_ DIR_statorVQ m36 : 16|16@1- (4E-005,0) [-1.31072|1.31068] "mindex"  Receiver
 SG_ DIR_statorVQFiltered m63 : 32|16@1- (4E-005,0) [-1.31072|1.31068] "mindex"  Receiver
 SG_ DIR_sysHeatPowerOptimal m50 : 16|8@1+ (0.08,0) [0|20] "kW"  Receiver
 SG_ DIR_sysPedalMaxTorque m44 : 22|14@1+ (0.1,0) [0|1638.3] "Nm"  Receiver
 SG_ DIR_sysPedalMinTorque m44 : 8|14@1+ (0.1,-1638.3) [-1638.3|0] "Nm"  Receiver
 SG_ DIR_sysPostPedalMaxTorque m44 : 50|14@1+ (0.1,0) [0|1638.3] "Nm"  Receiver
 SG_ DIR_sysPostPedalMinTorque m44 : 36|14@1+ (0.1,-1638.3) [-1638.3|0] "Nm"  Receiver
 SG_ DIR_systemStack m68 : 8|8@1+ (0.4,0) [0|100] "%"  Receiver
 SG_ DIR_systemTorqueCommand m35 : 48|16@1- (0.035,0) [-1146.88|1146.845] "Nm"  Receiver
 SG_ DIR_tcMaxRequest m40 : 16|8@1+ (5,0) [0|1275] "Nm"  Receiver
 SG_ DIR_tcMinRequest m40 : 24|8@1+ (5,0) [0|1275] "Nm"  Receiver
 SG_ DIR_torquePerAmp m33 : 48|16@1+ (0.0001,0) [0|6.5535] "Nm/A"  Receiver
 SG_ DIR_tqSatMotorCurrent m39 : 40|8@1+ (0.4,0) [0|102] "%"  Receiver
 SG_ DIR_tqSatMotorVoltage m39 : 32|8@1+ (0.4,0) [0|102] "%"  Receiver
 SG_ DIR_tqSatThermal m39 : 8|8@1+ (0.4,0) [0|102] "%"  Receiver
 SG_ DIR_tqSatUiDriveTorque m40 : 32|8@1+ (0.4,0) [0|102] "%"  Receiver
 SG_ DIR_tqSatUiRegenTorque m40 : 40|8@1+ (0.4,0) [0|102] "%"  Receiver
 SG_ DIR_tqScaleDifferential m35 : 8|8@1+ (0.4,0) [0|102] "%"  Receiver
 SG_ DIR_tqScaleMaxMotorSpeed m40 : 48|8@1+ (0.4,0) [0|102] "%"  Receiver
 SG_ DIR_tqScaleShift m40 : 56|8@1+ (0.4,0) [0|102] "%"  Receiver
 SG_ DIR_udsStack m68 : 40|8@1+ (0.4,0) [0|100] "%"  Receiver
 SG_ DIR_usmState m38 : 12|3@1+ (1,0) [0|7] ""  Receiver
 SG_ DIR_veMassInvRaw m41 : 8|12@1+ (1E-007,0.0001) [0.0001|0.0005] "1/kg"  Receiver
 SG_ DIR_veResForce m41 : 20|12@1- (0.0005,0) [-1.024|1.0235] "G"  Receiver
 SG_ DIR_velocityEstimatorState m65 : 8|3@1+ (1,0) [0|4] ""  Receiver
 SG_ DIR_wasteCurrentLimit m41 : 48|16@1+ (0.1,0) [0|6553.5] "A"  Receiver
 SG_ DIR_xcpStack m68 : 48|8@1+ (0.4,0) [0|100] "%"  Receiver

CM_ SG_ 692 PCS_dcdcHvBusVolt "DCDC HV Voltage";
CM_ SG_ 692 PCS_dcdcLvBusVolt "DCDC 12v Voltage";
CM_ SG_ 692 PCS_dcdcLvOutputCurrent "DCDC 12v Output Current";
CM_ SG_ 642 VCLEFT_hvacBlowerRPMActual "HVAC Blower Speed";
CM_ SG_ 647 PTC_leftCurrentHV "Heater Left Current";
CM_ SG_ 647 PTC_rightCurrentHV "Heater Right Current";
CM_ SG_ 647 PTC_voltageHV "Heater Voltage";
CM_ SG_ 819 UI_acChargeCurrentLimit "UI Charge Current Limit";
CM_ SG_ 826 UI_Range "Range";
CM_ SG_ 826 UI_SOC "State of Charge UI";
CM_ SG_ 826 UI_ratedWHpM "WHM Rating";
CM_ SG_ 577 VCFRONT_coolantFlowBatActual "Battery Coolant Flow";
CM_ SG_ 577 VCFRONT_coolantFlowPTActual "Powertrain Coolant Flow";
CM_ BO_ 1367 "swapped with 5D7 in old firmware";
CM_ BO_ 1495 "swapped with 557 in old firmware";
CM_ BO_ 2005 "swapped with 757 in old firmware";
BA_DEF_ BO_  "GenMsgSendType" ENUM  "Cyclic","SendType1","SendType2","SendType3","SendType4","SendType5","SendType6","SendType7","SendType8","SendType9";
BA_DEF_ BO_  "GenMsgCycleTime" INT 0 0;
BA_DEF_  "BusType" STRING ;
BA_DEF_ BO_  "GenMsgAutoGenSnd" ENUM  "No","Yes";
BA_DEF_ BO_  "GenMsgAutoGenDsp" ENUM  "No","Yes";
BA_DEF_ SG_  "GenSigEnvVarType" ENUM  "int","float","undef";
BA_DEF_ BU_  "GenNodAutoGenSnd" ENUM  "No","Yes";
BA_DEF_ BU_  "GenNodAutoGenDsp" ENUM  "No","Yes";
BA_DEF_  "GenEnvVarEndingDsp" STRING ;
BA_DEF_  "GenEnvVarEndingSnd" STRING ;
BA_DEF_  "GenEnvVarPrefix" STRING ;
BA_DEF_  "Modified" STRING ;
BA_DEF_ SG_  "SystemSignalLongSymbol" STRING ;
BA_DEF_ BO_  "SystemMessageLongSymbol" STRING ;
BA_DEF_DEF_  "GenMsgSendType" "Cyclic";
BA_DEF_DEF_  "GenMsgCycleTime" 0;
BA_DEF_DEF_  "BusType" "";
BA_DEF_DEF_  "GenMsgAutoGenSnd" "Yes";
BA_DEF_DEF_  "GenMsgAutoGenDsp" "Yes";
BA_DEF_DEF_  "GenSigEnvVarType" "undef";
BA_DEF_DEF_  "GenNodAutoGenSnd" "Yes";
BA_DEF_DEF_  "GenNodAutoGenDsp" "Yes";
BA_DEF_DEF_  "GenEnvVarEndingDsp" "Dsp";
BA_DEF_DEF_  "GenEnvVarEndingSnd" "Snd";
BA_DEF_DEF_  "GenEnvVarPrefix" "Env";
BA_DEF_DEF_  "Modified" "JW2020Mar13";
BA_DEF_DEF_  "SystemSignalLongSymbol" "";
BA_DEF_DEF_  "SystemMessageLongSymbol" "";
BA_ "BusType" "CAN";
BA_ "GenMsgCycleTime" BO_ 530 100;
BA_ "GenMsgCycleTime" BO_ 819 500;
BA_ "GenMsgCycleTime" BO_ 577 100;
BA_ "SystemSignalLongSymbol" SG_ 291 UI_a037_AudioWatchdogXrunStormEr "UI_a037_AudioWatchdogXrunStormError";
BA_ "SystemSignalLongSymbol" SG_ 291 UI_a038_AudioWatchdogA2bI2cLocku "UI_a038_AudioWatchdogA2bI2cLockupError";
BA_ "SystemSignalLongSymbol" SG_ 291 UI_a048_AudioPremiumAmpCheckFail "UI_a048_AudioPremiumAmpCheckFailed";
BA_ "SystemSignalLongSymbol" SG_ 291 UI_a056_ManualECallButtonDisconn "UI_a056_ManualECallButtonDisconnected";
BA_ "SystemSignalLongSymbol" SG_ 611 VCRIGHT_hvacFilterLifeDetectActi "VCRIGHT_hvacFilterLifeDetectActive";
BA_ "SystemSignalLongSymbol" SG_ 642 VCLEFT_hvacBlower_IO_CBC_TAIL_va "VCLEFT_hvacBlower_IO_CBC_TAIL_valid";
BA_ "SystemSignalLongSymbol" SG_ 642 VCLEFT_hvacBlower_IO_CBC_numUart "VCLEFT_hvacBlower_IO_CBC_numUartErr";
BA_ "SystemSignalLongSymbol" SG_ 899 VCRIGHT_estimatedVehicleSituatio "VCRIGHT_estimatedVehicleSituation";
BA_ "SystemSignalLongSymbol" SG_ 963 VCRIGHT_liftgateShutfaceSwitchPr "VCRIGHT_liftgateShutfaceSwitchPressed";
BA_ "SystemSignalLongSymbol" SG_ 946 BMS_hvChain_limitingStateTempera "BMS_hvChain_limitingStateTemperature";
BA_ "SystemSignalLongSymbol" SG_ 946 BMS_vChangeWindowNumOutlierChang "BMS_vChangeWindowNumOutlierChanges";
BA_ "SystemSignalLongSymbol" SG_ 800 BMS_a040_SW_Watch_Dog_HW_Trigger "BMS_a040_SW_Watch_Dog_HW_Triggered";
BA_ "SystemSignalLongSymbol" SG_ 800 BMS_a041_SW_Destructive_Reset_So "BMS_a041_SW_Destructive_Reset_Source";
BA_ "SystemSignalLongSymbol" SG_ 800 BMS_a057_SW_Bandolier_Model_Warn "BMS_a057_SW_Bandolier_Model_Warning";
BA_ "SystemSignalLongSymbol" SG_ 800 BMS_a058_SW_Bandolier_Model_Rese "BMS_a058_SW_Bandolier_Model_Reset";
BA_ "SystemSignalLongSymbol" SG_ 800 BMS_a092_SW_ChargePort_Mia_On_Hv "BMS_a092_SW_ChargePort_Mia_On_Hvs";
BA_ "SystemSignalLongSymbol" SG_ 800 BMS_a098_SW_BMB_Data_Integrity_L "BMS_a098_SW_BMB_Data_Integrity_Loss";
BA_ "SystemSignalLongSymbol" SG_ 800 BMS_a135_HW_BMB_Diagnostics_Fail "BMS_a135_HW_BMB_Diagnostics_Failure";
BA_ "SystemSignalLongSymbol" SG_ 800 BMS_a178_SW_Uncontrolled_Regen_P "BMS_a178_SW_Uncontrolled_Regen_PwrB";
VAL_ 12 UI_autopilotTrial 3 "ACTIVE" 0 "NONE" 1 "START" 2 "STOP" ;
VAL_ 12 UI_cellNetworkTechnology 9 "CELL_NETWORK_CDMA" 2 "CELL_NETWORK_EDGE" 1 "CELL_NETWORK_GPRS" 8 "CELL_NETWORK_GSM" 4 "CELL_NETWORK_HSDPA" 6 "CELL_NETWORK_HSPA" 5 "CELL_NETWORK_HSUPA" 7 "CELL_NETWORK_LTE" 0 "CELL_NETWORK_NONE" 15 "CELL_NETWORK_SNA" 3 "CELL_NETWORK_UMTS" 10 "CELL_NETWORK_WCDMA" ;
VAL_ 12 UI_cellSignalBars 5 "FIVE" 4 "FOUR" 1 "ONE" 7 "SNA" 3 "THREE" 2 "TWO" 0 "ZERO" ;
VAL_ 12 UI_factoryReset 3 "CUSTOMER" 1 "DEVELOPER" 2 "DIAGNOSTIC" 0 "NONE_SNA" ;
VAL_ 130 UI_energyAtDestination -32768 "SNA" -32767 "TRIP_TOO_LONG" ;
VAL_ 130 UI_hindsightEnergy -32768 "SNA" -32767 "TRIP_TOO_LONG" ;
VAL_ 130 UI_predictedEnergy -32768 "SNA" -32767 "TRIP_TOO_LONG" ;
VAL_ 258 VCLEFT_frontLatchStatus 5 "LATCH_AJAR" 2 "LATCH_CLOSED" 3 "LATCH_CLOSING" 7 "LATCH_DEFAULT" 8 "LATCH_FAULT" 1 "LATCH_OPENED" 4 "LATCH_OPENING" 0 "LATCH_SNA" 6 "LATCH_TIMEOUT" ;
VAL_ 258 VCLEFT_mirrorFoldState 1 "MIRROR_FOLD_STATE_FOLDED" 3 "MIRROR_FOLD_STATE_FOLDING" 2 "MIRROR_FOLD_STATE_UNFOLDED" 4 "MIRROR_FOLD_STATE_UNFOLDING" 0 "MIRROR_FOLD_STATE_UNKNOWN" ;
VAL_ 258 VCLEFT_mirrorHeatState 4 "HEATER_STATE_FAULT" 2 "HEATER_STATE_OFF" 3 "HEATER_STATE_OFF_UNAVAILABLE" 1 "HEATER_STATE_ON" 0 "HEATER_STATE_SNA" ;
VAL_ 258 VCLEFT_mirrorRecallState 0 "MIRROR_RECALL_STATE_INIT" 1 "MIRROR_RECALL_STATE_RECALLING_AXIS_1" 2 "MIRROR_RECALL_STATE_RECALLING_AXIS_2" 3 "MIRROR_RECALL_STATE_RECALLING_COMPLETE" 4 "MIRROR_RECALL_STATE_RECALLING_FAILED" 5 "MIRROR_RECALL_STATE_RECALLING_STOPPED" ;
VAL_ 258 VCLEFT_mirrorState 3 "MIRROR_STATE_FOLD_UNFOLD" 0 "MIRROR_STATE_IDLE" 4 "MIRROR_STATE_RECALL" 1 "MIRROR_STATE_TILT_X" 2 "MIRROR_STATE_TILT_Y" ;
VAL_ 258 VCLEFT_rearLatchStatus 5 "LATCH_AJAR" 2 "LATCH_CLOSED" 3 "LATCH_CLOSING" 7 "LATCH_DEFAULT" 8 "LATCH_FAULT" 1 "LATCH_OPENED" 4 "LATCH_OPENING" 0 "LATCH_SNA" 6 "LATCH_TIMEOUT" ;
VAL_ 259 VCRIGHT_frontLatchStatus 5 "LATCH_AJAR" 2 "LATCH_CLOSED" 3 "LATCH_CLOSING" 7 "LATCH_DEFAULT" 8 "LATCH_FAULT" 1 "LATCH_OPENED" 4 "LATCH_OPENING" 0 "LATCH_SNA" 6 "LATCH_TIMEOUT" ;
VAL_ 259 VCRIGHT_mirrorFoldState 1 "MIRROR_FOLD_STATE_FOLDED" 3 "MIRROR_FOLD_STATE_FOLDING" 2 "MIRROR_FOLD_STATE_UNFOLDED" 4 "MIRROR_FOLD_STATE_UNFOLDING" 0 "MIRROR_FOLD_STATE_UNKNOWN" ;
VAL_ 259 VCRIGHT_mirrorRecallState 0 "MIRROR_RECALL_STATE_INIT" 1 "MIRROR_RECALL_STATE_RECALLING_AXIS_1" 2 "MIRROR_RECALL_STATE_RECALLING_AXIS_2" 3 "MIRROR_RECALL_STATE_RECALLING_COMPLETE" 4 "MIRROR_RECALL_STATE_RECALLING_FAILED" 5 "MIRROR_RECALL_STATE_RECALLING_STOPPED" ;
VAL_ 259 VCRIGHT_mirrorState 3 "MIRROR_STATE_FOLD_UNFOLD" 0 "MIRROR_STATE_IDLE" 4 "MIRROR_STATE_RECALL" 1 "MIRROR_STATE_TILT_X" 2 "MIRROR_STATE_TILT_Y" ;
VAL_ 259 VCRIGHT_rearLatchStatus 5 "LATCH_AJAR" 2 "LATCH_CLOSED" 3 "LATCH_CLOSING" 7 "LATCH_DEFAULT" 8 "LATCH_FAULT" 1 "LATCH_OPENED" 4 "LATCH_OPENING" 0 "LATCH_SNA" 6 "LATCH_TIMEOUT" ;
VAL_ 259 VCRIGHT_trunkLatchStatus 5 "LATCH_AJAR" 2 "LATCH_CLOSED" 3 "LATCH_CLOSING" 7 "LATCH_DEFAULT" 8 "LATCH_FAULT" 1 "LATCH_OPENED" 4 "LATCH_OPENING" 0 "LATCH_SNA" 6 "LATCH_TIMEOUT" ;
VAL_ 522 HVP_fcContNegativeState 3 "CONTACTOR_STATE_BLOCKED" 6 "CONTACTOR_STATE_ECONOMIZED" 1 "CONTACTOR_STATE_OPEN" 5 "CONTACTOR_STATE_OPENING" 2 "CONTACTOR_STATE_PRECHARGE" 4 "CONTACTOR_STATE_PULLED_IN" 0 "CONTACTOR_STATE_SNA" 7 "CONTACTOR_STATE_WELDED" ;
VAL_ 522 HVP_fcContPositiveState 3 "CONTACTOR_STATE_BLOCKED" 6 "CONTACTOR_STATE_ECONOMIZED" 1 "CONTACTOR_STATE_OPEN" 5 "CONTACTOR_STATE_OPENING" 2 "CONTACTOR_STATE_PRECHARGE" 4 "CONTACTOR_STATE_PULLED_IN" 0 "CONTACTOR_STATE_SNA" 7 "CONTACTOR_STATE_WELDED" ;
VAL_ 522 HVP_fcContactorSetState 3 "CONTACTOR_SET_STATE_BLOCKED" 5 "CONTACTOR_SET_STATE_CLOSED" 2 "CONTACTOR_SET_STATE_CLOSING" 9 "CONTACTOR_SET_STATE_NEGATIVE_CLOSED" 1 "CONTACTOR_SET_STATE_OPEN" 4 "CONTACTOR_SET_STATE_OPENING" 6 "CONTACTOR_SET_STATE_PARTIAL_WELD" 8 "CONTACTOR_SET_STATE_POSITIVE_CLOSED" 0 "CONTACTOR_SET_STATE_SNA" 7 "CONTACTOR_SET_STATE_WELDED" ;
VAL_ 522 HVP_fcCtrsRequestStatus 1 "REQUEST_ACTIVE" 2 "REQUEST_COMPLETED" 0 "REQUEST_NOT_ACTIVE" ;
VAL_ 522 HVP_fcLinkAllowedToEnergize 1 "FC_LINK_ENERGY_AC" 2 "FC_LINK_ENERGY_DC" 0 "FC_LINK_ENERGY_NONE" ;
VAL_ 522 HVP_hvilStatus 2 "CURRENT_SOURCE_FAULT" 3 "INTERNAL_OPEN_FAULT" 8 "NO_12V_SUPPLY" 5 "PENTHOUSE_LID_OPEN_FAULT" 1 "STATUS_OK" 0 "UNKNOWN" 6 "UNKNOWN_LOCATION_OPEN_FAULT" 7 "VEHICLE_NODE_FAULT" 4 "VEHICLE_OPEN_FAULT" 9 "VEHICLE_OR_PENTHOUSE_LID_OPEN_FAULT" ;
VAL_ 522 HVP_packContNegativeState 3 "CONTACTOR_STATE_BLOCKED" 6 "CONTACTOR_STATE_ECONOMIZED" 1 "CONTACTOR_STATE_OPEN" 5 "CONTACTOR_STATE_OPENING" 2 "CONTACTOR_STATE_PRECHARGE" 4 "CONTACTOR_STATE_PULLED_IN" 0 "CONTACTOR_STATE_SNA" 7 "CONTACTOR_STATE_WELDED" ;
VAL_ 522 HVP_packContPositiveState 3 "CONTACTOR_STATE_BLOCKED" 6 "CONTACTOR_STATE_ECONOMIZED" 1 "CONTACTOR_STATE_OPEN" 5 "CONTACTOR_STATE_OPENING" 2 "CONTACTOR_STATE_PRECHARGE" 4 "CONTACTOR_STATE_PULLED_IN" 0 "CONTACTOR_STATE_SNA" 7 "CONTACTOR_STATE_WELDED" ;
VAL_ 522 HVP_packContactorSetState 3 "CONTACTOR_SET_STATE_BLOCKED" 5 "CONTACTOR_SET_STATE_CLOSED" 2 "CONTACTOR_SET_STATE_CLOSING" 9 "CONTACTOR_SET_STATE_NEGATIVE_CLOSED" 1 "CONTACTOR_SET_STATE_OPEN" 4 "CONTACTOR_SET_STATE_OPENING" 6 "CONTACTOR_SET_STATE_PARTIAL_WELD" 8 "CONTACTOR_SET_STATE_POSITIVE_CLOSED" 0 "CONTACTOR_SET_STATE_SNA" 7 "CONTACTOR_SET_STATE_WELDED" ;
VAL_ 522 HVP_packCtrsRequestStatus 1 "REQUEST_ACTIVE" 2 "REQUEST_COMPLETED" 0 "REQUEST_NOT_ACTIVE" ;
VAL_ 583 DAS_alcInternalState 2 "ALC_ABORTING" 8 "ALC_ACTIVE_ACC_LEFT" 9 "ALC_ACTIVE_ACC_RIGHT" 6 "ALC_ACTIVE_LEFT" 7 "ALC_ACTIVE_RIGHT" 3 "ALC_BEHAVIOR_CHECK" 0 "ALC_DISABLED" 1 "ALC_IDLE" 4 "ALC_PRE_ACTIVE_LEFT" 5 "ALC_PRE_ACTIVE_RIGHT" 12 "ALC_RETRY" 10 "ALC_SOFT_ABORTING_LEFT" 11 "ALC_SOFT_ABORTING_RIGHT" ;
VAL_ 583 DAS_autopilotAbortReason 21 "ABORT_ACC_CANCEL_GENERIC" 22 "ABORT_ACC_CANCEL_SILENT" 23 "ABORT_ACC_FAULT" 33 "ABORT_AEB" 18 "ABORT_CAMERA_CALIBRATION" 17 "ABORT_CAMERA_FAILSAFES" 32 "ABORT_CONTROLLER_BAD_REF_UPDATE" 27 "ABORT_CONTROLLER_NOT_ALLOWED" 25 "ABORT_CONTROLLER_REFERENCE" 34 "ABORT_CONTROLLER_REF_TOO_SHORT" 26 "ABORT_CONTROLLER_SOLVER" 31 "ABORT_CONTROLLER_STALE_LOCALIZATION" 30 "ABORT_CONTROLLER_STALE_REFERENCE" 10 "ABORT_CRUISE_FAULT" 11 "ABORT_CRUISE_NOT_ACTIVE" 2 "ABORT_DI_MIA" 16 "ABORT_EPAS_EAC_ERROR" 15 "ABORT_EPAS_EAC_NOT_ACTIVE" 4 "ABORT_EPAS_MIA" 39 "ABORT_EPAS_STEERING_ANGLE_INVALID" 3 "ABORT_ESP_MIA" 36 "ABORT_GORE_INCURSION" 5 "ABORT_GTW_MIA" 46 "ABORT_INTEGRATOR_HEALTH_CRITICAL" 41 "ABORT_INVALID_DI_PEDAL_POS" 42 "ABORT_INVALID_VEHICLE_SPEED" 29 "ABORT_MAP_HEALTH" 35 "ABORT_MISSION_PLANNER_NO_VISION_LANES_FOUND" 0 "ABORT_NONE" 43 "ABORT_PERCEPTION_HEALTH_VISION" 19 "ABORT_RADAR_BLIND" 20 "ABORT_RADAR_FAULT" 7 "ABORT_RADAR_MIA" 37 "ABORT_REACHED_END_OF_NAV_STOP" 63 "ABORT_REASON_MAX" 24 "ABORT_ROAD_ESTIMATOR_HEALTH" 6 "ABORT_SCCM_MIA" 44 "ABORT_SEATBELT_UNBUCKLED" 38 "ABORT_STEERING_SATURATED_LANE_DEPARTURE" 28 "ABORT_THERMAL_ISSUE" 13 "ABORT_TRAILER_MODE_ACTIVE" 12 "ABORT_USER_DISABLED" 45 "ABORT_USER_OVERRIDE_STRIKEOUT" 8 "ABORT_VCFRONT_MIA" 9 "ABORT_VCRIGHT_MIA" 14 "ABORT_VEHICLE_SPEED_ABOVE_MAX" 40 "ABORT_W048_FEATURES_DISABLED" 1 "ABORT_WATCHDOG_HEALTH" ;
VAL_ 583 DAS_behaviorReport 30 "BEHAVIOR_ACTIVE_SAFETY_SLOWDOWN" 2 "BEHAVIOR_CURVE_SPEED_ADAPTATION" 35 "BEHAVIOR_CUTIN_VEHICLE" 21 "BEHAVIOR_CUTIN_VEHICLE_LEFT" 22 "BEHAVIOR_CUTIN_VEHICLE_RIGHT" 14 "BEHAVIOR_DRIVABLE_SPACE_VIOLATION" 32 "BEHAVIOR_END_OF_NAV_ROUTE" 5 "BEHAVIOR_FLEET_SPEEDS" 8 "BEHAVIOR_IN_LANE_VEHICLE" 4 "BEHAVIOR_KEEP_CALM" 33 "BEHAVIOR_LANE_SPEED_DIFF" 13 "BEHAVIOR_MAP_LANE_GEOMETRY" 19 "BEHAVIOR_MERGE_VEHICLE_LEFT" 20 "BEHAVIOR_MERGE_VEHICLE_RIGHT" 29 "BEHAVIOR_MP_AP_INACTIVE" 23 "BEHAVIOR_MP_AP_RESTRICTION" 26 "BEHAVIOR_MP_AP_STATE_MACHINE" 27 "BEHAVIOR_MP_DI_CRUISE" 25 "BEHAVIOR_MP_DRIVER_MONITOR" 24 "BEHAVIOR_MP_NOT_BUCKLED" 28 "BEHAVIOR_MP_ULC" 17 "BEHAVIOR_NAV_FLEET_SPEEDS" 18 "BEHAVIOR_NAV_PATH_CSA" 3 "BEHAVIOR_RADAR_ONLY_BRAKING" 38 "BEHAVIOR_RISK_MANAGER" 15 "BEHAVIOR_SLOWING_FOR_TARGET_LANE" 34 "BEHAVIOR_STATIC_OBJECT" 36 "BEHAVIOR_STATIC_OBJECT_MERGE_LEFT" 37 "BEHAVIOR_STATIC_OBJECT_MERGE_RIGHT" 31 "BEHAVIOR_STEERING_SATURATED" 9 "BEHAVIOR_TARGET_LANE_VEHICLE" 11 "BEHAVIOR_TRAFFIC_CONTROL" 6 "BEHAVIOR_TRAFFIC_CONTROL_STOPPED_STATE" 7 "BEHAVIOR_UNDERTAKE_ASSIST_KEEP_CALM" 10 "BEHAVIOR_UNDERTAKE_VEHICLE" 1 "BEHAVIOR_VIEW_RANGE" 12 "BEHAVIOR_VISION_LANE_GEOMETRY" 16 "BEHAVIOR_VISION_SPEEDS" ;
VAL_ 583 DAS_controllerHealth 2 "CONTROLLER_CRITICAL" 1 "CONTROLLER_DEGRADED" 0 "CONTROLLER_HEALTHY" 3 "CONTROLLER_SOLVER_FAILURE" ;
VAL_ 583 DAS_controllerRef 4 "CONTROLLER_REFERENCE_BAD_REF_UPDATE" 0 "CONTROLLER_REFERENCE_HEALTHY" 6 "CONTROLLER_REFERENCE_INDETERMINATE" 5 "CONTROLLER_REFERENCE_REF_TOO_SHORT" 3 "CONTROLLER_REFERENCE_STALE_LOCALIZATION" 2 "CONTROLLER_REFERENCE_STALE_REFERENCE" 1 "CONTROLLER_REFERENCE_UNHEALTHY" ;
VAL_ 583 DAS_forkState 18 "FORK_ABORT_BLINKER_CHANGE" 17 "FORK_ABORT_CONTROL_INACTIVE" 21 "FORK_ABORT_DISALLOW" 19 "FORK_ABORT_NOT_LEFT_LANE" 20 "FORK_ABORT_NOT_RIGHT_LANE" 22 "FORK_ABORT_OTHER" 12 "FORK_ACTIVE_LEFT_NAV" 13 "FORK_ACTIVE_LEFT_USER" 14 "FORK_ACTIVE_RIGHT_NAV" 15 "FORK_ACTIVE_RIGHT_USER" 16 "FORK_FORK_COMPLETE" 8 "FORK_IDLE_BOTH_FORKS_AVAILABLE" 9 "FORK_IDLE_LEFT_FORK_AVAILABLE" 11 "FORK_IDLE_NO_FORKS_AVAILABLE" 10 "FORK_IDLE_RIGHT_FORK_AVAILABLE" 0 "FORK_INVALID" 25 "FORK_PRE_ACTIVE_LEFT_NAV" 26 "FORK_PRE_ACTIVE_RIGHT_NAV" 2 "FORK_UNAVAILABLE_AP_INACTIVE" 3 "FORK_UNAVAILABLE_CONSTRUCTION" 4 "FORK_UNAVAILABLE_CONTROLLED_ACCESS_TOO_FAR" 1 "FORK_UNAVAILABLE_DISABLED" 5 "FORK_UNAVAILABLE_DON_INACTIVE" 27 "FORK_UNAVAILABLE_INTERSECTION_ACTIVE" 7 "FORK_UNAVAILABLE_OTHER" 23 "FORK_UNAVAILABLE_TIGHT_TURN_RADIUS" 6 "FORK_UNAVAILABLE_TOLL_BOOTH" 24 "FORK_UNAVAILABLE_WEATHER" ;
VAL_ 583 DAS_laneChangeState 19 "LANE_CHANGE_ABORTING_ACC_AUTOSTEER_ACTIVATED" 26 "LANE_CHANGE_ABORTING_ALC_REQUEST_BEFORE_ULC_CONFIRM" 23 "LANE_CHANGE_ABORTING_BEHAVIOR_CHANGED" 22 "LANE_CHANGE_ABORTING_BELOW_MIN_SPEED" 14 "LANE_CHANGE_ABORTING_BLIND_SPOT_OCCUPIED" 12 "LANE_CHANGE_ABORTING_BLINKER" 32 "LANE_CHANGE_ABORTING_CONSTRUCTION_DETECTED" 17 "LANE_CHANGE_ABORTING_FORK_AVAILABLE" 31 "LANE_CHANGE_ABORTING_GORE_POINT" 24 "LANE_CHANGE_ABORTING_HIGH_ALC_PROGRESS_ERROR" 11 "LANE_CHANGE_ABORTING_INACTIVE" 21 "LANE_CHANGE_ABORTING_INVALID_BEHAVIOR" 15 "LANE_CHANGE_ABORTING_INVALID_MODE" 16 "LANE_CHANGE_ABORTING_LINE_TYPE" 18 "LANE_CHANGE_ABORTING_LOST_VISION_POSE" 37 "LANE_CHANGE_ABORTING_NO_HANDS_ON" 40 "LANE_CHANGE_ABORTING_SNOOZED" 39 "LANE_CHANGE_ABORTING_SOURCE_AND_TARGET_LANES_MERGED" 34 "LANE_CHANGE_ABORTING_TIGHT_TURN_RADIUS" 13 "LANE_CHANGE_ABORTING_TIMEOUT" 33 "LANE_CHANGE_ABORTING_TOLL_BOOTH_DETECTED" 20 "LANE_CHANGE_ABORTING_ULC_BLINKER_TIMEOUT" 25 "LANE_CHANGE_ABORTING_ULC_CONFIRMATION_TIMEOUT" 35 "LANE_CHANGE_ABORTING_WEATHER" 10 "LANE_CHANGE_AVAILABLE_BOTH" 8 "LANE_CHANGE_AVAILABLE_LEFT_ONLY" 9 "LANE_CHANGE_AVAILABLE_RIGHT_ONLY" 29 "LANE_CHANGE_BLOCKED_LEFT" 30 "LANE_CHANGE_BLOCKED_RIGHT" 27 "LANE_CHANGE_IN_PROGRESS_LEFT" 28 "LANE_CHANGE_IN_PROGRESS_RIGHT" 42 "LANE_CHANGE_UNAVAILABLE_AUTOPILOT_ABORTING" 36 "LANE_CHANGE_UNAVAILABLE_BLINDSPOT_RESTRICTED" 41 "LANE_CHANGE_UNAVAILABLE_BLINKER_LATCHED" 0 "LANE_CHANGE_UNAVAILABLE_DISABLED" 5 "LANE_CHANGE_UNAVAILABLE_FORK_MODE" 4 "LANE_CHANGE_UNAVAILABLE_INACTIVE" 7 "LANE_CHANGE_UNAVAILABLE_INVALID_MODE" 3 "LANE_CHANGE_UNAVAILABLE_NO_LANES" 38 "LANE_CHANGE_UNAVAILABLE_NO_REAR_OBJECT" 1 "LANE_CHANGE_UNAVAILABLE_ROAD_NOT_APPROPRIATE" 2 "LANE_CHANGE_UNAVAILABLE_SPEED" 6 "LANE_CHANGE_UNAVAILABLE_ULTRASONICS_NOT_READY" 63 "LANE_CHANGE_UNKNOWN" ;
VAL_ 583 DAS_lastWatchdogCode 68 "ACTIVE_SAFETY_FAILED" 51 "AP_STATE_MACHINE_FAILED" 50 "ARBITER_FAILED" 57 "ATLAS_FAILED" 79 "BEV_GRAPH_FAILED" 77 "BRIDGE_FAILED" 67 "CAMERA_FAILED" 45 "CAN_RX_FAILED" 46 "CAN_TX_FAILED" 78 "CITY_STREETS_BEHAVIOR_FAILED" 74 "CLIP_LOGGER_FAILED" 52 "CONTROLLER_FAILED" 75 "DRIVABLE_SPACE_TRACKER_FAILED" 65 "DRIVER_MONITOR_FAILED" 70 "DYNAMICS_FAILED" 71 "FIELD_CALIBRATION_FAILED" 49 "GPS_FAILED" 61 "IMU_FAILED" 48 "INERTIATOR_FAILED" 73 "KMSG_MONITOR_FAILED" 63 "LANE_CHANGE_BEHAVIOR_FAILED" 43 "LEGACY_FAILED" 53 "LOCALIZER_FAILED" 66 "MAP_MANAGER_FAILED" 54 "MISSION_PLANNER_FAILED" 0 "NO_TASK_FAILED" 72 "PARKING_BEHAVIOR_FAILED" 55 "PERCEPTION_FAILED" 60 "RAIN_LIGHT_SENSING_FAILED" 56 "ROAD_ESTIMATOR_FAILED" 76 "SCHEDULER_FAILED" 41 "SNAPSHOT_FAILED" 59 "SNAPSHOT_TRIGGER_CLIENT_FAILED" 58 "STAY_IN_LANE_BEHAVIOR_FAILED" 40 "TELEMETRY_FAILED" 39 "TELEMETRY_PACKAGER_FAILED" 47 "TEMPERATURE_MONITOR_FAILED" 62 "UBX_LOG_FAILED" 69 "UI_SERVER_FAILED" 30 "UNKNOWN_TASK_FAILED" 42 "VISION_FAILED" 44 "WATCHDOG_FAILED" ;
VAL_ 583 DAS_localizerHealth 0 "LOCALIZER_CRITICAL" 1 "LOCALIZER_DEGRADED" 8 "LOCALIZER_FINE_LOCALIZED_CONFIRMED" 7 "LOCALIZER_FINE_LOCALIZED_STICKING" 6 "LOCALIZER_LANE_LOCALIZED" 5 "LOCALIZER_NEAR_LANE_LOCALIZED" 3 "LOCALIZER_NO_LANE_LOCALIZED" 2 "LOCALIZER_RECOVERING" 4 "LOCALIZER_SHADOW" ;
VAL_ 583 DAS_mapAvailability 1 "APM_MAP_AVAILABLE" 0 "APM_MAP_NOT_AVAILABLE" ;
VAL_ 583 DAS_missionPlan 3 "MISSION_PLAN_INVALID" 2 "MISSION_PLAN_MAP_AND_VISION" 0 "MISSION_PLAN_MAP_ONLY" 1 "MISSION_PLAN_VISION_ONLY" ;
VAL_ 583 DAS_roadEstimator 3 "ROAD_ESTIMATOR_CRITICAL" 2 "ROAD_ESTIMATOR_DEGRADED" 0 "ROAD_ESTIMATOR_HEALTHY" 1 "ROAD_ESTIMATOR_UNSTABLE_MEASUREMENTS" ;
VAL_ 583 DAS_rqstedBehaviorStatus 19 "RQST_BEHAVIOR_BAD_ORIGIN_UPDATE" 9 "RQST_BEHAVIOR_BLOCKED_BY_BLINDSPOT_CAMERA_INVALID_L" 14 "RQST_BEHAVIOR_BLOCKED_BY_BLINDSPOT_CAMERA_INVALID_R" 8 "RQST_BEHAVIOR_BLOCKED_BY_BLINDSPOT_CAMERA_L" 13 "RQST_BEHAVIOR_BLOCKED_BY_BLINDSPOT_CAMERA_R" 11 "RQST_BEHAVIOR_BLOCKED_BY_LANE_TYPE_L" 16 "RQST_BEHAVIOR_BLOCKED_BY_LANE_TYPE_R" 20 "RQST_BEHAVIOR_BLOCKED_BY_SLOW_TARGET_L" 21 "RQST_BEHAVIOR_BLOCKED_BY_SLOW_TARGET_R" 10 "RQST_BEHAVIOR_BLOCKED_BY_ULTRASOUND_AND_CAMERA_L" 15 "RQST_BEHAVIOR_BLOCKED_BY_ULTRASOUND_AND_CAMERA_R" 7 "RQST_BEHAVIOR_BLOCKED_BY_ULTRASOUND_L" 12 "RQST_BEHAVIOR_BLOCKED_BY_ULTRASOUND_R" 6 "RQST_BEHAVIOR_BUILD_ARGUMENT_FAIL" 22 "RQST_BEHAVIOR_INVALID_PLAN" 3 "RQST_BEHAVIOR_MAP_NOT_INITIALIZED" 2 "RQST_BEHAVIOR_NO_DEST_POLYLANE" 4 "RQST_BEHAVIOR_NO_SOURCE_LANE_ON_MAP" 1 "RQST_BEHAVIOR_NO_SRC_POLYLANE" 5 "RQST_BEHAVIOR_NO_TARGET_LANE_ON_MAP" 18 "RQST_BEHAVIOR_OUT_OF_DATE" 17 "RQST_BEHAVIOR_ROAD_NOT_APPROPRIATE" 0 "RQST_BEHAVIOR_VALID" ;
VAL_ 1013 VCFRONT_DRLLeftStatus 2 "LIGHT_FAULT" 0 "LIGHT_OFF" 1 "LIGHT_ON" 3 "LIGHT_SNA" ;
VAL_ 1013 VCFRONT_DRLRightStatus 2 "LIGHT_FAULT" 0 "LIGHT_OFF" 1 "LIGHT_ON" 3 "LIGHT_SNA" ;
VAL_ 1013 VCFRONT_ambientLightingBrightnes 255 "SNA" ;
VAL_ 1013 VCFRONT_fogLeftStatus 2 "LIGHT_FAULT" 0 "LIGHT_OFF" 1 "LIGHT_ON" 3 "LIGHT_SNA" ;
VAL_ 1013 VCFRONT_fogRightStatus 2 "LIGHT_FAULT" 0 "LIGHT_OFF" 1 "LIGHT_ON" 3 "LIGHT_SNA" ;
VAL_ 1013 VCFRONT_hazardLightRequest 1 "HAZARD_REQUEST_BUTTON" 6 "HAZARD_REQUEST_CAR_ALARM" 5 "HAZARD_REQUEST_CRASH" 7 "HAZARD_REQUEST_DAS" 2 "HAZARD_REQUEST_LOCK" 4 "HAZARD_REQUEST_MISLOCK" 0 "HAZARD_REQUEST_NONE" 8 "HAZARD_REQUEST_UDS" 3 "HAZARD_REQUEST_UNLOCK" ;
VAL_ 1013 VCFRONT_highBeamLeftStatus 2 "LIGHT_FAULT" 0 "LIGHT_OFF" 1 "LIGHT_ON" 3 "LIGHT_SNA" ;
VAL_ 1013 VCFRONT_highBeamRightStatus 2 "LIGHT_FAULT" 0 "LIGHT_OFF" 1 "LIGHT_ON" 3 "LIGHT_SNA" ;
VAL_ 1013 VCFRONT_indicatorLeftRequest 2 "TURN_SIGNAL_ACTIVE_HIGH" 1 "TURN_SIGNAL_ACTIVE_LOW" 0 "TURN_SIGNAL_OFF" ;
VAL_ 1013 VCFRONT_indicatorRightRequest 2 "TURN_SIGNAL_ACTIVE_HIGH" 1 "TURN_SIGNAL_ACTIVE_LOW" 0 "TURN_SIGNAL_OFF" ;
VAL_ 1013 VCFRONT_lowBeamLeftStatus 2 "LIGHT_FAULT" 0 "LIGHT_OFF" 1 "LIGHT_ON" 3 "LIGHT_SNA" ;
VAL_ 1013 VCFRONT_lowBeamRightStatus 2 "LIGHT_FAULT" 0 "LIGHT_OFF" 1 "LIGHT_ON" 3 "LIGHT_SNA" ;
VAL_ 1013 VCFRONT_parkLeftStatus 2 "LIGHT_FAULT" 0 "LIGHT_OFF" 1 "LIGHT_ON" 3 "LIGHT_SNA" ;
VAL_ 1013 VCFRONT_parkRightStatus 2 "LIGHT_FAULT" 0 "LIGHT_OFF" 1 "LIGHT_ON" 3 "LIGHT_SNA" ;
VAL_ 1013 VCFRONT_sideMarkersStatus 2 "LIGHT_FAULT" 0 "LIGHT_OFF" 1 "LIGHT_ON" 3 "LIGHT_SNA" ;
VAL_ 1013 VCFRONT_sideRepeaterLeftStatus 2 "LIGHT_FAULT" 0 "LIGHT_OFF" 1 "LIGHT_ON" 3 "LIGHT_SNA" ;
VAL_ 1013 VCFRONT_sideRepeaterRightStatus 2 "LIGHT_FAULT" 0 "LIGHT_OFF" 1 "LIGHT_ON" 3 "LIGHT_SNA" ;
VAL_ 1013 VCFRONT_simLatchingStalk 0 "SIMULATED_LATCHING_STALK_IDLE" 1 "SIMULATED_LATCHING_STALK_LEFT" 2 "SIMULATED_LATCHING_STALK_RIGHT" 3 "SIMULATED_LATCHING_STALK_SNA" ;
VAL_ 1013 VCFRONT_switchLightingBrightness 255 "SNA" ;
VAL_ 1013 VCFRONT_turnSignalLeftStatus 2 "LIGHT_FAULT" 0 "LIGHT_OFF" 1 "LIGHT_ON" 3 "LIGHT_SNA" ;
VAL_ 1013 VCFRONT_turnSignalRightStatus 2 "LIGHT_FAULT" 0 "LIGHT_OFF" 1 "LIGHT_ON" 3 "LIGHT_SNA" ;
VAL_ 1001 DAS_hazardLightRequest 0 "DAS_REQUEST_HAZARDS_OFF" 1 "DAS_REQUEST_HAZARDS_ON" 3 "DAS_REQUEST_HAZARDS_SNA" 2 "DAS_REQUEST_HAZARDS_UNUSED" ;
VAL_ 1001 DAS_headlightRequest 3 "DAS_HEADLIGHT_REQUEST_INVALID" 0 "DAS_HEADLIGHT_REQUEST_OFF" 1 "DAS_HEADLIGHT_REQUEST_ON" ;
VAL_ 1001 DAS_heaterRequest 1 "DAS_HEATER_OFF" 2 "DAS_HEATER_ON" 0 "DAS_HEATER_SNA" ;
VAL_ 1001 DAS_highLowBeamDecision 1 "DAS_HIGH_BEAM_OFF" 2 "DAS_HIGH_BEAM_ON" 3 "DAS_HIGH_BEAM_SNA" 0 "DAS_HIGH_BEAM_UNDECIDED" ;
VAL_ 1001 DAS_highLowBeamOffReason 3 "HIGH_BEAM_OFF_REASON_AMBIENT_LIGHT" 4 "HIGH_BEAM_OFF_REASON_HEAD_LIGHT" 2 "HIGH_BEAM_OFF_REASON_MOVING_RADAR_TARGET" 1 "HIGH_BEAM_OFF_REASON_MOVING_VISION_TARGET" 5 "HIGH_BEAM_OFF_REASON_SNA" 0 "HIGH_BEAM_ON" ;
VAL_ 1001 DAS_turnIndicatorRequest 3 "DAS_TURN_INDICATOR_CANCEL" 4 "DAS_TURN_INDICATOR_DEFER" 1 "DAS_TURN_INDICATOR_LEFT" 0 "DAS_TURN_INDICATOR_NONE" 2 "DAS_TURN_INDICATOR_RIGHT" ;
VAL_ 1001 DAS_turnIndicatorRequestReason 8 "DAS_ACTIVE_COMMANDED_LANE_CHANGE" 3 "DAS_ACTIVE_FORK" 9 "DAS_ACTIVE_INTERSECTION" 6 "DAS_ACTIVE_MERGE" 1 "DAS_ACTIVE_NAV_LANE_CHANGE" 2 "DAS_ACTIVE_SPEED_LANE_CHANGE" 11 "DAS_ACTIVE_SUMMMON" 5 "DAS_CANCEL_FORK" 10 "DAS_CANCEL_INTERSECTION" 4 "DAS_CANCEL_LANE_CHANGE" 7 "DAS_CANCEL_MERGE" 12 "DAS_CANCEL_SUMMMON" 0 "DAS_NONE" ;
VAL_ 1001 DAS_wiperSpeed 1 "DAS_WIPER_SPEED_1" 10 "DAS_WIPER_SPEED_10" 11 "DAS_WIPER_SPEED_11" 12 "DAS_WIPER_SPEED_12" 13 "DAS_WIPER_SPEED_13" 14 "DAS_WIPER_SPEED_14" 2 "DAS_WIPER_SPEED_2" 3 "DAS_WIPER_SPEED_3" 4 "DAS_WIPER_SPEED_4" 5 "DAS_WIPER_SPEED_5" 6 "DAS_WIPER_SPEED_6" 7 "DAS_WIPER_SPEED_7" 8 "DAS_WIPER_SPEED_8" 9 "DAS_WIPER_SPEED_9" 15 "DAS_WIPER_SPEED_INVALID" 0 "DAS_WIPER_SPEED_OFF" ;
VAL_ 611 VCRIGHT_logging10HzIndex 3 "END" 1 "HVAC_ACTUATOR_POSITIONS" 2 "HVAC_ACTUATOR_STATE" 0 "HVAC_ACTUATOR_TARGETS" ;
VAL_ 611 VCRIGHT_hvacIntakeActuatorState 0 "HVACACTUATOR_STATE_BRAKING" 2 "HVACACTUATOR_STATE_COASTING" 1 "HVACACTUATOR_STATE_RUNNING" ;
VAL_ 611 VCRIGHT_hvacIntakeOperationMode 1 "HVACACTUATOR_OPERATION_MODE_CALIBRATION" 0 "HVACACTUATOR_OPERATION_MODE_NORMAL" ;
VAL_ 611 VCRIGHT_hvacLHBleedActuatorState 0 "HVACACTUATOR_STATE_BRAKING" 2 "HVACACTUATOR_STATE_COASTING" 1 "HVACACTUATOR_STATE_RUNNING" ;
VAL_ 611 VCRIGHT_hvacLHBleedOperationMode 1 "HVACACTUATOR_OPERATION_MODE_CALIBRATION" 0 "HVACACTUATOR_OPERATION_MODE_NORMAL" ;
VAL_ 611 VCRIGHT_hvacLHVaneActuatorState 0 "HVACACTUATOR_STATE_BRAKING" 2 "HVACACTUATOR_STATE_COASTING" 1 "HVACACTUATOR_STATE_RUNNING" ;
VAL_ 611 VCRIGHT_hvacLHVaneOperationMode 1 "HVACACTUATOR_OPERATION_MODE_CALIBRATION" 0 "HVACACTUATOR_OPERATION_MODE_NORMAL" ;
VAL_ 611 VCRIGHT_hvacLowerModeActState 0 "HVACACTUATOR_STATE_BRAKING" 2 "HVACACTUATOR_STATE_COASTING" 1 "HVACACTUATOR_STATE_RUNNING" ;
VAL_ 611 VCRIGHT_hvacLowerModeOpMode 1 "HVACACTUATOR_OPERATION_MODE_CALIBRATION" 0 "HVACACTUATOR_OPERATION_MODE_NORMAL" ;
VAL_ 611 VCRIGHT_hvacModelInitStatus 4 "INIT_FORWARD_CALC" 2 "INIT_FROM_SENSORS" 3 "INIT_FROM_SENSORS_PREDICTION_ERROR" 5 "INIT_WAITING_FOR_SENSORS" 1 "NOT_INIT_WAIT_FOR_GTW" 0 "NOT_INIT_WAIT_FOR_SENSORS" ;
VAL_ 611 VCRIGHT_hvacRHBleedActuatorState 0 "HVACACTUATOR_STATE_BRAKING" 2 "HVACACTUATOR_STATE_COASTING" 1 "HVACACTUATOR_STATE_RUNNING" ;
VAL_ 611 VCRIGHT_hvacRHBleedOperationMode 1 "HVACACTUATOR_OPERATION_MODE_CALIBRATION" 0 "HVACACTUATOR_OPERATION_MODE_NORMAL" ;
VAL_ 611 VCRIGHT_hvacRHVaneActuatorState 0 "HVACACTUATOR_STATE_BRAKING" 2 "HVACACTUATOR_STATE_COASTING" 1 "HVACACTUATOR_STATE_RUNNING" ;
VAL_ 611 VCRIGHT_hvacRHVaneOperationMode 1 "HVACACTUATOR_OPERATION_MODE_CALIBRATION" 0 "HVACACTUATOR_OPERATION_MODE_NORMAL" ;
VAL_ 611 VCRIGHT_hvacUpperModeActState 0 "HVACACTUATOR_STATE_BRAKING" 2 "HVACACTUATOR_STATE_COASTING" 1 "HVACACTUATOR_STATE_RUNNING" ;
VAL_ 611 VCRIGHT_hvacUpperModeOpMode 1 "HVACACTUATOR_OPERATION_MODE_CALIBRATION" 0 "HVACACTUATOR_OPERATION_MODE_NORMAL" ;
VAL_ 615 DI_massConfidence 1 "MASS_CONFIDED" 0 "MASS_NOT_CONFIDED" ;
VAL_ 615 DI_tireFitment 3 "FITMENT_SNA" 0 "FITMENT_SQUARE" 1 "FITMENT_STAGGERED" ;
VAL_ 615 DI_trailerDetected 1 "TRAILER_DETECTED" 0 "TRAILER_NOT_DETECTED" ;
VAL_ 642 VCLEFT_blowerIndex 0 "HVAC_FEEDBACK_SIGNALS" 1 "HVAC_VARS" ;
VAL_ 642 VCLEFT_hvacBlowerCBCCtrlState 4 "COUNT" 0 "ERROR" 1 "IDLE" 2 "OFFLINE" 3 "ONLINE" ;
VAL_ 642 VCLEFT_hvacBlowerCBCEstState 14 "COUNT" 0 "ERROR" 1 "IDLE" 5 "IDRATED" 10 "INDUCTANCE_EST" 9 "LOCKROTOR" 12 "MOTOR_IDENTIFIED" 13 "ONLINE" 8 "RAMPDOWN" 4 "RAMPUP" 7 "RATEDFLUX" 6 "RATEDFLUX_OL" 11 "ROTOR_RESISTANCE" 2 "ROVERL" 3 "RS" ;
VAL_ 642 VCLEFT_hvacBlowerFETTemp 127 "SNA" ;
VAL_ 642 VCLEFT_hvacBlowerIPhase0 255 "SNA" ;
VAL_ 642 VCLEFT_hvacBlowerIPhase1 255 "SNA" ;
VAL_ 642 VCLEFT_hvacBlowerIPhase2 255 "SNA" ;
VAL_ 642 VCLEFT_hvacBlowerITerm 127 "SNA" ;
VAL_ 642 VCLEFT_hvacBlowerOutputDuty 127 "SNA" ;
VAL_ 642 VCLEFT_hvacBlowerRPMTarget 1023 "SNA" ;
VAL_ 642 VCLEFT_hvacBlowerRs 255 "SNA" ;
VAL_ 642 VCLEFT_hvacBlowerTorque 1023 "SNA" ;
VAL_ 642 VCLEFT_hvacBlower_IO_CBC_Status 0 "IDLE" 1 "RX" ;
VAL_ 787 UI_trackCmpOverclock 0 "TRACK_MODE_CMP_OVERCLOCK_OFF" 1 "TRACK_MODE_CMP_OVERCLOCK_ON" ;
VAL_ 787 UI_trackModeRequest 0 "TRACK_MODE_REQUEST_IDLE" 2 "TRACK_MODE_REQUEST_OFF" 1 "TRACK_MODE_REQUEST_ON" ;
VAL_ 787 UI_trackPostCooling 0 "TRACK_MODE_POST_COOLING_OFF" 1 "TRACK_MODE_POST_COOLING_ON" ;
VAL_ 821 DIR_infoIndex 13 "DI_INFO_APP_CRC" 17 "DI_INFO_APP_GITHASH" 15 "DI_INFO_BOOTLOADER_CRC" 18 "DI_INFO_BOOTLOADER_GITHASH" 14 "DI_INFO_BOOTLOADER_SVN" 10 "DI_INFO_BUILD_HWID_COMPONENTID" 0 "DI_INFO_DEPRECATED_0" 1 "DI_INFO_DEPRECATED_1" 2 "DI_INFO_DEPRECATED_2" 3 "DI_INFO_DEPRECATED_3" 4 "DI_INFO_DEPRECATED_4" 5 "DI_INFO_DEPRECATED_5" 6 "DI_INFO_DEPRECATED_6" 7 "DI_INFO_DEPRECATED_7" 8 "DI_INFO_DEPRECATED_8" 9 "DI_INFO_DEPRECATED_9" 255 "DI_INFO_END" 11 "DI_INFO_PCBAID_ASSYID_USAGEID" 16 "DI_INFO_SUBCOMPONENT" 23 "DI_INFO_SUBCOMPONENT2" 31 "DI_INFO_SUBCOMPONENT_GITHASH" 20 "DI_INFO_UDS_PROTOCOL_BOOTCRC" 19 "DI_INFO_VERSION_DEPRECATED" ;
VAL_ 821 DIR_FPGA_version 254 "FPGA_VERSION_LOCAL_BUILD" 255 "FPGA_VERSION_SNA" ;
VAL_ 821 DIR_buildType 2 "INFO_LOCAL_BUILD" 4 "INFO_MFG_BUILD" 1 "INFO_PLATFORM_BUILD" 3 "INFO_TRACEABLE_CI_BUILD" 0 "INFO_UNKNOWN_BUILD" ;
VAL_ 821 DIR_hardwareId 252 "CONFIGURABLE_HWID_PLACEHOLDER" ;
VAL_ 821 DIR_oilPumpBuildType 2 "INFO_LOCAL_BUILD" 4 "INFO_MFG_BUILD" 1 "INFO_PLATFORM_BUILD" 3 "INFO_TRACEABLE_CI_BUILD" 0 "INFO_UNKNOWN_BUILD" ;
VAL_ 899 VCRIGHT_estimatedThsSolarLoad 1023 "SNA" ;
VAL_ 899 VCRIGHT_estimatedVehicleSituatio 1 "VEHICLE_SITUATION_INDOOR" 2 "VEHICLE_SITUATION_OUTDOOR" 0 "VEHICLE_SITUATION_UNKNOWN" ;
VAL_ 899 VCRIGHT_thsHumidity 255 "SNA" ;
VAL_ 899 VCRIGHT_thsSolarLoadInfrared 1023 "SNA" ;
VAL_ 899 VCRIGHT_thsSolarLoadVisible 1023 "SNA" ;
VAL_ 899 VCRIGHT_thsTemperature -128 "SNA" ;
VAL_ 915 VCRIGHT_epbmDebugIndex 2 "EPBM_HVDISCONNECT" 0 "EPBM_STATES" 1 "EPBM_TRANSITIONS" ;
VAL_ 915 VCRIGHT_cdpEnumDummy 0 "EPB_EXTERNAL_APPLY_IDLE" 2 "EPB_EXTERNAL_APPLY_INVALID" 1 "EPB_EXTERNAL_APPLY_VALID" ;
VAL_ 915 VCRIGHT_epbFaultStatus 2 "EPB_STATUS_FAULT" 3 "EPB_STATUS_FAULT_IDLE" 0 "EPB_STATUS_NOMINAL" 1 "EPB_STATUS_RETRY" ;
VAL_ 915 VCRIGHT_epbSummonState 3 "EPB_SUMMON_ACTIVE" 2 "EPB_SUMMON_ARMED" 4 "EPB_SUMMON_COMPLETE" 5 "EPB_SUMMON_FAULT" 1 "EPB_SUMMON_IDLE" 0 "EPB_SUMMON_INIT" 6 "EPB_SUMMON_UNAVAILABLE" ;
VAL_ 915 VCRIGHT_epbUnitStatus 22 "EPB_STATUS_COUNT" 2 "EPB_STATUS_DYNAMIC" 9 "EPB_STATUS_DYNAMIC_APPLYING" 20 "EPB_STATUS_DYNAMIC_PARKING" 17 "EPB_STATUS_EXTERNAL_DYNAMIC" 19 "EPB_STATUS_EXTERNAL_PARKING" 21 "EPB_STATUS_FREE_ROLL_MODE" 1 "EPB_STATUS_OPEN" 3 "EPB_STATUS_PARK" 8 "EPB_STATUS_PARKING" 12 "EPB_STATUS_PARK_PENDING" 10 "EPB_STATUS_RELEASING" 18 "EPB_STATUS_RELEASING_FOR_EXTERNAL_PARK" 5 "EPB_STATUS_SERVICE" 11 "EPB_STATUS_SERVICE_RELEASING" 4 "EPB_STATUS_START" 14 "EPB_STATUS_SUMMON" 16 "EPB_STATUS_SUMMON_PARKING" 15 "EPB_STATUS_SUMMON_RELEASING" 0 "EPB_STATUS_UNKNOWN" 6 "EPB_STATUS_WINCHMODE" 13 "EPB_STATUS_WINCHMODE_PENDING" 7 "EPB_STATUS_WINCHMODE_RELEASING" ;
VAL_ 915 VCRIGHT_epbmCaliperState 4 "EPB_SAVED_CALIPERSTATE_OPEN" 3 "EPB_SAVED_CALIPERSTATE_PARK" 2 "EPB_SAVED_CALIPERSTATE_REAPPLY" 5 "EPB_SAVED_CALIPERSTATE_SERVICE" 1 "EPB_SAVED_CALIPERSTATE_UNKNOWN" 0 "EPB_SAVED_CALIPERSTATE_UNSAVED" 6 "EPB_SAVED_CALIPERSTATE_WINCHMODE" ;
VAL_ 915 VCRIGHT_epbmFaultStatus 2 "EPB_STATUS_FAULT" 3 "EPB_STATUS_FAULT_IDLE" 0 "EPB_STATUS_NOMINAL" 1 "EPB_STATUS_RETRY" ;
VAL_ 915 VCRIGHT_epbmSummonState 3 "EPB_SUMMON_ACTIVE" 2 "EPB_SUMMON_ARMED" 4 "EPB_SUMMON_COMPLETE" 5 "EPB_SUMMON_FAULT" 1 "EPB_SUMMON_IDLE" 0 "EPB_SUMMON_INIT" 6 "EPB_SUMMON_UNAVAILABLE" ;
VAL_ 915 VCRIGHT_epbmSystemStatus 3 "EPB_VEHICLE_STATUS_DYNAMIC" 6 "EPB_VEHICLE_STATUS_FAULT" 7 "EPB_VEHICLE_STATUS_FAULT_SECURE" 8 "EPB_VEHICLE_STATUS_MISMATCH" 2 "EPB_VEHICLE_STATUS_PARKED" 4 "EPB_VEHICLE_STATUS_PARKING" 1 "EPB_VEHICLE_STATUS_RELEASED" 5 "EPB_VEHICLE_STATUS_RELEASING" 0 "EPB_VEHICLE_STATUS_UNKNOWN" ;
VAL_ 915 VCRIGHT_summonFaultReason 7 "EPB_SUMMONFAULT_DAS_FAULT" 2 "EPB_SUMMONFAULT_DAS_MIA" 6 "EPB_SUMMONFAULT_DI_APC_FAULT" 5 "EPB_SUMMONFAULT_DI_FAULT" 1 "EPB_SUMMONFAULT_DI_MIA" 20 "EPB_SUMMONFAULT_DI_STATE_INVALID" 10 "EPB_SUMMONFAULT_EAC_NOT_ALLOWED" 4 "EPB_SUMMONFAULT_EPBM_MIA" 11 "EPB_SUMMONFAULT_EPBM_REQUEST" 22 "EPB_SUMMONFAULT_EPBREMOTE_MIA" 19 "EPB_SUMMONFAULT_EPB_FAULT" 8 "EPB_SUMMONFAULT_ESP_FAULT" 3 "EPB_SUMMONFAULT_ESP_MIA" 13 "EPB_SUMMONFAULT_EXTERNAL" 27 "EPB_SUMMONFAULT_INVALID_REMOTE_STATE" 24 "EPB_SUMMONFAULT_LOCAL_UNIT_FAULTED" 18 "EPB_SUMMONFAULT_MISMATCH" 0 "EPB_SUMMONFAULT_NONE" 17 "EPB_SUMMONFAULT_OOC" 14 "EPB_SUMMONFAULT_PARK_MIA" 21 "EPB_SUMMONFAULT_PASSIVE_REQUEST" 15 "EPB_SUMMONFAULT_PM_MIA" 16 "EPB_SUMMONFAULT_PM_REQUEST" 28 "EPB_SUMMONFAULT_REMOTE_DID_NOT_START" 23 "EPB_SUMMONFAULT_REMOTE_SUMMON_FAULTED" 25 "EPB_SUMMONFAULT_REMOTE_UNIT_FAULTED" 12 "EPB_SUMMONFAULT_SPEED" 26 "EPB_SUMMONFAULT_START_IN_UNAVAILABLE" 9 "EPB_SUMMONFAULT_VEH_CAN_FAULT" ;
VAL_ 963 VCRIGHT_frontBuckleSwitch 3 "SWITCH_FAULT" 1 "SWITCH_OFF" 2 "SWITCH_ON" 0 "SWITCH_SNA" ;
VAL_ 963 VCRIGHT_frontOccupancySwitch 3 "SWITCH_FAULT" 1 "SWITCH_OFF" 2 "SWITCH_ON" 0 "SWITCH_SNA" ;
VAL_ 963 VCRIGHT_frontSeatBackrestBack 3 "SWITCH_FAULT" 1 "SWITCH_OFF" 2 "SWITCH_ON" 0 "SWITCH_SNA" ;
VAL_ 963 VCRIGHT_frontSeatBackrestForward 3 "SWITCH_FAULT" 1 "SWITCH_OFF" 2 "SWITCH_ON" 0 "SWITCH_SNA" ;
VAL_ 963 VCRIGHT_frontSeatLiftDown 3 "SWITCH_FAULT" 1 "SWITCH_OFF" 2 "SWITCH_ON" 0 "SWITCH_SNA" ;
VAL_ 963 VCRIGHT_frontSeatLiftUp 3 "SWITCH_FAULT" 1 "SWITCH_OFF" 2 "SWITCH_ON" 0 "SWITCH_SNA" ;
VAL_ 963 VCRIGHT_frontSeatLumbarDown 3 "SWITCH_FAULT" 1 "SWITCH_OFF" 2 "SWITCH_ON" 0 "SWITCH_SNA" ;
VAL_ 963 VCRIGHT_frontSeatLumbarIn 3 "SWITCH_FAULT" 1 "SWITCH_OFF" 2 "SWITCH_ON" 0 "SWITCH_SNA" ;
VAL_ 963 VCRIGHT_frontSeatLumbarOut 3 "SWITCH_FAULT" 1 "SWITCH_OFF" 2 "SWITCH_ON" 0 "SWITCH_SNA" ;
VAL_ 963 VCRIGHT_frontSeatLumbarUp 3 "SWITCH_FAULT" 1 "SWITCH_OFF" 2 "SWITCH_ON" 0 "SWITCH_SNA" ;
VAL_ 963 VCRIGHT_frontSeatTiltDown 3 "SWITCH_FAULT" 1 "SWITCH_OFF" 2 "SWITCH_ON" 0 "SWITCH_SNA" ;
VAL_ 963 VCRIGHT_frontSeatTiltUp 3 "SWITCH_FAULT" 1 "SWITCH_OFF" 2 "SWITCH_ON" 0 "SWITCH_SNA" ;
VAL_ 963 VCRIGHT_frontSeatTrackBack 3 "SWITCH_FAULT" 1 "SWITCH_OFF" 2 "SWITCH_ON" 0 "SWITCH_SNA" ;
VAL_ 963 VCRIGHT_frontSeatTrackForward 3 "SWITCH_FAULT" 1 "SWITCH_OFF" 2 "SWITCH_ON" 0 "SWITCH_SNA" ;
VAL_ 963 VCRIGHT_rearCenterBuckleSwitch 3 "SWITCH_FAULT" 1 "SWITCH_OFF" 2 "SWITCH_ON" 0 "SWITCH_SNA" ;
VAL_ 963 VCRIGHT_rearRightBuckleSwitch 3 "SWITCH_FAULT" 1 "SWITCH_OFF" 2 "SWITCH_ON" 0 "SWITCH_SNA" ;
VAL_ 995 VCRIGHT_brakeLightStatus 2 "LIGHT_FAULT" 0 "LIGHT_OFF" 1 "LIGHT_ON" 3 "LIGHT_SNA" ;
VAL_ 995 VCRIGHT_interiorTrunkLightStatus 2 "LIGHT_FAULT" 0 "LIGHT_OFF" 1 "LIGHT_ON" 3 "LIGHT_SNA" ;
VAL_ 995 VCRIGHT_rearFogLightStatus 2 "LIGHT_FAULT" 0 "LIGHT_OFF" 1 "LIGHT_ON" 3 "LIGHT_SNA" ;
VAL_ 995 VCRIGHT_reverseLightStatus 2 "LIGHT_FAULT" 0 "LIGHT_OFF" 1 "LIGHT_ON" 3 "LIGHT_SNA" ;
VAL_ 995 VCRIGHT_tailLightStatus 2 "LIGHT_FAULT" 0 "LIGHT_OFF" 1 "LIGHT_ON" 3 "LIGHT_SNA" ;
VAL_ 995 VCRIGHT_turnSignalStatus 2 "LIGHT_FAULT" 0 "LIGHT_OFF" 1 "LIGHT_ON" 3 "LIGHT_SNA" ;
VAL_ 1622 DIF_infoIndex 13 "DI_INFO_APP_CRC" 17 "DI_INFO_APP_GITHASH" 15 "DI_INFO_BOOTLOADER_CRC" 18 "DI_INFO_BOOTLOADER_GITHASH" 14 "DI_INFO_BOOTLOADER_SVN" 10 "DI_INFO_BUILD_HWID_COMPONENTID" 0 "DI_INFO_DEPRECATED_0" 1 "DI_INFO_DEPRECATED_1" 2 "DI_INFO_DEPRECATED_2" 3 "DI_INFO_DEPRECATED_3" 4 "DI_INFO_DEPRECATED_4" 5 "DI_INFO_DEPRECATED_5" 6 "DI_INFO_DEPRECATED_6" 7 "DI_INFO_DEPRECATED_7" 8 "DI_INFO_DEPRECATED_8" 9 "DI_INFO_DEPRECATED_9" 255 "DI_INFO_END" 11 "DI_INFO_PCBAID_ASSYID_USAGEID" 16 "DI_INFO_SUBCOMPONENT" 23 "DI_INFO_SUBCOMPONENT2" 31 "DI_INFO_SUBCOMPONENT_GITHASH" 20 "DI_INFO_UDS_PROTOCOL_BOOTCRC" 19 "DI_INFO_VERSION_DEPRECATED" ;
VAL_ 1622 DIF_FPGA_version 254 "FPGA_VERSION_LOCAL_BUILD" 255 "FPGA_VERSION_SNA" ;
VAL_ 1622 DIF_buildType 2 "INFO_LOCAL_BUILD" 4 "INFO_MFG_BUILD" 1 "INFO_PLATFORM_BUILD" 3 "INFO_TRACEABLE_CI_BUILD" 0 "INFO_UNKNOWN_BUILD" ;
VAL_ 1622 DIF_hardwareId 252 "CONFIGURABLE_HWID_PLACEHOLDER" ;
VAL_ 1622 DIF_oilPumpBuildType 2 "INFO_LOCAL_BUILD" 4 "INFO_MFG_BUILD" 1 "INFO_PLATFORM_BUILD" 3 "INFO_TRACEABLE_CI_BUILD" 0 "INFO_UNKNOWN_BUILD" ;
VAL_ 768 BMS_infoIndex 13 "INFO_APP_CRC" 17 "INFO_APP_GITHASH" 15 "INFO_BOOTLOADER_CRC" 18 "INFO_BOOTLOADER_GITHASH" 14 "INFO_BOOTLOADER_SVN" 10 "INFO_BUILD_HWID_COMPONENTID" 0 "INFO_DEPRECATED_0" 1 "INFO_DEPRECATED_1" 2 "INFO_DEPRECATED_2" 3 "INFO_DEPRECATED_3" 4 "INFO_DEPRECATED_4" 5 "INFO_DEPRECATED_5" 6 "INFO_DEPRECATED_6" 7 "INFO_DEPRECATED_7" 8 "INFO_DEPRECATED_8" 9 "INFO_DEPRECATED_9" 255 "INFO_END" 27 "INFO_PACKAGE_PN_15_20" 25 "INFO_PACKAGE_PN_1_7" 26 "INFO_PACKAGE_PN_8_14" 29 "INFO_PACKAGE_SN_1_7" 30 "INFO_PACKAGE_SN_8_14" 11 "INFO_PCBAID_ASSYID_USAGEID" 16 "INFO_SUBCOMPONENT" 31 "INFO_SUBCOMPONENT_GITHASH" 20 "INFO_UDS_PROTOCOL_BOOTCRC" 22 "INFO_VARIANTCRC" 19 "INFO_VERSION_DEPRECATED" ;
VAL_ 768 BMS_buildType 2 "INFO_LOCAL_BUILD" 4 "INFO_MFG_BUILD" 1 "INFO_PLATFORM_BUILD" 3 "INFO_TRACEABLE_CI_BUILD" 0 "INFO_UNKNOWN_BUILD" ;
VAL_ 530 BMS_chgPowerAvailable 2047 "SNA" ;
VAL_ 530 BMS_contactorState 6 "BMS_CTRSET_BLOCKED" 4 "BMS_CTRSET_CLOSED" 3 "BMS_CTRSET_CLOSING" 1 "BMS_CTRSET_OPEN" 2 "BMS_CTRSET_OPENING" 0 "BMS_CTRSET_SNA" 5 "BMS_CTRSET_WELDED" ;
VAL_ 530 BMS_diLimpRequest 0 "LIMP_REQUEST_NONE" 1 "LIMP_REQUEST_WELDED" ;
VAL_ 530 BMS_ecuLogUploadRequest 1 "REQUEST_PRIORITY_1" 2 "REQUEST_PRIORITY_2" 3 "REQUEST_PRIORITY_3" 0 "REQUEST_PRIORITY_NONE" ;
VAL_ 530 BMS_hvState 1 "HV_COMING_UP" 0 "HV_DOWN" 2 "HV_GOING_DOWN" 6 "HV_UP" 4 "HV_UP_FOR_CHARGE" 5 "HV_UP_FOR_DC_CHARGE" 3 "HV_UP_FOR_DRIVE" ;
VAL_ 530 BMS_isolationResistance 1023 "SNA" ;
VAL_ 530 BMS_smStateRequest 3 "BMS_CHARGE" 5 "BMS_CLEAR_FAULT" 10 "BMS_DIAG" 1 "BMS_DRIVE" 6 "BMS_FAULT" 4 "BMS_FEIM" 9 "BMS_SNA" 0 "BMS_STANDBY" 2 "BMS_SUPPORT" 8 "BMS_TEST" 7 "BMS_WELD" ;
VAL_ 530 BMS_state 3 "BMS_CHARGE" 5 "BMS_CLEAR_FAULT" 10 "BMS_DIAG" 1 "BMS_DRIVE" 6 "BMS_FAULT" 4 "BMS_FEIM" 9 "BMS_SNA" 0 "BMS_STANDBY" 2 "BMS_SUPPORT" 8 "BMS_TEST" 7 "BMS_WELD" ;
VAL_ 530 BMS_uiChargeStatus 2 "BMS_ABOUT_TO_CHARGE" 4 "BMS_CHARGE_COMPLETE" 5 "BMS_CHARGE_STOPPED" 3 "BMS_CHARGING" 0 "BMS_DISCONNECTED" 1 "BMS_NO_POWER" ;
VAL_ 946 BMS_log2MuxId 9 "BMS_LOG2_100HZ_1KHZ_TASK_STATS" 8 "BMS_LOG2_10HZ_TASK_STATS" 7 "BMS_LOG2_1HZ_TASK_STATS" 6 "BMS_LOG2_AHR_COUNTER" 24 "BMS_LOG2_BRICK_VOLTAGE_CHANGE" 0 "BMS_LOG2_CAC1" 1 "BMS_LOG2_CAC2" 23 "BMS_LOG2_CAC3" 3 "BMS_LOG2_CHARGE_TERMINATION" 5 "BMS_LOG2_CHARGING" 10 "BMS_LOG2_CTR_RESISTANCE" 22 "BMS_LOG2_ENERGY_AND_REST_DATA" 20 "BMS_LOG2_ENERGY_RESERVE" 21 "BMS_LOG2_FC_LINK_LEAKAGE_TEST" 2 "BMS_LOG2_FLOOD_PORT" 19 "BMS_LOG2_HV_CHAIN_MODEL" 15 "BMS_LOG2_NEG_CTR_HEALTH_1" 16 "BMS_LOG2_NEG_CTR_HEALTH_2" 17 "BMS_LOG2_NEG_CTR_HEALTH_3" 18 "BMS_LOG2_NEG_CTR_HEALTH_4" 11 "BMS_LOG2_POS_CTR_HEALTH_1" 12 "BMS_LOG2_POS_CTR_HEALTH_2" 13 "BMS_LOG2_POS_CTR_HEALTH_3" 14 "BMS_LOG2_POS_CTR_HEALTH_4" 25 "BMS_LOG2_SOC_BY_OCV_CORRECTION" 4 "BMS_LOG2_VSH_TEST" ;
VAL_ 946 BMS_chargeCurrentLimitMode 1 "BMS_CHG_I_LIMIT_BRICK_TEMP_AND_V" 2 "BMS_CHG_I_LIMIT_CAC_IMBALANCE" 5 "BMS_CHG_I_LIMIT_CONFIG" 6 "BMS_CHG_I_LIMIT_HV_CHAIN" 3 "BMS_CHG_I_LIMIT_LEAKY_BUCKET" 0 "BMS_CHG_I_LIMIT_NONE" 4 "BMS_CHG_I_LIMIT_TETHERING" ;
VAL_ 946 BMS_chargeNeededReason 6 "BMS_BRICKV_LESS_THAN_FULL_CHARGE" 4 "BMS_CABLE_CYCLE_TOP_OFF" 3 "BMS_CHARGE_TARGET_INCREASED" 2 "BMS_DCH_KWH_THRESHOLD" 0 "BMS_NO_CHARGE_REASON" 1 "BMS_SOC_LESS_THAN_UI_THRESHOLD" ;
VAL_ 946 BMS_chgEndBmsHvChargeStatus 4 "BMS_CHARGE_ENABLED" 3 "BMS_CHARGE_ENABLING" 7 "BMS_CHARGE_FAULTED" 0 "BMS_CHARGE_STANDBY" 6 "BMS_EMERGENCY_SHUTDOWN" 1 "BMS_EXT_EVSE_TEST_ALLOWED" 2 "BMS_EXT_PRECHARGE_ALLOWED" 5 "BMS_GRACEFUL_SHUTDOWN" ;
VAL_ 946 BMS_chgEndChargeState 7 "CHARGE_STATE_AC_DISABLE_PCS" 4 "CHARGE_STATE_AC_ENABLE_PCS" 5 "CHARGE_STATE_CHARGING_ACTIVE" 6 "CHARGE_STATE_DC_DISABLING_CHARGER" 3 "CHARGE_STATE_DC_ENABLE_FCLINK" 2 "CHARGE_STATE_DC_EXT_ISO_CHECK" 1 "CHARGE_STATE_ENABLE_DCLINK" 0 "CHARGE_STATE_INACTIVE" ;
VAL_ 946 BMS_chgEndCpHvChargeStatus 1 "CP_CHARGE_CONNECTED" 5 "CP_CHARGE_ENABLED" 6 "CP_CHARGE_FAULTED" 0 "CP_CHARGE_INACTIVE" 2 "CP_CHARGE_STANDBY" 4 "CP_EVSE_TEST_PASSED" 3 "CP_EXT_EVSE_TEST_ACTIVE" ;
VAL_ 946 BMS_chgEndCpShutdownRequest 2 "EMERGENCY_SHUTDOWN_REQUESTED" 1 "GRACEFUL_SHUTDOWN_REQUESTED" 0 "NO_SHUTDOWN_REQUESTED" ;
VAL_ 946 BMS_chgEndEvseChargeType 2 "AC_CHARGER_PRESENT" 1 "DC_CHARGER_PRESENT" 0 "NO_CHARGER_PRESENT" ;
VAL_ 946 BMS_chgEndPcsHvChargeStatus 1 "PCS_CHARGE_BLOCKED" 2 "PCS_CHARGE_ENABLED" 3 "PCS_CHARGE_FAULTED" 0 "PCS_CHARGE_STANDBY" ;
VAL_ 946 BMS_chgEndPcsShutdownRequest 2 "EMERGENCY_SHUTDOWN_REQUESTED" 1 "GRACEFUL_SHUTDOWN_REQUESTED" 0 "NO_SHUTDOWN_REQUESTED" ;
VAL_ 946 BMS_cpChargeStatus 1 "BMS_CHARGING_ACTIVE" 2 "BMS_CHARGING_COMPLETE" 4 "BMS_CHARGING_ENABLING" 3 "BMS_CHARGING_FAULT" 0 "BMS_CHARGING_INACTIVE" 5 "BMS_CHARGING_UPDATE_IN_PROGRESS" ;
VAL_ 946 BMS_dynamicEnergyBuffer 1023 "SNA" ;
VAL_ 946 BMS_fcLinkTestDecayTime 1023 "SNA" ;
VAL_ 946 BMS_floodPortState1 2 "FLOOD_PORT_STATE_CLOSED" 4 "FLOOD_PORT_STATE_ERROR_HIGH" 1 "FLOOD_PORT_STATE_ERROR_LOW" 3 "FLOOD_PORT_STATE_OPEN" 0 "FLOOD_PORT_STATE_SNA" ;
VAL_ 946 BMS_floodPortState2 2 "FLOOD_PORT_STATE_CLOSED" 4 "FLOOD_PORT_STATE_ERROR_HIGH" 1 "FLOOD_PORT_STATE_ERROR_LOW" 3 "FLOOD_PORT_STATE_OPEN" 0 "FLOOD_PORT_STATE_SNA" ;
VAL_ 946 BMS_idealEnergyFloor 1023 "SNA" ;
VAL_ 946 BMS_negCtrCommonModeRejError -4096 "SNA" ;
VAL_ 946 BMS_negCtrCommonModeRejErrorConf 8191 "SNA" ;
VAL_ 946 BMS_negCtrDeviationConfidenceMax 8191 "SNA" ;
VAL_ 946 BMS_negCtrDeviationConfidenceMin 8191 "SNA" ;
VAL_ 946 BMS_negCtrDeviationFiltConfMax 8191 "SNA" ;
VAL_ 946 BMS_negCtrDeviationFiltConfMin 8191 "SNA" ;
VAL_ 946 BMS_negCtrDeviationFiltMax -4096 "SNA" ;
VAL_ 946 BMS_negCtrDeviationFiltMin -4096 "SNA" ;
VAL_ 946 BMS_negCtrDeviationMax -4096 "SNA" ;
VAL_ 946 BMS_negCtrDeviationMin -4096 "SNA" ;
VAL_ 946 BMS_negCtrDropCorrectedFiltMax -4096 "SNA" ;
VAL_ 946 BMS_negCtrDropCorrectedFiltMin -4096 "SNA" ;
VAL_ 946 BMS_negCtrDropCorrectedMax -4096 "SNA" ;
VAL_ 946 BMS_negCtrDropCorrectedMin -4096 "SNA" ;
VAL_ 946 BMS_negCtrOffsetError -4096 "SNA" ;
VAL_ 946 BMS_negCtrOffsetErrorConf 8191 "SNA" ;
VAL_ 946 BMS_negCtrResistance -4096 "SNA" ;
VAL_ 946 BMS_negCtrResistanceConfidence 8191 "SNA" ;
VAL_ 946 BMS_posCtrCommonModeRejError -4096 "SNA" ;
VAL_ 946 BMS_posCtrCommonModeRejErrorConf 8191 "SNA" ;
VAL_ 946 BMS_posCtrDeviationConfidenceMax 8191 "SNA" ;
VAL_ 946 BMS_posCtrDeviationConfidenceMin 8191 "SNA" ;
VAL_ 946 BMS_posCtrDeviationFiltConfMax 8191 "SNA" ;
VAL_ 946 BMS_posCtrDeviationFiltConfMin 8191 "SNA" ;
VAL_ 946 BMS_posCtrDeviationFiltMax -4096 "SNA" ;
VAL_ 946 BMS_posCtrDeviationFiltMin -4096 "SNA" ;
VAL_ 946 BMS_posCtrDeviationMax -4096 "SNA" ;
VAL_ 946 BMS_posCtrDeviationMin -4096 "SNA" ;
VAL_ 946 BMS_posCtrDropCorrectedFiltMax -4096 "SNA" ;
VAL_ 946 BMS_posCtrDropCorrectedFiltMin -4096 "SNA" ;
VAL_ 946 BMS_posCtrDropCorrectedMax -4096 "SNA" ;
VAL_ 946 BMS_posCtrDropCorrectedMin -4096 "SNA" ;
VAL_ 946 BMS_posCtrOffsetError -4096 "SNA" ;
VAL_ 946 BMS_posCtrOffsetErrorConf 8191 "SNA" ;
VAL_ 946 BMS_posCtrResistance -4096 "SNA" ;
VAL_ 946 BMS_posCtrResistanceConfidence 8191 "SNA" ;
VAL_ 800 BMS_matrixIndex 0 "BMS_AlertMatrix0" 1 "BMS_AlertMatrix1" 2 "BMS_AlertMatrix2" ;
VAL_ 796 CC_currentLimit 255 "SNA" ;
VAL_ 796 CC_gridGrounding 1 "CC_GRID_GROUNDING_IT_SplitPhase" 2 "CC_GRID_GROUNDING_SNA" 0 "CC_GRID_GROUNDING_TN_TT" ;
VAL_ 796 CC_line1Voltage 511 "SNA" ;
VAL_ 796 CC_line2Voltage 511 "SNA" ;
VAL_ 796 CC_line3Voltage 511 "SNA" ;
VAL_ 796 CC_numPhases 0 "SNA" ;
VAL_ 796 CC_pilotState 2 "CC_PILOT_STATE_FAULTED" 1 "CC_PILOT_STATE_IDLE" 0 "CC_PILOT_STATE_READY" 3 "CC_PILOT_STATE_SNA" ;
VAL_ 797 CC_chgStatus2Index 0 "Mux0" ;
VAL_ 797 CC_buttonState 1 "CC_BUTTON_PRESSED" 0 "CC_BUTTON_RELEASED" ;
VAL_ 812 CC_logIndex 0 "Mux0" 1 "Mux1" 10 "Mux10" 11 "Mux11" 12 "Mux12" 13 "Mux13" 2 "Mux2" 3 "Mux3" 4 "Mux4" ;
VAL_ 812 CC_activeConnectorID 255 "SNA" ;
VAL_ 812 CC_conn1Current 255 "SNA" ;
VAL_ 812 CC_conn2Current 255 "SNA" ;
VAL_ 812 CC_conn3Current 255 "SNA" ;
VAL_ 812 CC_conn4Current 255 "SNA" ;
VAL_ 812 CC_contactor1Closed 1 "CC_CONTACTOR_CLOSED" 0 "CC_CONTACTOR_OPEN" 3 "CC_CONTACTOR_SNA" ;
VAL_ 812 CC_contactor2Closed 1 "CC_CONTACTOR_CLOSED" 0 "CC_CONTACTOR_OPEN" 3 "CC_CONTACTOR_SNA" ;
VAL_ 812 CC_temperature1 127 "SNA" ;
VAL_ 812 CC_temperature2 127 "SNA" ;
VAL_ 812 CC_temperature3 127 "SNA" ;
VAL_ 812 CC_temperature4 127 "SNA" ;
VAL_ 573 CP_chargeShutdownRequest 2 "EMERGENCY_SHUTDOWN_REQUESTED" 1 "GRACEFUL_SHUTDOWN_REQUESTED" 0 "NO_SHUTDOWN_REQUESTED" ;
VAL_ 573 CP_hvChargeStatus 1 "CP_CHARGE_CONNECTED" 5 "CP_CHARGE_ENABLED" 6 "CP_CHARGE_FAULTED" 0 "CP_CHARGE_INACTIVE" 2 "CP_CHARGE_STANDBY" 4 "CP_EVSE_TEST_PASSED" 3 "CP_EXT_EVSE_TEST_ACTIVE" ;
VAL_ 1085 CP_chargeShutdownRequest_log 2 "EMERGENCY_SHUTDOWN_REQUESTED" 1 "GRACEFUL_SHUTDOWN_REQUESTED" 0 "NO_SHUTDOWN_REQUESTED" ;
VAL_ 1085 CP_evseChargeType_log 2 "AC_CHARGER_PRESENT" 1 "DC_CHARGER_PRESENT" 0 "NO_CHARGER_PRESENT" ;
VAL_ 1085 CP_hvChargeStatus_log 1 "CP_CHARGE_CONNECTED" 5 "CP_CHARGE_ENABLED" 6 "CP_CHARGE_FAULTED" 0 "CP_CHARGE_INACTIVE" 2 "CP_CHARGE_STANDBY" 4 "CP_EVSE_TEST_PASSED" 3 "CP_EXT_EVSE_TEST_ACTIVE" ;
VAL_ 541 CP_acChargeState 1 "AC_CHARGE_CONNECTED_CHARGE_BLOCKED" 3 "AC_CHARGE_ENABLED" 6 "AC_CHARGE_FAULT" 0 "AC_CHARGE_INACTIVE" 4 "AC_CHARGE_ONBOARD_CHARGER_SHUTDOWN" 2 "AC_CHARGE_STANDBY" 5 "AC_CHARGE_VEH_SHUTDOWN" ;
VAL_ 541 CP_cableType 2 "CHG_CABLE_TYPE_GB_AC" 3 "CHG_CABLE_TYPE_GB_DC" 0 "CHG_CABLE_TYPE_IEC" 1 "CHG_CABLE_TYPE_SAE" 4 "CHG_CABLE_TYPE_SNA" ;
VAL_ 541 CP_evseChargeType_UI 2 "AC_CHARGER_PRESENT" 1 "DC_CHARGER_PRESENT" 0 "NO_CHARGER_PRESENT" ;
VAL_ 541 CP_gbState 10 "GBDC_CHARGE_DISABLING" 5 "GBDC_CHARGE_PARAM_CONFIG" 8 "GBDC_CHARGING" 2 "GBDC_COMMS_RECEIVED" 11 "GBDC_END_OF_CHARGE" 12 "GBDC_ERROR_HANDLING" 14 "GBDC_FAULTED" 3 "GBDC_HANDSHAKING_EXT_ISO" 0 "GBDC_INACTIVE" 7 "GBDC_READY_TO_CHARGE" 4 "GBDC_RECOGNITION" 13 "GBDC_RETRY_CHARGE" 9 "GBDC_STOP_CHARGE_REQUESTED" 15 "GBDC_TESTER_PRESENT" 6 "GBDC_VEH_PACK_PRECHARGE" 1 "GBDC_WAIT_FOR_COMMS" ;
VAL_ 541 CP_gbdcFailureReason 1 "GBDC_ATTEMPTS_EXPIRED" 3 "GBDC_CRITICAL_FAILURE" 0 "GBDC_FAILURE_NONE" 2 "GBDC_SHUTDOWN_FAILURE" ;
VAL_ 541 CP_gbdcStopChargeReason 3 "GBDC_COMMS_TIMEOUT" 5 "GBDC_EVSE_CRITICAL_FAULT" 4 "GBDC_EVSE_FAULT" 2 "GBDC_EVSE_REQUESTED" 6 "GBDC_LIVE_DISCONNECT" 0 "GBDC_STOP_REASON_NONE" 7 "GBDC_SUPERCHARGER_COMMS_TIMEOUT" 1 "GBDC_VEH_REQUESTED" ;
VAL_ 541 CP_iecComboState 6 "IEC_COMBO_CABLE_CHECK" 5 "IEC_COMBO_CHARGE_PARAM_DISCOVERY" 1 "IEC_COMBO_CONNECTED" 8 "IEC_COMBO_ENABLED" 10 "IEC_COMBO_END_OF_CHARGE" 11 "IEC_COMBO_FAULT" 0 "IEC_COMBO_INACTIVE" 4 "IEC_COMBO_PAYMENT_SELECTION" 7 "IEC_COMBO_PRECHARGE" 3 "IEC_COMBO_SERVICE_DISCOVERY" 9 "IEC_COMBO_SHUTDOWN" 2 "IEC_COMBO_V2G_SESSION_SETUP" 12 "IEC_COMBO_WAIT_RESTART" ;
VAL_ 541 CP_pilot 3 "CHG_PILOT_FAST_CHARGE" 1 "CHG_PILOT_FAULTED" 4 "CHG_PILOT_IDLE" 5 "CHG_PILOT_INVALID" 2 "CHG_PILOT_LINE_CHARGE" 0 "CHG_PILOT_NONE" 7 "CHG_PILOT_SNA" 6 "CHG_PILOT_UNUSED_6" ;
VAL_ 541 CP_proximity 1 "CHG_PROXIMITY_DISCONNECTED" 3 "CHG_PROXIMITY_LATCHED" 0 "CHG_PROXIMITY_SNA" 2 "CHG_PROXIMITY_UNLATCHED" ;
VAL_ 541 CP_teslaDcState 1 "TESLA_DC_CONNECTED_CHARGE_BLOCKED" 9 "TESLA_DC_EMERGENCY_SHUTDOWN" 6 "TESLA_DC_ENABLED" 7 "TESLA_DC_EVSE_SHUTDOWN" 5 "TESLA_DC_EXT_PRECHARGE_ACTIVE" 3 "TESLA_DC_EXT_TESTS_ENABLED" 4 "TESLA_DC_EXT_TEST_ACTIVE" 10 "TESLA_DC_FAULT" 0 "TESLA_DC_INACTIVE" 2 "TESLA_DC_STANDBY" 8 "TESLA_DC_VEH_SHUTDOWN" ;
VAL_ 541 CP_teslaSwcanState 1 "TESLA_SWCAN_ACCEPT" 3 "TESLA_SWCAN_ESTABLISHED" 4 "TESLA_SWCAN_FAULT" 5 "TESLA_SWCAN_GO_TO_SLEEP" 0 "TESLA_SWCAN_INACTIVE" 6 "TESLA_SWCAN_OFFBOARD_UPDATE_IN_PROGRESS" 2 "TESLA_SWCAN_RECEIVE" ;
VAL_ 1859 VCRIGHT_mirrorRecallStatus 2 "RECALL_COMPLETE" 3 "RECALL_INTERRUPTED" 1 "RECALL_IN_PROGRESS" 0 "RECALL_SNA" ;
VAL_ 1859 VCRIGHT_seatRecallStatus 2 "RECALL_COMPLETE" 3 "RECALL_INTERRUPTED" 1 "RECALL_IN_PROGRESS" 0 "RECALL_SNA" ;
VAL_ 1859 VCRIGHT_systemRecallStatus 2 "RECALL_COMPLETE" 3 "RECALL_INTERRUPTED" 1 "RECALL_IN_PROGRESS" 0 "RECALL_SNA" ;
VAL_ 1885 CP_sensorDataSelect 2 "CP_SENSOR_DOOR" 0 "CP_SENSOR_DOOR_COUNTS" 5 "CP_SENSOR_FAULT_LINE" 4 "CP_SENSOR_INDUCTIVE_DOOR" 3 "CP_SENSOR_LATCH" 9 "CP_SENSOR_PILOT" 10 "CP_SENSOR_PILOT2" 1 "CP_SENSOR_PIN_TEMP" 8 "CP_SENSOR_PROX" 11 "CP_SENSOR_PROX_GB" 7 "CP_SENSOR_RAILS" 6 "CP_SENSOR_UHF" ;
VAL_ 1962 HVP_debugMessageMultiplexer 0 "Mux0" 1 "Mux1" 2 "Mux2" 3 "Mux3" 4 "Mux4" 5 "Mux5" 6 "Mux6" ;
VAL_ 1962 HVP_shuntAsicTempDbg -32768 "SHUNT_TEMPERATURE_SNA" ;
VAL_ 1962 HVP_shuntBarTempDbg -32768 "SHUNT_TEMPERATURE_SNA" ;
VAL_ 819 UI_acChargeCurrentLimit 127 "SNA" ;
VAL_ 820 UI_limitMode 2 "LIMIT_FACTORY" 0 "LIMIT_NORMAL" 3 "LIMIT_SERVICE" 1 "LIMIT_VALET" ;
VAL_ 820 UI_motorOnMode 1 "MOTORONMODE_FRONT_ONLY" 0 "MOTORONMODE_NORMAL" 2 "MOTORONMODE_REAR_ONLY" ;
VAL_ 820 UI_pedalMap 0 "CHILL" 2 "PERFORMANCE" 1 "SPORT" ;
VAL_ 820 UI_speedLimit 255 "SNA" ;
VAL_ 820 UI_stoppingMode 1 "CREEP" 2 "HOLD" 0 "STANDARD" ;
VAL_ 820 UI_systemPowerLimit 31 "SNA" ;
VAL_ 820 UI_systemTorqueLimit 63 "SNA" ;
VAL_ 820 UI_wasteMode 2 "WASTE_TYPE_FULL" 0 "WASTE_TYPE_NONE" 1 "WASTE_TYPE_PARTIAL" ;
VAL_ 820 UI_wasteModeRegenLimit 3 "MAX_REGEN_CURRENT_0A" 2 "MAX_REGEN_CURRENT_10A" 1 "MAX_REGEN_CURRENT_30A" 0 "MAX_REGEN_CURRENT_MAX" ;
VAL_ 820 UI_closureConfirmed 1 "CONFIRMED_FRUNK" 0 "CONFIRMED_NONE" 2 "CONFIRMED_PROX" ;
VAL_ 577 VCFRONT_coolantAirPurgeBatState 1 "AIR_PURGE_STATE_ACTIVE" 2 "AIR_PURGE_STATE_COMPLETE" 0 "AIR_PURGE_STATE_INACTIVE" 3 "AIR_PURGE_STATE_INTERRUPTED" 4 "AIR_PURGE_STATE_PENDING" ;
VAL_ 577 VCFRONT_coolantFlowBatReason 4 "ACTIVE_MANAGER_BATT" 9 "ACTIVE_MANAGER_PT" 6 "BMS_FLOW_REQ" 1 "COOLANT_AIR_PURGE" 7 "DAS_FLOW_REQ" 13 "DIS_FLOW_REQ" 12 "DI_FLOW_REQ" 14 "HP_FLOW_REQ" 0 "NONE" 2 "NO_FLOW_REQ" 3 "OVERRIDE_BATT" 8 "OVERRIDE_PT" 5 "PASSIVE_MANAGER_BATT" 10 "PASSIVE_MANAGER_PT" 11 "PCS_FLOW_REQ" ;
VAL_ 577 VCFRONT_coolantFlowPTReason 4 "ACTIVE_MANAGER_BATT" 9 "ACTIVE_MANAGER_PT" 6 "BMS_FLOW_REQ" 1 "COOLANT_AIR_PURGE" 7 "DAS_FLOW_REQ" 13 "DIS_FLOW_REQ" 12 "DI_FLOW_REQ" 14 "HP_FLOW_REQ" 0 "NONE" 2 "NO_FLOW_REQ" 3 "OVERRIDE_BATT" 8 "OVERRIDE_PT" 5 "PASSIVE_MANAGER_BATT" 10 "PASSIVE_MANAGER_PT" 11 "PCS_FLOW_REQ" ;
VAL_ 577 VCFRONT_wasteHeatRequestType 2 "WASTE_TYPE_FULL" 0 "WASTE_TYPE_NONE" 1 "WASTE_TYPE_PARTIAL" ;
VAL_ 708 PCS_logMessageSelect 3 "PCS_LOG_CHG_1" 4 "PCS_LOG_CHG_2" 5 "PCS_LOG_CHG_3" 13 "PCS_LOG_CHG_4" 21 "PCS_LOG_CHG_LINE_OFFSET" 23 "PCS_LOG_CHG_MACHINEMODEL" 20 "PCS_LOG_CHG_NO_FLOW" 6 "PCS_LOG_DCDC_1" 7 "PCS_LOG_DCDC_2" 8 "PCS_LOG_DCDC_3" 18 "PCS_LOG_DCDC_4" 19 "PCS_LOG_DCDC_5" 24 "PCS_LOG_DCDC_HVBUS_PCHG_DATA" 25 "PCS_LOG_DCDC_IMPEDANCE_EST" 22 "PCS_LOG_DCDC_STATISTICS" 14 "PCS_LOG_DLOG_1" 15 "PCS_LOG_DLOG_2" 16 "PCS_LOG_DLOG_3" 17 "PCS_LOG_DLOG_4" 26 "PCS_LOG_NUM_MSGS" 0 "PCS_LOG_PHA_1" 10 "PCS_LOG_PHA_2" 1 "PCS_LOG_PHB_1" 11 "PCS_LOG_PHB_2" 2 "PCS_LOG_PHC_1" 12 "PCS_LOG_PHC_2" 9 "PCS_LOG_SYSTEM_1" ;
VAL_ 708 PCS_acChargeSelfTestState 0 "PCS_SELF_TEST_IDLE" 1 "PCS_SELF_TEST_STARTED" ;
VAL_ 708 PCS_chgAcpwHeartbeatState 2 "PCS_ACPW_HEARTBEAT_STATE_DETECTED" 1 "PCS_ACPW_HEARTBEAT_STATE_NOT_DETECTED" 3 "PCS_ACPW_HEARTBEAT_STATE_NUM" 0 "PCS_ACPW_HEARTBEAT_STATE_UNKNOWN" ;
VAL_ 708 PCS_chgInputFrequencyL1N 0 "FREQUENCY_UNKNOWN" ;
VAL_ 708 PCS_chgInputFrequencyL2N 0 "FREQUENCY_UNKNOWN" ;
VAL_ 708 PCS_chgInputFrequencyL3N 0 "FREQUENCY_UNKNOWN" ;
VAL_ 708 PCS_chgInternalPhaseConfig 5 "PHASE_CONFIG_MFG_TEST_CONFIG_1" 6 "PHASE_CONFIG_MFG_TEST_CONFIG_2" 7 "PHASE_CONFIG_RELIABILITY_SINGLE_PHASE" 1 "PHASE_CONFIG_SINGLE_PHASE" 8 "PHASE_CONFIG_SINGLE_PHASE_EVSE_PARALLEL" 4 "PHASE_CONFIG_SINGLE_PHASE_IEC_GB" 0 "PHASE_CONFIG_SNA" 2 "PHASE_CONFIG_THREE_PHASE" 3 "PHASE_CONFIG_THREE_PHASE_DELTA" 9 "PHASE_CONFIG_TOTAL_NUM" ;
VAL_ 708 PCS_chgPhALastShutdownReason 12 "PCS_PH_SHUTDOWN_CONTROL_REGULATION_FAULT" 16 "PCS_PH_SHUTDOWN_FREQ_OUT_OF_RANGE" 2 "PCS_PH_SHUTDOWN_HW_ENABLE" 4 "PCS_PH_SHUTDOWN_HW_FAULT" 7 "PCS_PH_SHUTDOWN_INPUT_OV" 6 "PCS_PH_SHUTDOWN_INPUT_UV" 11 "PCS_PH_SHUTDOWN_INT_BUS_UV" 17 "PCS_PH_SHUTDOWN_LINE_TRANSIENT_FAULT" 9 "PCS_PH_SHUTDOWN_OUTPUT_OV" 8 "PCS_PH_SHUTDOWN_OUTPUT_UV" 13 "PCS_PH_SHUTDOWN_OVER_TEMPERATURE" 5 "PCS_PH_SHUTDOWN_PLL_NOT_LOCKED" 10 "PCS_PH_SHUTDOWN_PRECHARGE_TIMEOUT" 0 "PCS_PH_SHUTDOWN_REASON_NONE" 15 "PCS_PH_SHUTDOWN_SENSOR_IRRATIONAL" 1 "PCS_PH_SHUTDOWN_SW_ENABLE" 3 "PCS_PH_SHUTDOWN_SW_FAULT" 14 "PCS_PH_SHUTDOWN_TEMP_IRRATIONAL" ;
VAL_ 708 PCS_chgPhAState 5 "PCS_PH_STATE_CLEAR_FAULTS" 3 "PCS_PH_STATE_ENABLE" 4 "PCS_PH_STATE_FAULT" 1 "PCS_PH_STATE_IDLE" 0 "PCS_PH_STATE_INIT" 2 "PCS_PH_STATE_PRECHARGE" 6 "PCS_PH_STATE_SHUTTING_DOWN" ;
VAL_ 708 PCS_chgPhBLastShutdownReason 12 "PCS_PH_SHUTDOWN_CONTROL_REGULATION_FAULT" 16 "PCS_PH_SHUTDOWN_FREQ_OUT_OF_RANGE" 2 "PCS_PH_SHUTDOWN_HW_ENABLE" 4 "PCS_PH_SHUTDOWN_HW_FAULT" 7 "PCS_PH_SHUTDOWN_INPUT_OV" 6 "PCS_PH_SHUTDOWN_INPUT_UV" 11 "PCS_PH_SHUTDOWN_INT_BUS_UV" 17 "PCS_PH_SHUTDOWN_LINE_TRANSIENT_FAULT" 9 "PCS_PH_SHUTDOWN_OUTPUT_OV" 8 "PCS_PH_SHUTDOWN_OUTPUT_UV" 13 "PCS_PH_SHUTDOWN_OVER_TEMPERATURE" 5 "PCS_PH_SHUTDOWN_PLL_NOT_LOCKED" 10 "PCS_PH_SHUTDOWN_PRECHARGE_TIMEOUT" 0 "PCS_PH_SHUTDOWN_REASON_NONE" 15 "PCS_PH_SHUTDOWN_SENSOR_IRRATIONAL" 1 "PCS_PH_SHUTDOWN_SW_ENABLE" 3 "PCS_PH_SHUTDOWN_SW_FAULT" 14 "PCS_PH_SHUTDOWN_TEMP_IRRATIONAL" ;
VAL_ 708 PCS_chgPhBState 5 "PCS_PH_STATE_CLEAR_FAULTS" 3 "PCS_PH_STATE_ENABLE" 4 "PCS_PH_STATE_FAULT" 1 "PCS_PH_STATE_IDLE" 0 "PCS_PH_STATE_INIT" 2 "PCS_PH_STATE_PRECHARGE" 6 "PCS_PH_STATE_SHUTTING_DOWN" ;
VAL_ 708 PCS_chgPhCLastShutdownReason 12 "PCS_PH_SHUTDOWN_CONTROL_REGULATION_FAULT" 16 "PCS_PH_SHUTDOWN_FREQ_OUT_OF_RANGE" 2 "PCS_PH_SHUTDOWN_HW_ENABLE" 4 "PCS_PH_SHUTDOWN_HW_FAULT" 7 "PCS_PH_SHUTDOWN_INPUT_OV" 6 "PCS_PH_SHUTDOWN_INPUT_UV" 11 "PCS_PH_SHUTDOWN_INT_BUS_UV" 17 "PCS_PH_SHUTDOWN_LINE_TRANSIENT_FAULT" 9 "PCS_PH_SHUTDOWN_OUTPUT_OV" 8 "PCS_PH_SHUTDOWN_OUTPUT_UV" 13 "PCS_PH_SHUTDOWN_OVER_TEMPERATURE" 5 "PCS_PH_SHUTDOWN_PLL_NOT_LOCKED" 10 "PCS_PH_SHUTDOWN_PRECHARGE_TIMEOUT" 0 "PCS_PH_SHUTDOWN_REASON_NONE" 15 "PCS_PH_SHUTDOWN_SENSOR_IRRATIONAL" 1 "PCS_PH_SHUTDOWN_SW_ENABLE" 3 "PCS_PH_SHUTDOWN_SW_FAULT" 14 "PCS_PH_SHUTDOWN_TEMP_IRRATIONAL" ;
VAL_ 708 PCS_chgPhCState 5 "PCS_PH_STATE_CLEAR_FAULTS" 3 "PCS_PH_STATE_ENABLE" 4 "PCS_PH_STATE_FAULT" 1 "PCS_PH_STATE_IDLE" 0 "PCS_PH_STATE_INIT" 2 "PCS_PH_STATE_PRECHARGE" 6 "PCS_PH_STATE_SHUTTING_DOWN" ;
VAL_ 708 PCS_chgPhasesPriority 36 "PHASES_PRIORITY_ABC" 24 "PHASES_PRIORITY_ACB" 33 "PHASES_PRIORITY_BAC" 9 "PHASES_PRIORITY_BCA" 18 "PHASES_PRIORITY_CAB" 6 "PHASES_PRIORITY_CBA" 0 "UNDEFINED_PHASES_PRIORITY" ;
VAL_ 708 PCS_cpu2BootState 2 "CPU2_STATE_APPLICATION" 1 "CPU2_STATE_BOOTLOADER" 0 "CPU2_STATE_BOOTROM" 3 "CPU2_STATE_ERROR" ;
VAL_ 708 PCS_dLogPhAChannel1Content 1 "PCS_DLOG_INPUT_CURRENT" 0 "PCS_DLOG_INPUT_VOLTAGE" 3 "PCS_DLOG_INT_BUS_VOLTAGE" 2 "PCS_DLOG_OUTPUT_CURRENT" ;
VAL_ 708 PCS_dLogPhAChannel2Content 1 "PCS_DLOG_INPUT_CURRENT" 0 "PCS_DLOG_INPUT_VOLTAGE" 3 "PCS_DLOG_INT_BUS_VOLTAGE" 2 "PCS_DLOG_OUTPUT_CURRENT" ;
VAL_ 708 PCS_dLogPhAChannel3Content 1 "PCS_DLOG_INPUT_CURRENT" 0 "PCS_DLOG_INPUT_VOLTAGE" 3 "PCS_DLOG_INT_BUS_VOLTAGE" 2 "PCS_DLOG_OUTPUT_CURRENT" ;
VAL_ 708 PCS_dLogPhAChannel4Content 1 "PCS_DLOG_INPUT_CURRENT" 0 "PCS_DLOG_INPUT_VOLTAGE" 3 "PCS_DLOG_INT_BUS_VOLTAGE" 2 "PCS_DLOG_OUTPUT_CURRENT" ;
VAL_ 708 PCS_dLogPhBChannel1Content 1 "PCS_DLOG_INPUT_CURRENT" 0 "PCS_DLOG_INPUT_VOLTAGE" 3 "PCS_DLOG_INT_BUS_VOLTAGE" 2 "PCS_DLOG_OUTPUT_CURRENT" ;
VAL_ 708 PCS_dLogPhBChannel2Content 1 "PCS_DLOG_INPUT_CURRENT" 0 "PCS_DLOG_INPUT_VOLTAGE" 3 "PCS_DLOG_INT_BUS_VOLTAGE" 2 "PCS_DLOG_OUTPUT_CURRENT" ;
VAL_ 708 PCS_dLogPhBChannel3Content 1 "PCS_DLOG_INPUT_CURRENT" 0 "PCS_DLOG_INPUT_VOLTAGE" 3 "PCS_DLOG_INT_BUS_VOLTAGE" 2 "PCS_DLOG_OUTPUT_CURRENT" ;
VAL_ 708 PCS_dLogPhBChannel4Content 1 "PCS_DLOG_INPUT_CURRENT" 0 "PCS_DLOG_INPUT_VOLTAGE" 3 "PCS_DLOG_INT_BUS_VOLTAGE" 2 "PCS_DLOG_OUTPUT_CURRENT" ;
VAL_ 708 PCS_dLogPhCChannel1Content 1 "PCS_DLOG_INPUT_CURRENT" 0 "PCS_DLOG_INPUT_VOLTAGE" 3 "PCS_DLOG_INT_BUS_VOLTAGE" 2 "PCS_DLOG_OUTPUT_CURRENT" ;
VAL_ 708 PCS_dLogPhCChannel2Content 1 "PCS_DLOG_INPUT_CURRENT" 0 "PCS_DLOG_INPUT_VOLTAGE" 3 "PCS_DLOG_INT_BUS_VOLTAGE" 2 "PCS_DLOG_OUTPUT_CURRENT" ;
VAL_ 708 PCS_dLogPhCChannel3Content 1 "PCS_DLOG_INPUT_CURRENT" 0 "PCS_DLOG_INPUT_VOLTAGE" 3 "PCS_DLOG_INT_BUS_VOLTAGE" 2 "PCS_DLOG_OUTPUT_CURRENT" ;
VAL_ 708 PCS_dLogPhCChannel4Content 1 "PCS_DLOG_INPUT_CURRENT" 0 "PCS_DLOG_INPUT_VOLTAGE" 3 "PCS_DLOG_INT_BUS_VOLTAGE" 2 "PCS_DLOG_OUTPUT_CURRENT" ;
VAL_ 708 PCS_dcdcTankVoltage -1024 "TANK_VOLTAGE_SNA" ;
VAL_ 2005 DIR_aebFaultReason 9 "DI_AEB_FAULT_ACCEL_OUT_OF_BOUNDS" 14 "DI_AEB_FAULT_ACCEL_REQ_INVALID" 5 "DI_AEB_FAULT_DAS_CONTROL_MIA" 15 "DI_AEB_FAULT_DAS_REQ_DI_UNAVAIL" 6 "DI_AEB_FAULT_DAS_SNA" 3 "DI_AEB_FAULT_EBR_FAULT" 1 "DI_AEB_FAULT_EPB_MIA" 10 "DI_AEB_FAULT_EPB_NOT_PARKED" 11 "DI_AEB_FAULT_ESP_FAULT" 12 "DI_AEB_FAULT_ESP_MIA" 13 "DI_AEB_FAULT_MIN_TIME_BTWN_EVENTS" 0 "DI_AEB_FAULT_NONE" 2 "DI_AEB_FAULT_PM_MIA" 8 "DI_AEB_FAULT_PM_REQUEST" 4 "DI_AEB_FAULT_SPEED_DELTA" 7 "DI_AEB_FAULT_VEL_EST_ABNORMAL" ;
VAL_ 2005 DIR_aebUnavailableReason 1 "DI_AEB_UNAVAILABLE_CLOSURE" 5 "DI_AEB_UNAVAILABLE_DI_STATE" 6 "DI_AEB_UNAVAILABLE_EBR_UNAVAILABLE" 7 "DI_AEB_UNAVAILABLE_EPB" 2 "DI_AEB_UNAVAILABLE_GEAR" 8 "DI_AEB_UNAVAILABLE_HYSTERESIS" 4 "DI_AEB_UNAVAILABLE_NEGATIVE_SPEED" 0 "DI_AEB_UNAVAILABLE_NONE" 10 "DI_AEB_UNAVAILABLE_REVERSE_SPEED" 3 "DI_AEB_UNAVAILABLE_SKID" 9 "DI_AEB_UNAVAILABLE_TRACK_MODE" ;
VAL_ 2005 DIR_brkStState 6 "BRKST_STATE_FINISHED" 1 "BRKST_STATE_IDLE" 5 "BRKST_STATE_INTERRUPTED" 4 "BRKST_STATE_RUNNING_PRESSED" 3 "BRKST_STATE_RUNNING_PRESSING" 2 "BRKST_STATE_RUNNING_UNPRESSED" 0 "BRKST_STATE_UNAVAILABLE" ;
VAL_ 2005 DIR_fluxState 5 "DI_FLUXSTATE_ENABLED" 9 "DI_FLUXSTATE_FAULT" 4 "DI_FLUXSTATE_FLUX_DOWN" 3 "DI_FLUXSTATE_FLUX_UP" 6 "DI_FLUXSTATE_ICONTROL" 2 "DI_FLUXSTATE_STANDBY" 0 "DI_FLUXSTATE_START" 10 "DI_FLUXSTATE_STATIONARY_WASTE" 1 "DI_FLUXSTATE_TEST" 7 "DI_FLUXSTATE_VCONTROL" ;
VAL_ 2005 DIR_gateDriveState 3 "PSTG_GD_STATE_CONFIGURED" 2 "PSTG_GD_STATE_CONFIGURING" 0 "PSTG_GD_STATE_INIT" 4 "PSTG_GD_STATE_NOT_CONFIGURED" 1 "PSTG_GD_STATE_SELFTEST" ;
VAL_ 2005 DIR_gateDriveSupplyState 0 "PSTG_GD_SUPPLY_DOWN" 3 "PSTG_GD_SUPPLY_FALLING" 1 "PSTG_GD_SUPPLY_RISING" 2 "PSTG_GD_SUPPLY_UP" ;
VAL_ 2005 DIR_immobilizerCondition 1 "DI_IMM_CONDITION_LEARNED" 0 "DI_IMM_CONDITION_VIRGIN_SNA" ;
VAL_ 2005 DIR_magnetTempEst 0 "SNA" ;
VAL_ 2005 DIR_motorType 8 "DI_MOTOR_F1A" 10 "DI_MOTOR_F1AC" 11 "DI_MOTOR_F2AB" 12 "DI_MOTOR_F2AC" 13 "DI_MOTOR_F2AD" 14 "DI_MOTOR_F2AE" 26 "DI_MOTOR_F2AE_AL" 15 "DI_MOTOR_F2APMSRM" 17 "DI_MOTOR_IM100A" 19 "DI_MOTOR_IM100B" 22 "DI_MOTOR_IM130C" 24 "DI_MOTOR_IM130D" 25 "DI_MOTOR_IM130D_AL" 27 "DI_MOTOR_IM130D_AL_POSCO" 20 "DI_MOTOR_IM216A" 3 "DI_MOTOR_M7M3" 4 "DI_MOTOR_M7M4" 5 "DI_MOTOR_M7M5" 7 "DI_MOTOR_M7M6" 6 "DI_MOTOR_M8A" 16 "DI_MOTOR_PM216A" 18 "DI_MOTOR_PM216B" 21 "DI_MOTOR_PM216C" 23 "DI_MOTOR_PM216D" 1 "DI_MOTOR_ROADSTER_BASE" 2 "DI_MOTOR_ROADSTER_SPORT" 0 "DI_MOTOR_SNA" 9 "DI_MOTOR_SSR1A" ;
VAL_ 2005 DIR_oilPumpPhaseVoltage 255 "SNA" ;
VAL_ 2005 DIR_oilPumpPressureEstimateMax 255 "SNA" ;
VAL_ 2005 DIR_oilPumpPressureExpectedMin 255 "SNA" ;
VAL_ 2005 DIR_opdUnavailableReason 1 "DI_OPD_UNAVAILABLE_DISABLED" 4 "DI_OPD_UNAVAILABLE_DI_SYS_STATE" 7 "DI_OPD_UNAVAILABLE_EPB_FAULT" 3 "DI_OPD_UNAVAILABLE_GEAR" 11 "DI_OPD_UNAVAILABLE_GRADE_ESTIMATE" 5 "DI_OPD_UNAVAILABLE_INVALID_BRAKE_SENSE" 14 "DI_OPD_UNAVAILABLE_INVALID_MSPD" 15 "DI_OPD_UNAVAILABLE_MOTOR_HOLD_TIMEOUT" 0 "DI_OPD_UNAVAILABLE_NONE" 13 "DI_OPD_UNAVAILABLE_PARKED" 2 "DI_OPD_UNAVAILABLE_PM_FAULT" 6 "DI_OPD_UNAVAILABLE_SKID" 12 "DI_OPD_UNAVAILABLE_TORQUE_LIMIT" 8 "DI_OPD_UNAVAILABLE_TRACK_MODE" 10 "DI_OPD_UNAVAILABLE_TRACTION_CONTROL" 9 "DI_OPD_UNAVAILABLE_VELOCITY_ESTIMATE" ;
VAL_ 2005 DIR_powerStageSafeState 2 "PSTG_SAFESTATE_3PS_HIGH" 3 "PSTG_SAFESTATE_3PS_LOW" 1 "PSTG_SAFESTATE_ALL_OFF" 0 "PSTG_SAFESTATE_NONE" ;
VAL_ 2005 DIR_rotorOffsetLearningState 9 "ROL_NUM_STATES" 2 "ROL_STATE_ACCELERATE" 5 "ROL_STATE_CORRECT" 8 "ROL_STATE_DONE" 0 "ROL_STATE_INIT" 4 "ROL_STATE_MEASURE" 3 "ROL_STATE_SHIFT" 6 "ROL_STATE_VERIFY" 1 "ROL_STATE_WAIT" 7 "ROL_STATE_WRITE" ;
VAL_ 2005 DIR_ssmState 5 "SSM_STATE_ABORT" 4 "SSM_STATE_ENABLE" 8 "SSM_STATE_FAULT" 2 "SSM_STATE_IDLE" 7 "SSM_STATE_RETRY" 3 "SSM_STATE_STANDBY" 0 "SSM_STATE_START" 1 "SSM_STATE_UNAVAILABLE" 6 "SSM_STATE_WAIT_FOR_RETRY" ;
VAL_ 2005 DIR_tcMaxRequest 255 "SNA" ;
VAL_ 2005 DIR_tcMinRequest 255 "SNA" ;
VAL_ 2005 DIR_usmState 3 "USM_STATE_ABORT" 4 "USM_STATE_ENABLE" 5 "USM_STATE_FAULT" 2 "USM_STATE_RETRY" 1 "USM_STATE_STANDBY" 0 "USM_STATE_START" 6 "USM_STATE_UNAVAILABLE" 7 "USM_STATE_WAIT_FOR_RETRY" ;
VAL_ 2005 DIR_velocityEstimatorState 4 "VE_STATE_BACKUP_MOTOR" 2 "VE_STATE_BACKUP_WHEELS_A" 3 "VE_STATE_BACKUP_WHEELS_B" 0 "VE_STATE_NOT_INITIALIZED" 1 "VE_STATE_WHEELS_NORMAL" ;
